VERSION ""

NS_ :

BS_:

BU_: JetXCI1 Bordrechner4 Bordrechner3 Bordrechner2 Bordrechner1 Hydrop_Joystick JetEIM1_JIM1_2 JetEIM1_JIM1_1 JetEIM1_JIM1_0 Getriebe2 Getriebe1 Getriebe0 Retarder_Motor Motor Bordrechner0 Luefter
VAL_TABLE_ FMI 31 "Not available" 19 "Received network data in error" 18 "Below normal (moderatels severe)" 17 "Below normal (least severe)" 16 "Above normal (moderately severe)" 15 "Above normal (least severe)" 14 "Special intstructions" 13 "Out of calibration" 12 "Bad intelligent device" 11 "Root cause not known" 10 "Abnormal rate of change" 9 "Abnormal update rate" 8 "Abnormal frequency" 7 "Mechanical system not responding" 6 "Current above normal" 5 "Current below normal" 4 "Voltage below normal" 3 "Voltage above normal" 2 "Data erratic" 1 "Below normal (most severe)" 0 "Above normal (most severe)" ;
VAL_TABLE_ VehicleSystem_IG1 2 "Trailer" 1 "Tractor" 127 "Not Available" 0 "Non-specific System" ;
VAL_TABLE_ VehicleSystem_IG0 0 "Non-specific System" 127 "Not Available" ;
VAL_TABLE_ VehicleSystem_IG5 127 "Not Available" 0 "Ind. Process Control Stationary" ;
VAL_TABLE_ VehicleSystem_IG4 100 "Deck/Cargo/Fishing equip. sys" 90 "Environmental (HVAC) Systems" 80 "Instrumentation/General Systems" 70 "Communications Systems" 60 "Navigation Systems" 50 "Propulsion Systems" 40 "Steering Systems" 30 "Power Mgmt and lighting systems" 25 "Gateway" 20 "Safety Systems" 10 "System Tools" 127 "Not Available" 0 "Non-specific System" ;
VAL_TABLE_ VehicleSystem_IG3 8 "Grader" 7 "Four Wheel Drive Loader" 6 "Forklift" 5 "Excavator" 4 "Crawler" 3 "Backhoe" 2 "Articulated Dump Truck" 1 "Skid Steer Loader" 127 "Not Available" 0 "Non-specific System" ;
VAL_TABLE_ VehicleSystem_IG2 16 "Skidder" 15 "Earth Work" 14 "Special Crops" 13 "Powered Auxiliary Device" 12 "Farm Yard Operations" 11 "Transport/Trailer" 10 "Irrigation" 9 "Forage" 8 "Root Harvesters" 7 "Harvesters" 6 "Sprayers" 5 "Fertilizers" 4 "Planters/Seeders" 3 "Secondary Tillage" 2 "Tillage" 1 "Tractor" 127 "Not Available" 0 "Non-specific System" ;

BO_ 3221225472 VECTOR__INDEPENDENT_SIG_MSG: 0 Vector__XXX
 SG_ MessageCounter : 0|4@1+ (1,0) [0|0] "" Vector__XXX
 SG_ MessageChecksum : 0|4@1+ (1,0) [0|0] "" Vector__XXX
 SG_ NeuesSignal_536 : 0|8@1- (1,0) [0|0] "" Vector__XXX
 SG_ OverTemperatureWarningFlag : 0|2@1+ (1,0) [0|0] "" Vector__XXX
 SG_ Gear_oil_temperature_limit_L : 0|1@1+ (1,0) [0|0] "" Vector__XXX
 SG_ ExhaustGasMass : 0|16@1+ (2,0) [0|128510] "kg" Vector__XXX
 SG_ AftrTrtmntIntakeDewPointMessage : 0|2@1+ (1,0) [0|3] "" Vector__XXX
 SG_ AftrTrtmntExhustDewPointMessage : 0|2@1+ (1,0) [0|3] "" Vector__XXX
 SG_ EngTurboBoostPress : 0|8@1+ (2,0) [0|500] "kPa" Vector__XXX
 SG_ DTC5 : 0|32@1+ (1,0) [0|4294967295] "" Vector__XXX
 SG_ DTC4 : 0|32@1+ (1,0) [0|4294967295] "" Vector__XXX
 SG_ DTC3 : 0|32@1+ (1,0) [0|4294967295] "" Vector__XXX
 SG_ DTC2 : 0|32@1+ (1,0) [0|4294967295] "" Vector__XXX
 SG_ DTC1 : 0|32@1+ (1,0) [0|4294967295] "" Vector__XXX
 SG_ ExhaustGasMass : 0|16@1+ (2,0) [0|128510] "kg" Vector__XXX
 SG_ AftrTrtmntIntakeDewPointMessage : 0|2@1+ (1,0) [0|3] "" Vector__XXX
 SG_ AftrTrtmntExhustDewPointMessage : 0|2@1+ (1,0) [0|3] "" Vector__XXX
 SG_ EstEngPrsticLossesPercentTorque : 0|8@1+ (1,-125) [-125|125] "%" Vector__XXX
 SG_ EngsDsrdOprtngSpdAsymmtryAdjstmn : 0|8@1+ (1,0) [0|250] "" Vector__XXX
 SG_ EngsDesiredOperatingSpeed : 0|16@1+ (0.125,0) [0|8031.875] "RPM" Vector__XXX
 SG_ NominalFrictionPercentTorque : 0|8@1+ (1,-125) [-125|125] "%" Vector__XXX
 SG_ ExhaustGasMass : 0|16@1+ (2,0) [0|128510] "kg" Vector__XXX
 SG_ AftrTrtmntIntakeDewPointMessage : 0|2@1+ (1,0) [0|3] "" Vector__XXX
 SG_ AftrTrtmntExhustDewPointMessage : 0|2@1+ (1,0) [0|3] "" Vector__XXX
 SG_ EstEngPrsticLossesPercentTorque : 0|8@1+ (1,-125) [-125|125] "%" Vector__XXX
 SG_ EngsDsrdOprtngSpdAsymmtryAdjstmn : 0|8@1+ (1,0) [0|250] "" Vector__XXX
 SG_ EngsDesiredOperatingSpeed : 0|16@1+ (0.125,0) [0|8031.875] "RPM" Vector__XXX
 SG_ NominalFrictionPercentTorque : 0|8@1+ (1,-125) [-125|125] "%" Vector__XXX
 SG_ AddressAcknowledged : 0|8@1+ (1,0) [0|255] "" Vector__XXX
 SG_ OperatorPTOMemorySelectSwitch : 0|2@1+ (1,0) [0|3] "" Vector__XXX
 SG_ EngPTOAccelerateSwitch : 0|2@1+ (1,0) [0|3] "" Vector__XXX
 SG_ EngPTOResumeSwitch : 0|2@1+ (1,0) [0|3] "" Vector__XXX
 SG_ EngPTOCoast_DecelerateSwitch : 0|2@1+ (1,0) [0|3] "" Vector__XXX
 SG_ EngRmtPTOVriableSpeedCtrlSwitch : 0|2@1+ (1,0) [0|3] "" Vector__XXX
 SG_ EngRmtPTOPrprgrmmdSpdCtrlSwitch : 0|2@1+ (1,0) [0|3] "" Vector__XXX
 SG_ PowerTakeoffSetSpeed : 0|16@1+ (0.125,0) [0|8031.875] "RPM" Vector__XXX
 SG_ PowerTakeoffSpeed : 0|16@1+ (0.125,0) [0|8031.875] "RPM" Vector__XXX
 SG_ PowerTakeoffOilTemp : 0|8@1+ (1,-40) [-40|210] "�C" Vector__XXX
 SG_ RmtPTOPrprgrmmdSpeedCtrlSwitch2 : 0|2@1+ (1,0) [0|3] "" Vector__XXX
 SG_ AuxInputIgnoreSwitch : 0|2@1+ (1,0) [0|3] "" Vector__XXX
 SG_ Make : 0|8@1+ (1,0) [0|255] "" Vector__XXX
 SG_ DTC1 : 0|32@1+ (1,0) [0|4294967295] "" Vector__XXX

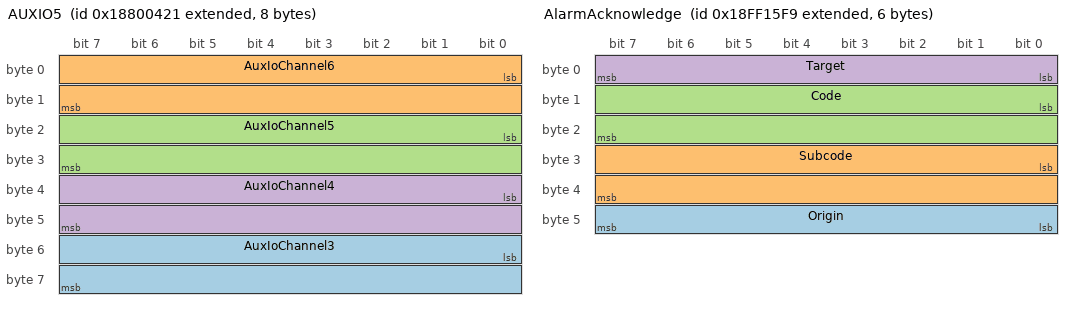
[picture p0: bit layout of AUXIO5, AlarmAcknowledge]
BO_ 2558526497 AUXIO5: 8 Bordrechner0
 SG_ AuxIoChannel3 : 48|16@1+ (1,0) [0|65535] ""  Getriebe1
 SG_ AuxIoChannel6 : 0|16@1+ (1,0) [0|0] ""  Getriebe1
 SG_ AuxIoChannel5 : 16|16@1+ (1,0) [0|65535] ""  Getriebe1
 SG_ AuxIoChannel4 : 32|16@1+ (1,0) [0|65535] ""  Getriebe1

BO_ 2364535040 KWP: 2 Motor
 SG_ Instruction : 8|8@1+ (1,0) [0|0] ""  Motor,Bordrechner4,Bordrechner3,Bordrechner2,Bordrechner1
 SG_ DestinationIdentifier : 0|8@1+ (1,0) [0|0] ""  Motor,Bordrechner4,Bordrechner3,Bordrechner2,Bordrechner1

BO_ 2364538622 ESS: 1 Vector__XXX
 SG_ ShutDownOverride : 8|2@1+ (1,0) [0|3] "" Vector__XXX
 SG_ EngineStart : 2|2@1+ (1,0) [0|0] "" Vector__XXX
 SG_ InhibitFuelInjection : 0|2@1+ (1,0) [0|3] "" Vector__XXX
 SG_ InhibitEngineStart : 4|2@1+ (1,0) [0|0] "" Vector__XXX

BO_ 2564488958 BODAS: 8 Luefter

BO_ 2365534851 JoystickAuxiliaryInput: 1 Hydrop_Joystick
 SG_ Pushbutton2 : 2|2@1+ (1,0) [0|3] ""  JetXCI1
 SG_ Pushbutton1 : 0|2@1+ (1,0) [0|0] ""  JetXCI1

BO_ 2566854398 EnumerateSystem: 8 Bordrechner1

BO_ 2566854137 AlarmAcknowledge: 6 Bordrechner1
 SG_ Origin : 40|8@1+ (1,0) [0|0] ""  JetXCI1,JetEIM1_JIM1_2,JetEIM1_JIM1_1,JetEIM1_JIM1_0
 SG_ Subcode : 24|16@1+ (1,0) [0|65535] ""  JetXCI1,JetEIM1_JIM1_2,JetEIM1_JIM1_1,JetEIM1_JIM1_0
 SG_ Code : 8|16@1+ (1,0) [0|65535] ""  JetXCI1,JetEIM1_JIM1_2,JetEIM1_JIM1_1,JetEIM1_JIM1_0
 SG_ Target : 0|8@1+ (1,0) [0|0] ""  JetXCI1,JetEIM1_JIM1_2,JetEIM1_JIM1_1,JetEIM1_JIM1_0

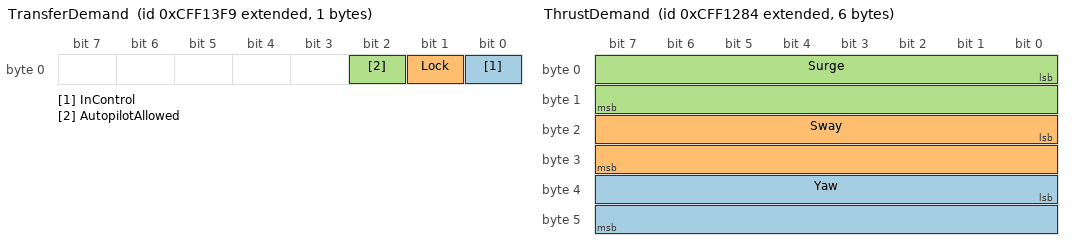
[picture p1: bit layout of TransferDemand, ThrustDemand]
BO_ 2365527033 TransferDemand: 1 Bordrechner1
 SG_ InControl : 0|1@1+ (1,0) [0|1] "" Vector__XXX
 SG_ Lock : 1|1@1+ (1,0) [0|0] "" Vector__XXX
 SG_ AutopilotAllowed : 2|1@1+ (1,0) [0|0] "" Vector__XXX

BO_ 2365527038 TransmissionDemand: 2 Vector__XXX
 SG_ Position : 8|4@1+ (1,0) [0|0] "" Vector__XXX
 SG_ Target : 0|8@1+ (1,0) [0|0] "" Vector__XXX

BO_ 2365526660 ThrustDemand: 6 Hydrop_Joystick
 SG_ Yaw : 32|16@1+ (0.0030517,-100) [0|0] ""  JetXCI1
 SG_ Sway : 16|16@1+ (1,0) [0|0] ""  JetXCI1
 SG_ Surge : 0|16@1+ (0.0030517,-100) [0|0] ""  JetXCI1

BO_ 2365526224 WaterjetReverseDemand: 4 JetXCI1
 SG_ PositionPercent : 8|16@1+ (0.0030517,-100) [-100|100] ""  JetEIM1_JIM1_2,JetEIM1_JIM1_1,JetEIM1_JIM1_0
 SG_ Target : 0|8@1+ (1,0) [0|0] ""  JetEIM1_JIM1_2,JetEIM1_JIM1_1,JetEIM1_JIM1_0

BO_ 2365525968 WaterjetSteeringDemand: 3 JetXCI1
 SG_ PositionPercent : 8|16@1+ (0.0030517,-100) [-100|100] ""  JetEIM1_JIM1_2,JetEIM1_JIM1_1,JetEIM1_JIM1_0
 SG_ Target : 0|8@1+ (1,0) [0|0] ""  JetEIM1_JIM1_2,JetEIM1_JIM1_1,JetEIM1_JIM1_0

BO_ 2365526480 EngineDemand: 4 JetXCI1
 SG_ PositionPercent : 8|16@1+ (0.0030517,-100) [-100|100] ""  JetEIM1_JIM1_2,JetEIM1_JIM1_1,JetEIM1_JIM1_0
 SG_ Target : 0|8@1+ (1,0) [0|0] ""  JetEIM1_JIM1_2,JetEIM1_JIM1_1,JetEIM1_JIM1_0

BO_ 2566852304 AlarmText: 9 JetEIM1_JIM1_0
 SG_ Text : 40|24@1+ (1,0) [0|0] "" Vector__XXX
 SG_ Origin : 32|8@1+ (1,0) [0|0] ""  Bordrechner4,Bordrechner3,Bordrechner2,Bordrechner1,Bordrechner0
 SG_ Subcode : 16|16@1+ (1,0) [0|65535] ""  Bordrechner4,Bordrechner3,Bordrechner2,Bordrechner1,Bordrechner0
 SG_ Code : 0|16@1+ (1,0) [0|65535] ""  Bordrechner4,Bordrechner3,Bordrechner2,Bordrechner1,Bordrechner0

BO_ 2499743184 Alarm: 9 JetEIM1_JIM1_0
 SG_ Severity : 40|4@1+ (1,0) [0|0] ""  Bordrechner4,Bordrechner3,Bordrechner2,Bordrechner1,Bordrechner0
 SG_ Acknowledged : 44|1@1+ (1,0) [0|0] ""  Bordrechner4,Bordrechner3,Bordrechner2,Bordrechner1,Bordrechner0
 SG_ Cleared : 45|1@1+ (1,0) [0|0] ""  Bordrechner4,Bordrechner3,Bordrechner2,Bordrechner1,Bordrechner0
 SG_ Silenced : 46|1@1+ (1,0) [0|0] ""  Bordrechner4,Bordrechner3,Bordrechner2,Bordrechner1,Bordrechner0
 SG_ Retriggered : 47|1@1+ (1,0) [0|0] ""  Bordrechner4,Bordrechner3,Bordrechner2,Bordrechner1,Bordrechner0
 SG_ Origin : 32|8@1+ (1,0) [0|0] ""  Bordrechner4,Bordrechner3,Bordrechner2,Bordrechner1,Bordrechner0
 SG_ Subcode : 16|16@1+ (1,0) [0|65535] ""  Bordrechner4,Bordrechner3,Bordrechner2,Bordrechner1,Bordrechner0
 SG_ Code : 0|16@1+ (1,0) [0|65535] ""  Bordrechner4,Bordrechner3,Bordrechner2,Bordrechner1,Bordrechner0

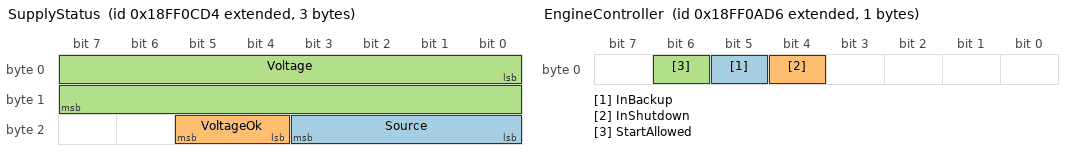
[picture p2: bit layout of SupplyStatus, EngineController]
BO_ 2566851796 SupplyStatus: 3 JetEIM1_JIM1_1
 SG_ Source : 16|4@1+ (1,0) [0|0] "" Vector__XXX
 SG_ VoltageOk : 20|2@1+ (1,0) [0|3] "" Vector__XXX
 SG_ Voltage : 0|16@1+ (0.05,0) [0|0] "V" Vector__XXX

BO_ 2566851286 EngineController: 1 JetEIM1_JIM1_2
 SG_ InBackup : 5|1@1+ (1,0) [0|1] "" Vector__XXX
 SG_ InShutdown : 4|1@1+ (1,0) [0|1] "" Vector__XXX
 SG_ StartAllowed : 6|1@1+ (1,0) [0|1] "" Vector__XXX

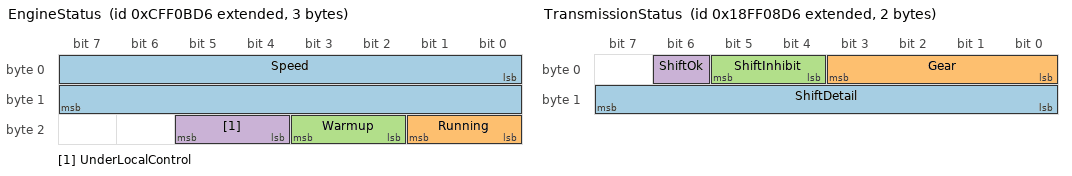
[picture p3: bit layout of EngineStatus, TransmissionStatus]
BO_ 2365524950 EngineStatus: 3 JetEIM1_JIM1_2
 SG_ Speed : 0|16@1+ (0.125,0) [0|0] "RPM" Vector__XXX
 SG_ Running : 16|2@1+ (1,0) [0|3] "" Vector__XXX
 SG_ Warmup : 18|2@1+ (1,0) [0|3] "" Vector__XXX
 SG_ UnderLocalControl : 20|2@1+ (1,0) [0|0] "" Vector__XXX

BO_ 2365524436 ShaftStatus: 3 JetEIM1_JIM1_1
 SG_ Direction : 16|4@1+ (1,0) [0|0] "" Vector__XXX
 SG_ Speed : 0|16@1+ (0.125,0) [0|0] "RPM" Vector__XXX

BO_ 2566850774 TransmissionStatus: 2 JetEIM1_JIM1_2
 SG_ ShiftDetail : 8|8@1+ (1,0) [0|0] "" Vector__XXX
 SG_ Gear : 0|4@1+ (1,0) [0|0] "" Vector__XXX
 SG_ ShiftInhibit : 4|2@1+ (1,0) [0|0] "" Vector__XXX
 SG_ ShiftOk : 6|1@1+ (1,0) [0|1] "" Vector__XXX

BO_ 2566850516 WaterjetController: 1 JetEIM1_JIM1_1
 SG_ InBackup : 0|1@1+ (1,0) [0|1] "" Vector__XXX

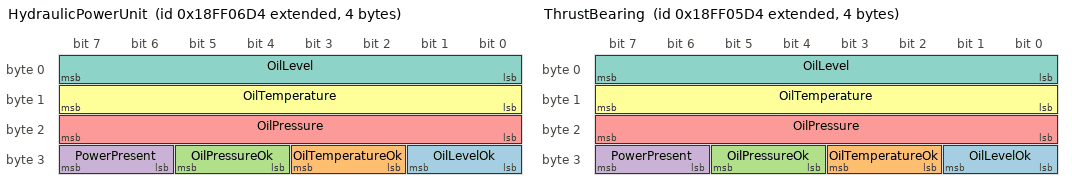
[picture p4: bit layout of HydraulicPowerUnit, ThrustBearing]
BO_ 2566850260 HydraulicPowerUnit: 4 JetEIM1_JIM1_1
 SG_ OilLevelOk : 24|2@1+ (1,0) [0|3] "" Vector__XXX
 SG_ OilTemperatureOk : 26|2@1+ (1,0) [0|3] "" Vector__XXX
 SG_ OilPressureOk : 28|2@1+ (1,0) [0|0] "" Vector__XXX
 SG_ PowerPresent : 30|2@1+ (1,0) [0|3] "" Vector__XXX
 SG_ OilPressure : 16|8@1- (0.1,0) [0|0] "kPa" Vector__XXX
 SG_ OilTemperature : 8|8@1- (1,-40) [0|0] "�C" Vector__XXX
 SG_ OilLevel : 0|8@1+ (1,0) [0|250] "%" Vector__XXX

BO_ 2566850004 ThrustBearing: 4 JetEIM1_JIM1_1
 SG_ OilLevelOk : 24|2@1+ (1,0) [0|3] "" Vector__XXX
 SG_ OilTemperatureOk : 26|2@1+ (1,0) [0|3] "" Vector__XXX
 SG_ OilPressureOk : 28|2@1+ (1,0) [0|0] "" Vector__XXX
 SG_ PowerPresent : 30|2@1+ (1,0) [0|3] "" Vector__XXX
 SG_ OilPressure : 16|8@1- (0.1,0) [0|0] "kPa" Vector__XXX
 SG_ OilTemperature : 8|8@1- (1,-40) [0|0] "�C" Vector__XXX
 SG_ OilLevel : 0|8@1+ (1,0) [0|250] "%" Vector__XXX

BO_ 2365523156 WaterjetReverseStatus: 4 JetEIM1_JIM1_1
 SG_ PositionPercent : 0|16@1+ (0.0030517,-100) [-100|100] "" Vector__XXX
 SG_ LinearPosition : 16|16@1+ (0.0030517,-100) [0|0] "%" Vector__XXX

BO_ 2365522900 WaterjetSteeringStatus: 2 JetEIM1_JIM1_1
 SG_ PositionPercent : 0|16@1+ (0.0030517,-100) [-100|100] "" Vector__XXX

BO_ 2566849232 AutopilotStatus: 4 JetXCI1
 SG_ Engaged : 16|2@1+ (1,0) [0|3] ""  Bordrechner4,Bordrechner3,Bordrechner2,Bordrechner1
 SG_ Order : 0|16@1+ (0.0030517,-100) [-100|99.9931595] "%"  Bordrechner4,Bordrechner3,Bordrechner2,Bordrechner1

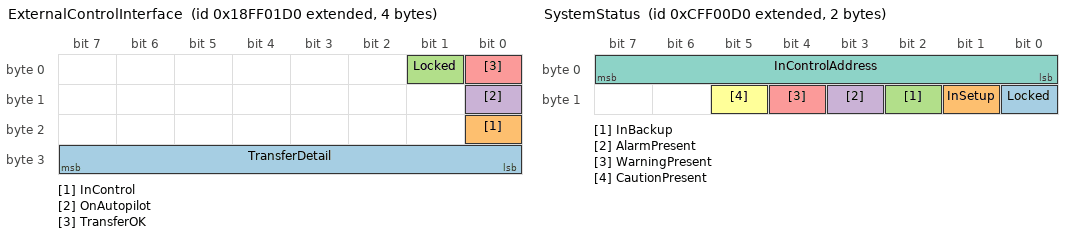
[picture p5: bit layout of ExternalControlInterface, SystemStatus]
BO_ 2566848976 ExternalControlInterface: 4 JetXCI1
 SG_ TransferDetail : 24|8@1+ (1,0) [0|255] ""  Bordrechner4,Bordrechner3,Bordrechner2,Bordrechner1
 SG_ InControl : 16|1@1+ (1,0) [0|1] ""  Bordrechner4,Bordrechner3,Bordrechner2,Bordrechner1
 SG_ Locked : 1|1@1+ (1,0) [0|1] ""  Bordrechner4,Bordrechner3,Bordrechner2,Bordrechner1
 SG_ OnAutopilot : 8|1@1+ (1,0) [0|1] ""  Bordrechner4,Bordrechner3,Bordrechner2,Bordrechner1
 SG_ TransferOK : 0|1@1+ (1,0) [0|1] ""  Bordrechner4,Bordrechner3,Bordrechner2,Bordrechner1

BO_ 2365522128 SystemStatus: 2 JetXCI1
 SG_ Locked : 8|1@1+ (1,0) [0|1] ""  Bordrechner4,Bordrechner3,Bordrechner2,Bordrechner1
 SG_ InSetup : 9|1@1+ (1,0) [0|1] ""  Bordrechner4,Bordrechner3,Bordrechner2,Bordrechner1
 SG_ InBackup : 10|1@1+ (1,0) [0|1] ""  Bordrechner4,Bordrechner3,Bordrechner2,Bordrechner1
 SG_ AlarmPresent : 11|1@1+ (1,0) [0|1] ""  Bordrechner4,Bordrechner3,Bordrechner2,Bordrechner1
 SG_ WarningPresent : 12|1@1+ (1,0) [0|1] ""  Bordrechner4,Bordrechner3,Bordrechner2,Bordrechner1
 SG_ CautionPresent : 13|1@1+ (1,0) [0|0] ""  Bordrechner4,Bordrechner3,Bordrechner2,Bordrechner1
 SG_ InControlAddress : 0|8@1+ (1,0) [0|251] ""  Bordrechner4,Bordrechner3,Bordrechner2,Bordrechner1

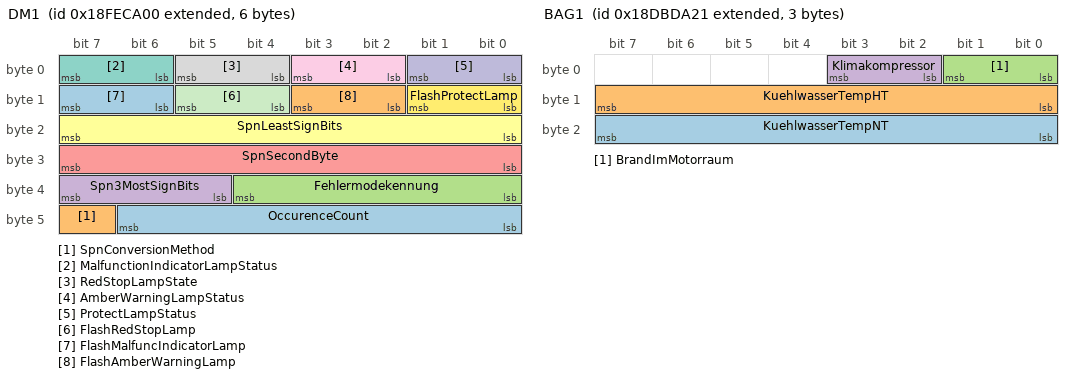
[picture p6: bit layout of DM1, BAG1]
BO_ 2566834688 DM1: 6 Motor
 SG_ OccurenceCount : 40|7@1+ (1,0) [0|0] ""  Bordrechner0
 SG_ SpnConversionMethod : 47|1@1+ (1,0) [0|0] ""  Bordrechner0
 SG_ Fehlermodekennung : 32|5@1+ (1,0) [0|0] ""  Bordrechner0
 SG_ Spn3MostSignBits : 37|3@1+ (1,0) [0|0] ""  Bordrechner0
 SG_ SpnSecondByte : 24|8@1+ (1,0) [0|255] ""  Bordrechner0
 SG_ SpnLeastSignBits : 16|8@1+ (1,0) [0|255] ""  Bordrechner0
 SG_ MalfunctionIndicatorLampStatus : 6|2@1+ (1,0) [0|3] "" Vector__XXX
 SG_ RedStopLampState : 4|2@1+ (1,0) [0|3] ""  Bordrechner0
 SG_ AmberWarningLampStatus : 2|2@1+ (1,0) [0|3] ""  Bordrechner0
 SG_ ProtectLampStatus : 0|2@1+ (1,0) [0|3] "" Vector__XXX
 SG_ FlashRedStopLamp : 12|2@1+ (1,0) [0|3] "" Vector__XXX
 SG_ FlashProtectLamp : 8|2@1+ (1,0) [0|3] "" Vector__XXX
 SG_ FlashMalfuncIndicatorLamp : 14|2@1+ (1,0) [0|3] "" Vector__XXX
 SG_ FlashAmberWarningLamp : 10|2@1+ (1,0) [0|3] "" Vector__XXX

BO_ 2564545057 BAG1: 3 Bordrechner0
 SG_ KuehlwasserTempNT : 16|8@1+ (1,-40) [-40|210] "�C"  Luefter
 SG_ KuehlwasserTempHT : 8|8@1- (1,-40) [-40|210] "�C"  Luefter
 SG_ BrandImMotorraum : 0|2@1+ (1,0) [0|3] ""  Luefter
 SG_ Klimakompressor : 2|2@1+ (1,0) [0|3] ""  Luefter

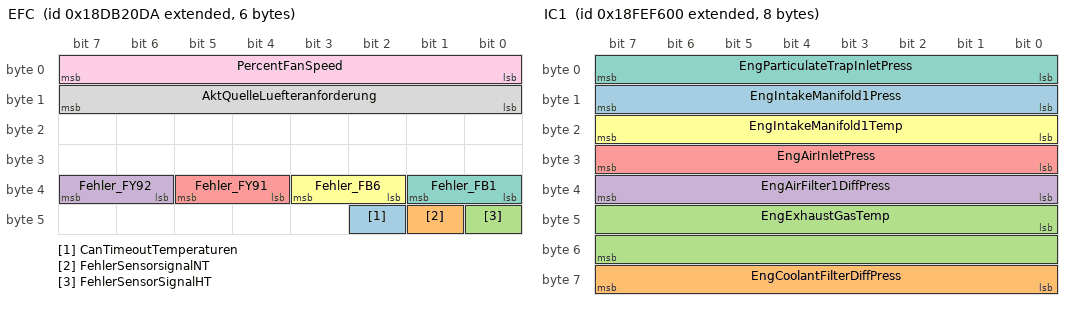
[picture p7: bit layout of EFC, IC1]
BO_ 2564497626 EFC: 6 Luefter
 SG_ CanTimeoutTemperaturen : 42|1@1+ (1,0) [0|1] ""  Bordrechner0
 SG_ FehlerSensorsignalNT : 41|1@1+ (1,0) [0|1] ""  Bordrechner0
 SG_ FehlerSensorSignalHT : 40|1@1+ (1,0) [0|1] ""  Bordrechner0
 SG_ Fehler_FY92 : 38|2@1+ (1,0) [0|3] ""  Bordrechner0
 SG_ Fehler_FY91 : 36|2@1+ (1,0) [0|3] ""  Bordrechner0
 SG_ Fehler_FB6 : 34|2@1+ (1,0) [0|3] ""  Bordrechner0
 SG_ Fehler_FB1 : 32|2@1+ (1,0) [0|3] ""  Bordrechner0
 SG_ AktQuelleLuefteranforderung : 8|8@1+ (1,0) [0|255] ""  Bordrechner0
 SG_ PercentFanSpeed : 0|8@1+ (0.4,0) [0|100] "%"  Bordrechner0

BO_ 2566845952 IC1: 8 Motor
 SG_ EngIntakeManifold1Press : 8|8@1- (2,0) [0|0] "kPa" Vector__XXX
 SG_ EngCoolantFilterDiffPress : 56|8@1+ (0.5,0) [0|125] "kPa" Vector__XXX
 SG_ EngExhaustGasTemp : 40|16@1+ (0.03125,-273) [-273|1735] "�C" Vector__XXX
 SG_ EngAirFilter1DiffPress : 32|8@1+ (0.05,0) [0|12.5] "kPa" Vector__XXX
 SG_ EngAirInletPress : 24|8@1+ (2,0) [0|500] "kPa" Vector__XXX
 SG_ EngIntakeManifold1Temp : 16|8@1+ (1,-40) [-40|210] "�C"  Luefter
 SG_ EngParticulateTrapInletPress : 0|8@1+ (0.5,0) [0|125] "kPa" Vector__XXX

BO_ 2566841854 HOURS: 8 Motor
 SG_ EngTotalRevolutions : 32|32@1+ (1000,0) [0|4211081215000] "rev" Vector__XXX
 SG_ EngTotalHoursOfOperation : 0|32@1+ (0.05,0) [0|210554060.75] "hr" Vector__XXX

BO_ 2566832638 VDHR: 8 Vector__XXX
 SG_ HighResolutionTripDistance : 32|32@1+ (0.005,0) [0|21055406] "km" Vector__XXX
 SG_ HghRslutionTotalVehicleDistance : 0|32@1+ (0.005,0) [0|21055406] "km" Vector__XXX

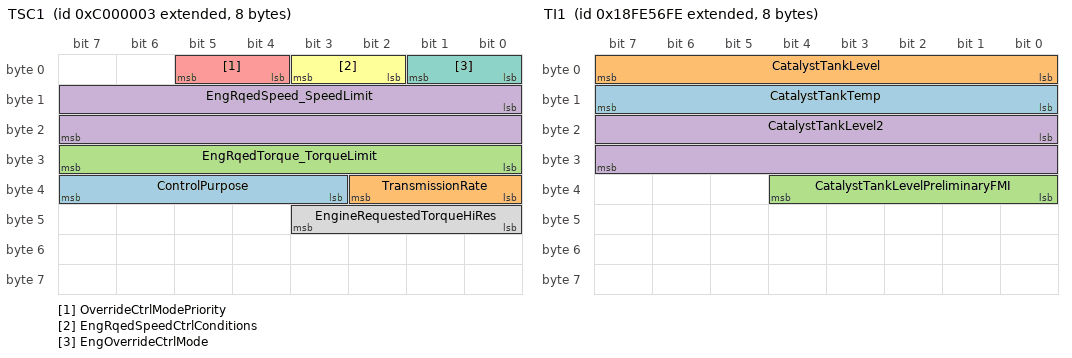
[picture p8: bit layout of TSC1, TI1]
BO_ 2348810243 TSC1: 8 Getriebe0
 SG_ ControlPurpose : 35|5@1+ (1,0) [0|31] ""  Getriebe0,Retarder_Motor,Motor
 SG_ TransmissionRate : 32|3@1+ (1,0) [0|7] ""  Getriebe0,Retarder_Motor,Motor
 SG_ EngRqedTorque_TorqueLimit : 24|8@1+ (1,-125) [-125|125] "%"  Getriebe0,Retarder_Motor,Motor
 SG_ EngRqedSpeed_SpeedLimit : 8|16@1+ (0.125,0) [0|8031.875] "RPM"  Getriebe0,Retarder_Motor,Motor
 SG_ OverrideCtrlModePriority : 4|2@1+ (1,0) [0|3] ""  Getriebe0,Retarder_Motor,Motor
 SG_ EngRqedSpeedCtrlConditions : 2|2@1+ (1,0) [0|3] ""  Getriebe0,Retarder_Motor,Motor
 SG_ EngOverrideCtrlMode : 0|2@1+ (1,0) [0|3] ""  Getriebe0,Retarder_Motor,Motor
 SG_ EngineRequestedTorqueHiRes : 40|4@1+ (0.125,0) [0|0.875] "%"  Getriebe0,Retarder_Motor,Motor

BO_ 2566805246 TI1: 8 Motor
 SG_ CatalystTankTemp : 8|8@1+ (1,-40) [-40|210] "�C" Vector__XXX
 SG_ CatalystTankLevel : 0|8@1+ (0.4,0) [0|100] "%" Vector__XXX
 SG_ CatalystTankLevelPreliminaryFMI : 32|5@1+ (1,0) [0|31] "" Vector__XXX
 SG_ CatalystTankLevel2 : 16|16@1+ (0.1,0) [0|6425.5] "mm" Vector__XXX

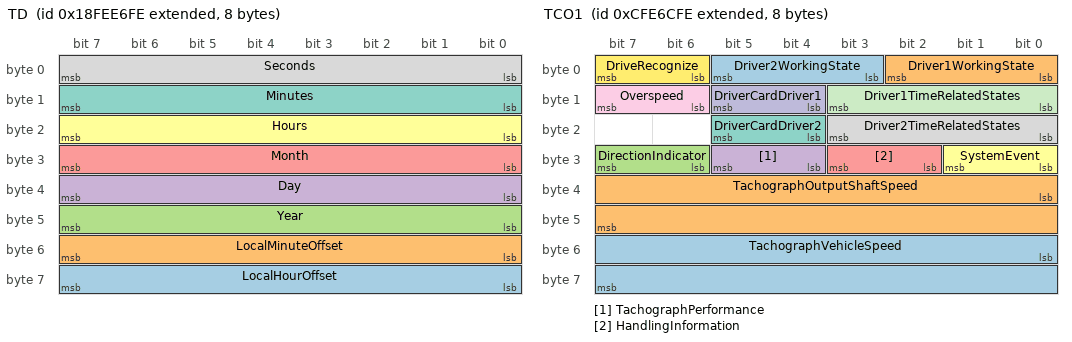
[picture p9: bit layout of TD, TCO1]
BO_ 2566842110 TD: 8 Bordrechner0
 SG_ LocalHourOffset : 56|8@1+ (1,-125) [-125|125] "hr" Vector__XXX
 SG_ LocalMinuteOffset : 48|8@1+ (1,-125) [-125|125] "mins" Vector__XXX
 SG_ Year : 40|8@1+ (1,1985) [1985|2235] "years"  Getriebe0
 SG_ Day : 32|8@1+ (0.25,0) [0|62.5] "days"  Getriebe0
 SG_ Month : 24|8@1+ (1,0) [0|250] "months"  Getriebe0
 SG_ Hours : 16|8@1+ (1,0) [0|250] "hr"  Getriebe0
 SG_ Minutes : 8|8@1+ (1,0) [0|250] "mins"  Getriebe0
 SG_ Seconds : 0|8@1+ (0.25,0) [0|62.5] "sec"  Getriebe0

BO_ 2365484286 TCO1: 8 Vector__XXX
 SG_ TachographVehicleSpeed : 48|16@1+ (0.00390625,0) [0|250.996] "km/hr" Vector__XXX
 SG_ TachographOutputShaftSpeed : 32|16@1+ (0.125,0) [0|8031.875] "RPM" Vector__XXX
 SG_ DirectionIndicator : 30|2@1+ (1,0) [0|3] "" Vector__XXX
 SG_ TachographPerformance : 28|2@1+ (1,0) [0|3] "" Vector__XXX
 SG_ HandlingInformation : 26|2@1+ (1,0) [0|3] "" Vector__XXX
 SG_ SystemEvent : 24|2@1+ (1,0) [0|3] "" Vector__XXX
 SG_ DriverCardDriver2 : 20|2@1+ (1,0) [0|3] "" Vector__XXX
 SG_ Driver2TimeRelatedStates : 16|4@1+ (1,0) [0|15] "" Vector__XXX
 SG_ Overspeed : 14|2@1+ (1,0) [0|3] "" Vector__XXX
 SG_ DriverCardDriver1 : 12|2@1+ (1,0) [0|3] "" Vector__XXX
 SG_ Driver1TimeRelatedStates : 8|4@1+ (1,0) [0|15] "" Vector__XXX
 SG_ DriveRecognize : 6|2@1+ (1,0) [0|3] "" Vector__XXX
 SG_ Driver2WorkingState : 3|3@1+ (1,0) [0|7] "" Vector__XXX
 SG_ Driver1WorkingState : 0|3@1+ (1,0) [0|7] "" Vector__XXX

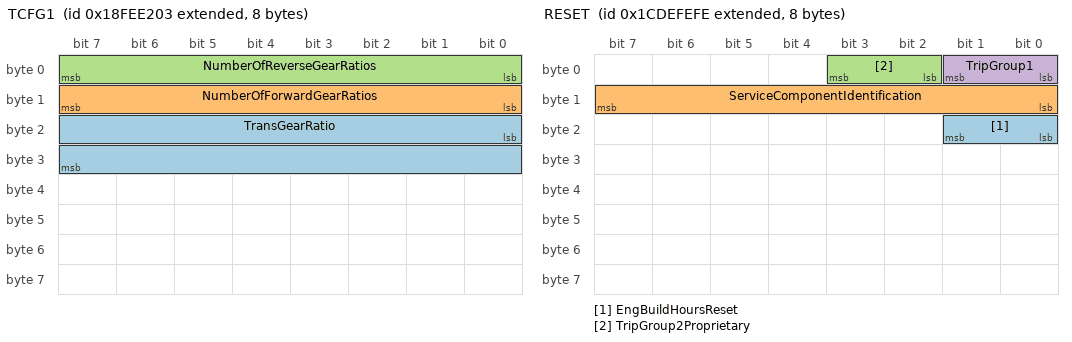
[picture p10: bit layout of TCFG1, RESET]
BO_ 2566840835 TCFG1: 8 Getriebe0
 SG_ TransGearRatio : 16|16@1+ (0.001,0) [0|64.255] "" Vector__XXX
 SG_ NumberOfForwardGearRatios : 8|8@1+ (1,0) [0|250] "" Vector__XXX
 SG_ NumberOfReverseGearRatios : 0|8@1+ (1,0) [0|250] "" Vector__XXX

BO_ 2348876577 TC1: 8 Bordrechner0
 SG_ TransMode8 : 62|2@1+ (1,0) [0|3] "" Vector__XXX
 SG_ TransMode7 : 60|2@1+ (1,0) [0|3] "" Vector__XXX
 SG_ TransMode6 : 58|2@1+ (1,0) [0|3] "" Vector__XXX
 SG_ TransMode5 : 56|2@1+ (1,0) [0|3] "" Vector__XXX
 SG_ TransReqLaunchGear : 52|2@1+ (1,0) [0|0] "" Vector__XXX
 SG_ TransRevGearShfitInhibitRq : 6|2@1+ (1,0) [0|3] "" Vector__XXX
 SG_ TrnsShftSlctorDisplayModeSwitch : 54|2@1+ (1,0) [0|3] ""  Getriebe0
 SG_ TransMode4 : 46|2@1+ (1,0) [0|3] ""  Getriebe0
 SG_ TransMode3 : 44|2@1+ (1,0) [0|3] ""  Getriebe0
 SG_ TransMode2 : 42|2@1+ (1,0) [0|3] ""  Getriebe0
 SG_ TransMode1 : 40|2@1+ (1,0) [0|3] ""  Getriebe0
 SG_ DisengageDiffLockRqCentralRear : 36|2@1+ (1,0) [0|3] ""  Getriebe0
 SG_ DisengageDiffLockRqCentralFront : 34|2@1+ (1,0) [0|3] ""  Getriebe0
 SG_ DisengageDiffLockRqCentral : 32|2@1+ (1,0) [0|3] ""  Getriebe0
 SG_ DisengageDiffLockRqRearAxle2 : 30|2@1+ (1,0) [0|3] ""  Getriebe0
 SG_ DisengageDiffLockRqRearAxle1 : 28|2@1+ (1,0) [0|3] ""  Getriebe0
 SG_ DisengageDiffLockRqFrontAxle2 : 26|2@1+ (1,0) [0|3] ""  Getriebe0
 SG_ DisengageDiffLockRqFrontAxle1 : 24|2@1+ (1,0) [0|3] ""  Getriebe0
 SG_ TransRqedGear : 16|8@1+ (1,-125) [-125|125] ""  Getriebe0
 SG_ RqedPercentClutchSlip : 8|8@1+ (0.4,0) [0|100] "%"  Getriebe0
 SG_ DisengageDrivelineRq : 4|2@1+ (1,0) [0|3] ""  Getriebe0
 SG_ TorqueConverterLockupDisableRq : 2|2@1+ (1,0) [0|3] ""  Getriebe0
 SG_ TransGearShiftInhibitRq : 0|2@1+ (1,0) [0|3] ""  Getriebe0

BO_ 2566838784 SOFT: 7 Motor
 SG_ Delimiter0 : 56|8@1+ (1,0) [0|0] "" Vector__XXX
 SG_ Sub2Version : 48|8@1+ (1,0) [0|0] "" Vector__XXX
 SG_ Sub1Version : 40|8@1+ (1,0) [0|255] "" Vector__XXX
 SG_ SpecialSoftwareVersion : 24|16@1+ (1,0) [0|65535] "" Vector__XXX
 SG_ SoftwareVersion : 8|16@1+ (1,0) [0|65535] "" Vector__XXX
 SG_ NmbrOfSftwrIdentificationFields : 0|8@1+ (1,0) [0|250] "steps" Vector__XXX

BO_ 2566847235 RF: 8 Getriebe0
 SG_ HydRetarderOilTemp : 8|8@1+ (1,-40) [-40|210] "�C"  Bordrechner0
 SG_ HydRetarderPress : 0|8@1+ (16,0) [0|4000] "kPa" Vector__XXX

BO_ 2631859966 RESET: 8 Vector__XXX
 SG_ EngBuildHoursReset : 16|2@1+ (1,0) [0|3] "" Vector__XXX
 SG_ ServiceComponentIdentification : 8|8@1+ (1,0) [0|250] "ID" Vector__XXX
 SG_ TripGroup2Proprietary : 2|2@1+ (1,0) [0|3] "" Vector__XXX
 SG_ TripGroup1 : 0|2@1+ (1,0) [0|3] "" Vector__XXX

BO_ 2566840830 RC: 19 Retarder_Motor
 SG_ PercentTorqueAtPeakTorquePoint5 : 144|8@1+ (1,-125) [-125|125] "%" Vector__XXX
 SG_ ReferenceRetarderTorque : 128|16@1+ (1,0) [0|64255] "Nm" Vector__XXX
 SG_ RetarderSpeedAtPeakTorquePoint5 : 112|16@1+ (0.125,0) [0|8031.875] "RPM" Vector__XXX
 SG_ PercentTorqueAtPoint4 : 104|8@1+ (1,-125) [-125|125] "%" Vector__XXX
 SG_ RetarderSpeedAtPoint4 : 88|16@1+ (0.125,0) [0|8031.875] "RPM" Vector__XXX
 SG_ PercentTorqueAtPoint3 : 80|8@1+ (1,-125) [-125|125] "%" Vector__XXX
 SG_ RetarderSpeedAtPoint3 : 64|16@1+ (0.125,0) [0|8031.875] "RPM" Vector__XXX
 SG_ PercentTorqueAtMaxSpeedPoint2 : 56|8@1+ (1,-125) [-125|125] "%" Vector__XXX
 SG_ MaxRetarderSpeedPoint2 : 40|16@1+ (0.125,0) [0|8031.875] "RPM" Vector__XXX
 SG_ PercentTorqueAtIdlePoint1 : 32|8@1+ (1,-125) [-125|125] "%" Vector__XXX
 SG_ RetarderSpeedAtIdlePoint1 : 16|16@1+ (0.125,0) [0|8031.875] "RPM" Vector__XXX
 SG_ RetarderCtrlMethod : 8|8@1+ (1,0) [0|250] "steps" Vector__XXX
 SG_ RetarderLocation : 4|4@1+ (1,0) [0|15] "" Vector__XXX
 SG_ RetarderType : 0|4@1+ (1,0) [0|15] "" Vector__XXX

BO_ 2566844670 PTO: 7 Motor
 SG_ EngPTOSetSwitch : 48|2@1+ (1,0) [0|3] "" Vector__XXX
 SG_ EngPTOEnableSwitch : 40|2@1+ (1,0) [0|3] "" Vector__XXX

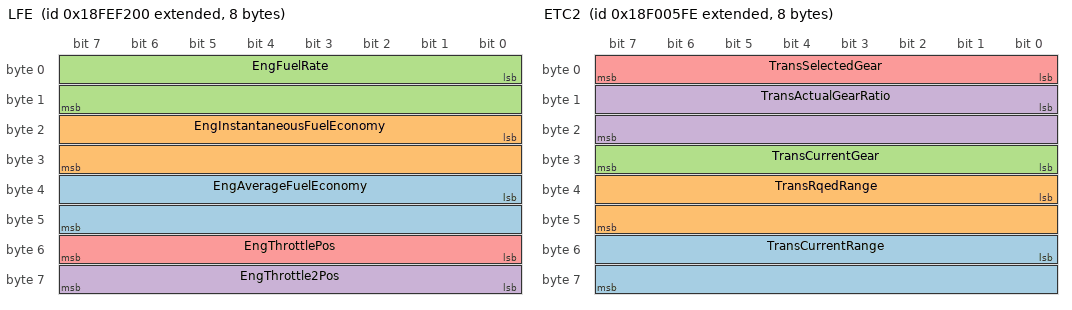
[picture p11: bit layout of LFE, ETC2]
BO_ 2566844928 LFE: 8 Motor
 SG_ EngAverageFuelEconomy : 32|16@1+ (0.001953125,0) [0|125.5] "km/L" Vector__XXX
 SG_ EngInstantaneousFuelEconomy : 16|16@1+ (0.001953125,0) [0|125.5] "km/L" Vector__XXX
 SG_ EngFuelRate : 0|16@1+ (0.05,0) [0|3212.75] "L/hr" Vector__XXX
 SG_ EngThrottle2Pos : 56|8@1+ (0.4,0) [0|100] "%" Vector__XXX
 SG_ EngThrottlePos : 48|8@1+ (0.4,0) [0|100] "%" Vector__XXX

BO_ 2566842624 LFC: 8 Motor
 SG_ EngTotalFuelUsed : 32|32@1+ (0.5,0) [0|2105540607.5] "L" Vector__XXX
 SG_ EngTripFuel : 0|32@1+ (0.5,0) [0|2105540607.5] "L" Vector__XXX

BO_ 2364542206 ETC8: 8 Vector__XXX
 SG_ TransTorqueConverterRatio : 0|16@1+ (0.001,0) [0|64.255] "" Vector__XXX

BO_ 2566801924 ETC7: 6 Vector__XXX
 SG_ TransRevGearShiftInhibitStat : 40|2@1+ (1,0) [0|3] "" Vector__XXX
 SG_ TransMode5Indicator : 32|2@1+ (1,0) [0|3] "" Vector__XXX
 SG_ TransMode6Indicator : 34|2@1+ (1,0) [0|3] "" Vector__XXX
 SG_ TransMode7Indicator : 36|2@1+ (1,0) [0|3] "" Vector__XXX
 SG_ TransMode8Indicator : 38|2@1+ (1,0) [0|3] "" Vector__XXX
 SG_ TransRqedGearFeedback : 24|8@1+ (1,-125) [-125|125] "" Vector__XXX
 SG_ TransMode1Indicator : 22|2@1+ (1,0) [0|3] "" Vector__XXX
 SG_ TransMode2Indicator : 20|2@1+ (1,0) [0|3] "" Vector__XXX
 SG_ TransMode3Indicator : 18|2@1+ (1,0) [0|3] "" Vector__XXX
 SG_ TransMode4Indicator : 16|2@1+ (1,0) [0|3] "" Vector__XXX
 SG_ TransShiftInhibitIndicator : 14|2@1+ (1,0) [0|3] "" Vector__XXX
 SG_ TransEngCrankEnable : 12|2@1+ (1,0) [0|3] "" Vector__XXX
 SG_ ActiveShiftConsoleIndicator : 10|2@1+ (1,0) [0|3] "" Vector__XXX
 SG_ TransReadyForBrakeRelease : 8|2@1+ (1,0) [0|3] "" Vector__XXX
 SG_ TransRqedRangeDisplayFlashState : 6|2@1+ (1,0) [0|3] "" Vector__XXX
 SG_ TransRqedRangeDisplayBlankState : 4|2@1+ (1,0) [0|3] "" Vector__XXX
 SG_ TransServiceIndicator : 2|2@1+ (1,0) [0|3] "" Vector__XXX
 SG_ TransCurrRangeDisplayBlankState : 0|2@1+ (1,0) [0|3] "" Vector__XXX

BO_ 2565867006 ETC2: 8 Getriebe0
 SG_ TransCurrentRange : 48|16@1+ (1,0) [0|255] "" Vector__XXX
 SG_ TransRqedRange : 32|16@1+ (1,0) [0|255] ""  Bordrechner0
 SG_ TransCurrentGear : 24|8@1+ (1,-125) [-125|125] ""  Bordrechner0,Motor
 SG_ TransActualGearRatio : 8|16@1+ (0.001,0) [0|64.255] "" Vector__XXX
 SG_ TransSelectedGear : 0|8@1+ (1,-125) [-125|125] ""  Motor

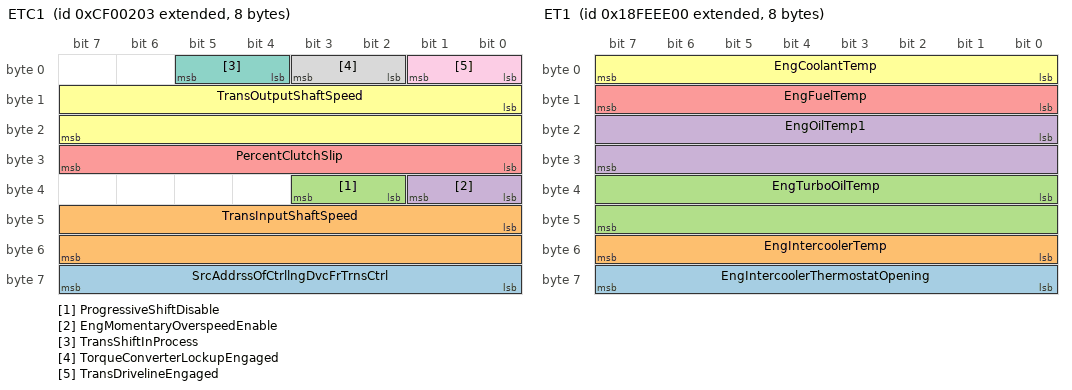
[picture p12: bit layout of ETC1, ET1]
BO_ 2364539395 ETC1: 8 Getriebe0
 SG_ SrcAddrssOfCtrllngDvcFrTrnsCtrl : 56|8@1+ (1,0) [0|255] ""  Motor
 SG_ TransInputShaftSpeed : 40|16@1+ (0.125,0) [0|8031.875] "RPM"  Motor
 SG_ ProgressiveShiftDisable : 34|2@1+ (1,0) [0|3] ""  Motor
 SG_ EngMomentaryOverspeedEnable : 32|2@1+ (1,0) [0|3] ""  Motor
 SG_ PercentClutchSlip : 24|8@1+ (0.4,0) [0|100] "%"  Motor
 SG_ TransOutputShaftSpeed : 8|16@1+ (0.125,0) [0|8031.875] "RPM"  Motor
 SG_ TransShiftInProcess : 4|2@1+ (1,0) [0|3] ""  Motor
 SG_ TorqueConverterLockupEngaged : 2|2@1+ (1,0) [0|3] ""  Motor
 SG_ TransDrivelineEngaged : 0|2@1+ (1,0) [0|3] ""  Motor

BO_ 2566843904 ET1: 8 Motor
 SG_ EngIntercoolerThermostatOpening : 56|8@1+ (0.4,0) [0|100] "%" Vector__XXX
 SG_ EngIntercoolerTemp : 48|8@1+ (1,-40) [-40|210] "�C" Vector__XXX
 SG_ EngTurboOilTemp : 32|16@1+ (0.03125,-273) [-273|1735] "�C" Vector__XXX
 SG_ EngOilTemp1 : 16|16@1+ (0.03125,-273) [-273|1735] "�C"  Bordrechner0
 SG_ EngFuelTemp : 8|8@1+ (1,-40) [-40|210] "�C" Vector__XXX
 SG_ EngCoolantTemp : 0|8@1+ (1,-40) [-40|210] "�C"  Bordrechner0,Luefter,Getriebe0

BO_ 2565865475 ERC1: 9 Getriebe0
 SG_ RetarderRoadSpeedLimitSwitch : 28|2@1+ (1,0) [0|3] "" Vector__XXX
 SG_ RetarderRoadSpeedExceedStatus : 30|2@1+ (1,0) [0|3] "" Vector__XXX
 SG_ RetarderSelectionNonEng : 48|8@1+ (0.4,0) [0|100] "%"  Motor
 SG_ ActlMxAvlblRtarderPercentTorque : 56|8@1+ (1,-125) [-125|125] "%" Vector__XXX
 SG_ DrvrsDmandRetarderPercentTorque : 40|8@1+ (1,-125) [-125|125] "%" Vector__XXX
 SG_ SrcAddrssOfCtrllngDvcFrRtrdrCtrl : 32|8@1+ (1,0) [0|255] "" Vector__XXX
 SG_ RetarderRqingBrakeLight : 26|2@1+ (1,0) [0|3] "" Vector__XXX
 SG_ EngCoolantLoadIncrease : 24|2@1+ (1,0) [0|3] "" Vector__XXX
 SG_ IntendedRetarderPercentTorque : 16|8@1+ (1,-125) [-125|125] "%" Vector__XXX
 SG_ ActualRetarderPercentTorque : 8|8@1+ (1,-125) [-125|125] "%" Vector__XXX
 SG_ RetarderEnableShiftAssistSwitch : 6|2@1+ (1,0) [0|3] "" Vector__XXX
 SG_ RetarderEnableBrakeAssistSwitch : 4|2@1+ (1,0) [0|3] "" Vector__XXX
 SG_ RetarderTorqueMode : 0|4@1+ (1,0) [0|15] "" Vector__XXX

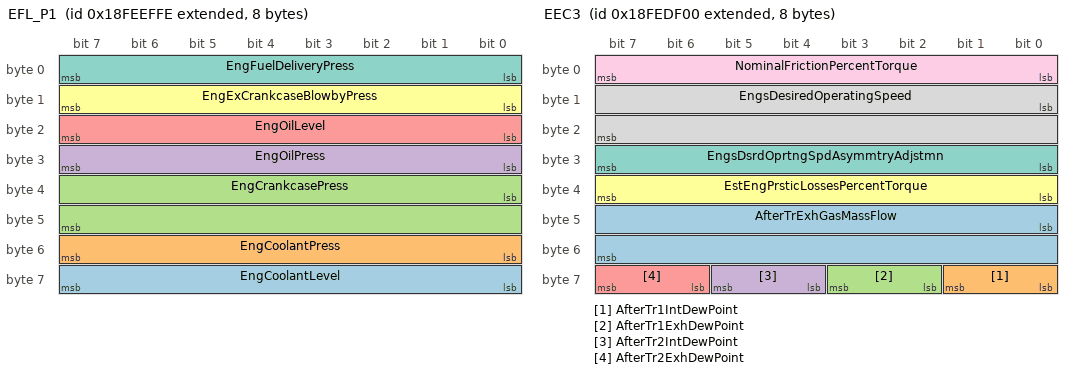
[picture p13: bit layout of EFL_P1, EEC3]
BO_ 2566844414 EFL_P1: 8 Motor
 SG_ EngCoolantLevel : 56|8@1+ (0.4,0) [0|100] "%" Vector__XXX
 SG_ EngCoolantPress : 48|8@1+ (2,0) [0|500] "kPa" Vector__XXX
 SG_ EngCrankcasePress : 32|16@1+ (0.0078125,-250) [-250|251.99] "kPa" Vector__XXX
 SG_ EngOilPress : 24|8@1+ (4,0) [0|1000] "kPa" Vector__XXX
 SG_ EngOilLevel : 16|8@1+ (0.4,0) [0|100] "%" Vector__XXX
 SG_ EngExCrankcaseBlowbyPress : 8|8@1+ (0.05,0) [0|12.5] "kPa" Vector__XXX
 SG_ EngFuelDeliveryPress : 0|8@1+ (4,0) [0|1000] "kPa" Vector__XXX

BO_ 2566840064 EEC3: 8 Motor
 SG_ AfterTrExhGasMassFlow : 40|16@1+ (0.2,0) [0|13107] "kg/h" Vector__XXX
 SG_ AfterTr1IntDewPoint : 56|2@1+ (1,0) [0|3] "" Vector__XXX
 SG_ AfterTr1ExhDewPoint : 58|2@1+ (1,0) [0|3] "" Vector__XXX
 SG_ AfterTr2IntDewPoint : 60|2@1+ (1,0) [0|3] "" Vector__XXX
 SG_ AfterTr2ExhDewPoint : 62|2@1+ (1,0) [0|3] "" Vector__XXX
 SG_ EstEngPrsticLossesPercentTorque : 32|8@1+ (1,-125) [-125|125] "%"  Getriebe0
 SG_ EngsDsrdOprtngSpdAsymmtryAdjstmn : 24|8@1+ (1,0) [0|250] "" Vector__XXX
 SG_ EngsDesiredOperatingSpeed : 8|16@1+ (0.125,0) [0|8031.875] "RPM" Vector__XXX
 SG_ NominalFrictionPercentTorque : 0|8@1+ (1,-125) [-125|125] "%"  Bordrechner1,Getriebe0,Bordrechner0

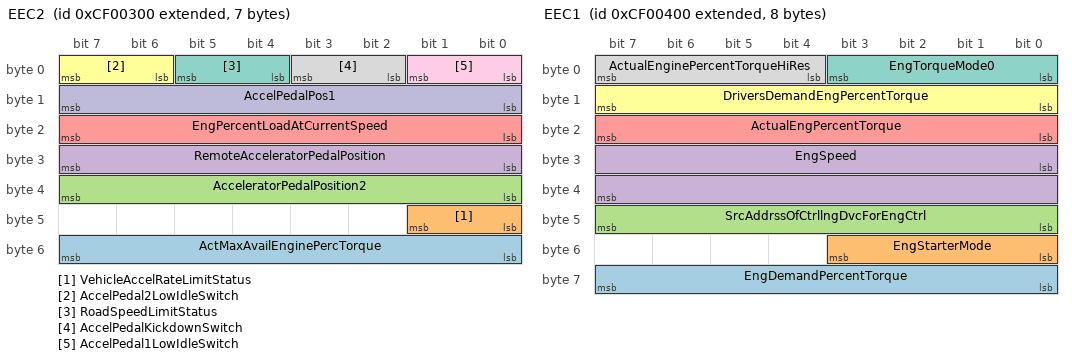
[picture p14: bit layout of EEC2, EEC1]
BO_ 2364539648 EEC2: 7 Motor
 SG_ ActMaxAvailEnginePercTorque : 48|8@1+ (0.4,0) [0|100] "%" Vector__XXX
 SG_ VehicleAccelRateLimitStatus : 40|2@1+ (1,0) [0|3] ""  Getriebe0
 SG_ AcceleratorPedalPosition2 : 32|8@1+ (0.0039,0) [0|1] "mm�" Vector__XXX
 SG_ RemoteAcceleratorPedalPosition : 24|8@1+ (0.0039,0) [0|1] "mm�" Vector__XXX
 SG_ EngPercentLoadAtCurrentSpeed : 16|8@1+ (1,0) [0|250] "%"  Getriebe0
 SG_ AccelPedal2LowIdleSwitch : 6|2@1+ (1,0) [0|3] "" Vector__XXX
 SG_ RoadSpeedLimitStatus : 4|2@1+ (1,0) [0|3] "" Vector__XXX
 SG_ AccelPedalKickdownSwitch : 2|2@1+ (1,0) [0|3] ""  Bordrechner0,Luefter,Getriebe0
 SG_ AccelPedal1LowIdleSwitch : 0|2@1+ (1,0) [0|3] ""  Bordrechner0
 SG_ AccelPedalPos1 : 8|8@1+ (0.4,0) [0|100] "%"  Getriebe0

BO_ 2364539904 EEC1: 8 Motor
 SG_ EngDemandPercentTorque : 56|8@1+ (1,-125) [-125|125] "%"  Luefter,Getriebe0,Getriebe2,Getriebe1,Bordrechner0
 SG_ EngStarterMode : 48|4@1+ (1,0) [0|15] ""  Luefter,Getriebe0,Getriebe2,Getriebe1,Bordrechner0
 SG_ SrcAddrssOfCtrllngDvcForEngCtrl : 40|8@1+ (1,0) [0|255] ""  Luefter,Getriebe0,Getriebe2,Getriebe1,Bordrechner0
 SG_ EngSpeed : 24|16@1+ (0.125,0) [0|8031.875] "RPM"  Luefter,Getriebe0,Getriebe2,Getriebe1,Bordrechner0
 SG_ ActualEngPercentTorque : 16|8@1+ (1,-125) [-125|125] "%"  Luefter,Getriebe0,Getriebe2,Getriebe1,Bordrechner0
 SG_ DriversDemandEngPercentTorque : 8|8@1+ (1,-125) [-125|125] "%"  Luefter,Getriebe0,Getriebe2,Getriebe1,Bordrechner0
 SG_ EngTorqueMode0 : 0|4@1+ (1,0) [0|15] ""  Luefter,Getriebe0,Getriebe2,Getriebe1,Bordrechner0
 SG_ ActualEnginePercentTorqueHiRes : 4|4@1+ (0.125,0) [0|0.875] "%"  Luefter,Getriebe0,Getriebe2,Getriebe1,Bordrechner0

BO_ 2566841342 EC1: 39 Motor
 SG_ SupportTSC1CtrlPurposeGroup4Of4 : 304|8@1+ (1,0) [0|255] "" Vector__XXX
 SG_ SupportVariableRateTSC1Message : 272|8@1+ (1,0) [0|255] "" Vector__XXX
 SG_ SupportTSC1CtrlPurposeGroup3Of4 : 296|8@1+ (1,0) [0|255] "" Vector__XXX
 SG_ SupportTSC1CtrlPurposeGroup2Of4 : 288|8@1+ (1,0) [0|255] "" Vector__XXX
 SG_ SupportTSC1CtrlPurposeGroup1Of4 : 280|8@1+ (1,0) [0|255] "" Vector__XXX
 SG_ EngDefaultTorqueLimit : 256|16@1+ (1,0) [0|64255] "Nm" Vector__XXX
 SG_ EngMomentOfInertia : 240|16@1+ (0.004,0) [0|257.02] "kg-m�" Vector__XXX
 SG_ EngExRngRqdSpdCtrlRngUpperLimit : 224|16@1+ (0.125,0) [0|8031.875] "RPM" Vector__XXX
 SG_ EngRqdTorqueCtrlRangeUpperLimit : 216|8@1+ (1,-125) [-125|125] "%" Vector__XXX
 SG_ EngRqdTorqueCtrlRangeLowerLimit : 208|8@1+ (1,-125) [-125|125] "%" Vector__XXX
 SG_ EngRqedSpeedCtrlRangeUpperLimit : 200|8@1+ (10,0) [0|2500] "RPM" Vector__XXX
 SG_ EngRqedSpeedCtrlRangeLowerLimit : 192|8@1+ (10,0) [0|2500] "RPM" Vector__XXX
 SG_ EngMxMomentaryOverrideTimeLimit : 184|8@1+ (0.1,0) [0|25] "sec" Vector__XXX
 SG_ EngMxMmntaryOverrideSpeedPoint7 : 168|16@1+ (0.125,0) [0|8031.875] "RPM" Vector__XXX
 SG_ EngReferenceTorque : 152|16@1+ (1,0) [0|64255] "Nm"  Getriebe2,Getriebe1,Getriebe0
 SG_ EngSpeedAtHighIdlePoint6 : 120|16@1+ (0.125,0) [0|8031.875] "RPM" Vector__XXX
 SG_ EngGainOfEndspeedGovernor : 136|16@1+ (0.00078125,0) [0|50.2] "%/rpm"  Bordrechner0,Luefter
 SG_ EngPercentTorqueAtPoint5 : 112|8@1+ (1,-125) [-125|125] "%" Vector__XXX
 SG_ EngSpeedAtPoint5 : 96|16@1+ (0.125,0) [0|8031.875] "RPM" Vector__XXX
 SG_ EngPercentTorqueAtPoint4 : 88|8@1+ (1,-125) [-125|125] "%" Vector__XXX
 SG_ EngSpeedAtPoint4 : 72|16@1+ (0.125,0) [0|8031.875] "RPM" Vector__XXX
 SG_ EngPercentTorqueAtPoint3 : 64|8@1+ (1,-125) [-125|125] "%" Vector__XXX
 SG_ EngSpeedAtPoint3 : 48|16@1+ (0.125,0) [0|8031.875] "RPM" Vector__XXX
 SG_ EngPercentTorqueAtPoint2 : 40|8@1+ (1,-125) [-125|125] "%" Vector__XXX
 SG_ EngSpeedAtPoint2 : 24|16@1+ (0.125,0) [0|8031.875] "RPM" Vector__XXX
 SG_ EngPercentTorqueAtIdlePoint1 : 16|8@1+ (1,-125) [-125|125] "%" Vector__XXX
 SG_ EngSpeedAtIdlePoint1 : 0|16@1+ (0.125,0) [0|8031.875] "RPM" Vector__XXX

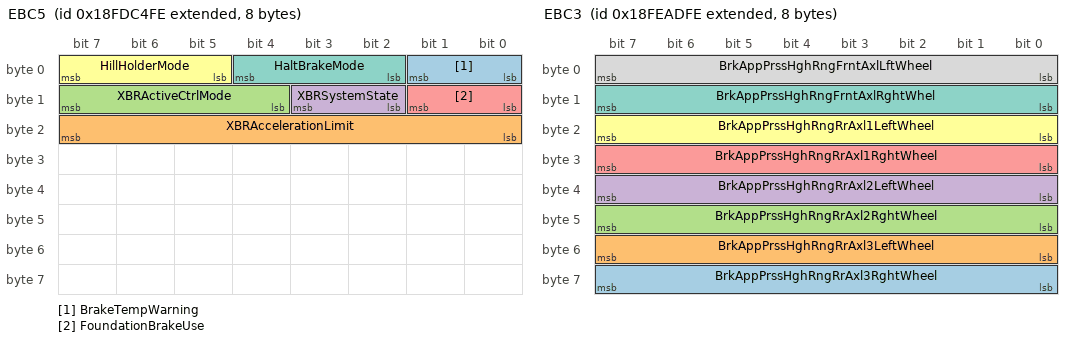
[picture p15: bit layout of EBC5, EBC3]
BO_ 2566767870 EBC5: 8 Vector__XXX
 SG_ BrakeTempWarning : 0|2@1+ (1,0) [0|3] "" Vector__XXX
 SG_ XBRAccelerationLimit : 16|8@1+ (0.1,-12.5) [-12.5|12.5] "m/s�" Vector__XXX
 SG_ XBRActiveCtrlMode : 12|4@1+ (1,0) [0|15] "" Vector__XXX
 SG_ XBRSystemState : 10|2@1+ (1,0) [0|3] "" Vector__XXX
 SG_ FoundationBrakeUse : 8|2@1+ (1,0) [0|3] "" Vector__XXX
 SG_ HillHolderMode : 5|3@1+ (1,0) [0|7] "" Vector__XXX
 SG_ HaltBrakeMode : 2|3@1+ (1,0) [0|7] "" Vector__XXX

BO_ 2566827518 EBC3: 8 Vector__XXX
 SG_ BrkAppPrssHghRngRrAxl3RghtWheel : 56|8@1+ (5,0) [0|1250] "kPa" Vector__XXX
 SG_ BrkAppPrssHghRngRrAxl3LeftWheel : 48|8@1+ (5,0) [0|1250] "kPa" Vector__XXX
 SG_ BrkAppPrssHghRngRrAxl2RghtWheel : 40|8@1+ (5,0) [0|1250] "kPa" Vector__XXX
 SG_ BrkAppPrssHghRngRrAxl2LeftWheel : 32|8@1+ (5,0) [0|1250] "kPa" Vector__XXX
 SG_ BrkAppPrssHghRngRrAxl1RghtWheel : 24|8@1+ (5,0) [0|1250] "kPa" Vector__XXX
 SG_ BrkAppPrssHghRngRrAxl1LeftWheel : 16|8@1+ (5,0) [0|1250] "kPa" Vector__XXX
 SG_ BrkAppPrssHghRngFrntAxlRghtWhel : 8|8@1+ (5,0) [0|1250] "kPa" Vector__XXX
 SG_ BrkAppPrssHghRngFrntAxlLftWheel : 0|8@1+ (5,0) [0|1250] "kPa" Vector__XXX

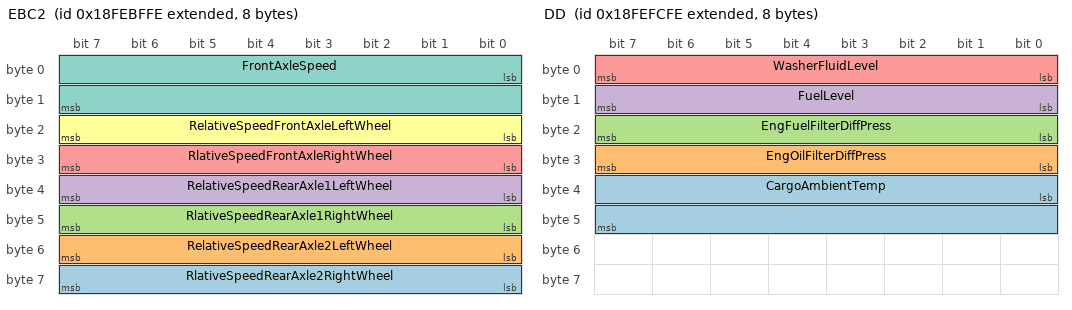
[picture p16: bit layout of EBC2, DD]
BO_ 2566832126 EBC2: 8 Vector__XXX
 SG_ RlativeSpeedRearAxle2RightWheel : 56|8@1+ (0.0625,-7.8125) [-7.8125|7.8125] "km/hr" Vector__XXX
 SG_ RelativeSpeedRearAxle2LeftWheel : 48|8@1+ (0.0625,-7.8125) [-7.8125|7.8125] "km/hr" Vector__XXX
 SG_ RlativeSpeedRearAxle1RightWheel : 40|8@1+ (0.0625,-7.8125) [-7.8125|7.8125] "km/hr" Vector__XXX
 SG_ RelativeSpeedRearAxle1LeftWheel : 32|8@1+ (0.0625,-7.8125) [-7.8125|7.8125] "km/hr" Vector__XXX
 SG_ RlativeSpeedFrontAxleRightWheel : 24|8@1+ (0.0625,-7.8125) [-7.8125|7.8125] "km/hr" Vector__XXX
 SG_ RelativeSpeedFrontAxleLeftWheel : 16|8@1+ (0.0625,-7.8125) [-7.8125|7.8125] "km/hr" Vector__XXX
 SG_ FrontAxleSpeed : 0|16@1+ (0.00390625,0) [0|250.996] "km/hr" Vector__XXX

BO_ 2565865982 EBC1: 8 Bordrechner0
 SG_ SrcAddrssOfCtrllngDvcFrBrkCntrl : 48|8@1+ (1,0) [0|255] "" Vector__XXX
 SG_ BrakePedalPos : 8|8@1+ (0.4,0) [0|100] "%" Vector__XXX
 SG_ TrctrMntdTrilerABSWarningSignal : 62|2@1+ (1,0) [0|3] "" Vector__XXX
 SG_ TrailerABSStatus : 60|2@1+ (1,0) [0|3] "" Vector__XXX
 SG_ HaltBrakeSwitch : 58|2@1+ (1,0) [0|3] "" Vector__XXX
 SG_ ATC_ASRInformationSignal : 46|2@1+ (1,0) [0|3] "" Vector__XXX
 SG_ ABS_EBSAmberWarningSignal : 44|2@1+ (1,0) [0|3] "" Vector__XXX
 SG_ EBSRedWarningSignal : 42|2@1+ (1,0) [0|3] "" Vector__XXX
 SG_ ABSFullyOperational : 40|2@1+ (1,0) [0|3] "" Vector__XXX
 SG_ EngRetarderSelection : 32|8@1+ (0.4,0) [0|100] "%"  Hydrop_Joystick,Getriebe1,Getriebe0,Motor
 SG_ RemoteAccelEnableSwitch : 30|2@1+ (1,0) [0|3] "" Vector__XXX
 SG_ EngAuxEngShutdownSwitch : 28|2@1+ (1,0) [0|3] "" Vector__XXX
 SG_ EngDerateSwitch : 26|2@1+ (1,0) [0|3] "" Vector__XXX
 SG_ AccelInterlockSwitch : 24|2@1+ (1,0) [0|3] "" Vector__XXX
 SG_ TractionCtrlOverrideSwitch : 22|2@1+ (1,0) [0|3] "" Vector__XXX
 SG_ ASRHillHolderSwitch : 20|2@1+ (1,0) [0|3] "" Vector__XXX
 SG_ ASROffroadSwitch : 18|2@1+ (1,0) [0|3] "" Vector__XXX
 SG_ ABSOffroadSwitch : 16|2@1+ (1,0) [0|3] "" Vector__XXX
 SG_ EBSBrakeSwitch : 6|2@1+ (1,0) [0|3] "" Vector__XXX
 SG_ AntiLockBrakingActive : 4|2@1+ (1,0) [0|3] "" Vector__XXX
 SG_ ASRBrakeCtrlActive : 2|2@1+ (1,0) [0|3] "" Vector__XXX
 SG_ ASREngCtrlActive : 0|2@1+ (1,0) [0|3] "" Vector__XXX

BO_ 2566847742 DD: 8 Vector__XXX
 SG_ CargoAmbientTemp : 32|16@1+ (0.03125,-273) [-273|1735] "�C" Vector__XXX
 SG_ EngOilFilterDiffPress : 24|8@1+ (0.5,0) [0|125] "kPa" Vector__XXX
 SG_ EngFuelFilterDiffPress : 16|8@1+ (2,0) [0|500] "kPa" Vector__XXX
 SG_ FuelLevel : 8|8@1+ (0.4,0) [0|100] "%" Vector__XXX
 SG_ WasherFluidLevel : 0|8@1+ (0.4,0) [0|100] "%" Vector__XXX

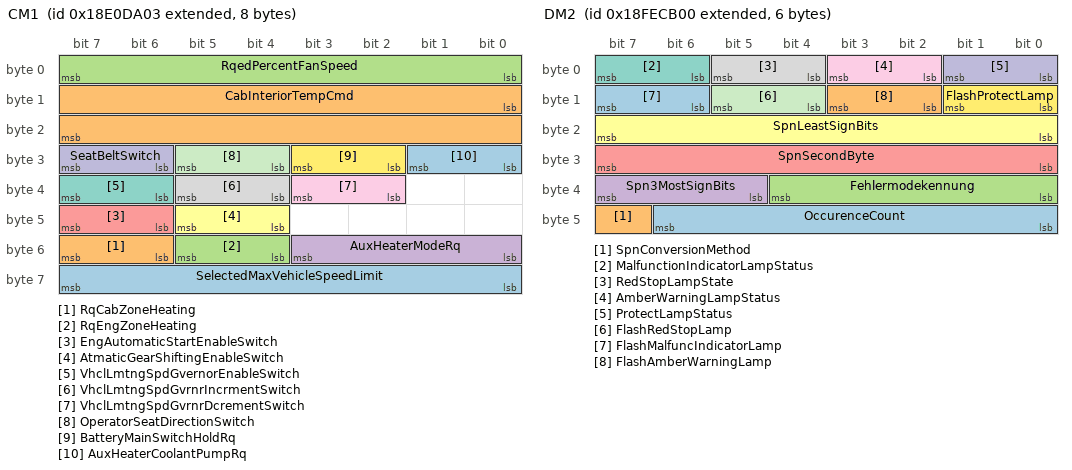
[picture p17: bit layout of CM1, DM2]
BO_ 2564872707 CM1: 8 Getriebe0
 SG_ SelectedMaxVehicleSpeedLimit : 56|8@1+ (1,0) [0|250] "" Vector__XXX
 SG_ RqCabZoneHeating : 54|2@1+ (1,0) [0|3] "" Vector__XXX
 SG_ RqEngZoneHeating : 52|2@1+ (1,0) [0|3] "" Vector__XXX
 SG_ AuxHeaterModeRq : 48|4@1+ (1,0) [0|15] "" Vector__XXX
 SG_ EngAutomaticStartEnableSwitch : 46|2@1+ (1,0) [0|3] "" Vector__XXX
 SG_ AtmaticGearShiftingEnableSwitch : 44|2@1+ (1,0) [0|3] "" Vector__XXX
 SG_ VhclLmtngSpdGvernorEnableSwitch : 38|2@1+ (1,0) [0|3] "" Vector__XXX
 SG_ VhclLmtngSpdGvrnrIncrmentSwitch : 36|2@1+ (1,0) [0|3] "" Vector__XXX
 SG_ VhclLmtngSpdGvrnrDcrementSwitch : 34|2@1+ (1,0) [0|3] "" Vector__XXX
 SG_ SeatBeltSwitch : 30|2@1+ (1,0) [0|3] "" Vector__XXX
 SG_ OperatorSeatDirectionSwitch : 28|2@1+ (1,0) [0|3] "" Vector__XXX
 SG_ BatteryMainSwitchHoldRq : 26|2@1+ (1,0) [0|3] "" Vector__XXX
 SG_ AuxHeaterCoolantPumpRq : 24|2@1+ (1,0) [0|3] "" Vector__XXX
 SG_ CabInteriorTempCmd : 8|16@1+ (0.03125,-273) [-273|1735] "�C" Vector__XXX
 SG_ RqedPercentFanSpeed : 0|8@1+ (0.4,0) [0|100] "%"  Luefter

BO_ 2566843136 CI: 20 Motor
 SG_ Delimiter3 : 152|8@1+ (1,0) [0|0] "" Vector__XXX
 SG_ Delimiter2 : 144|8@1+ (1,0) [0|0] "" Vector__XXX
 SG_ Delimiter1 : 80|8@1+ (1,0) [0|0] "" Vector__XXX
 SG_ Delimiter0 : 48|8@1+ (1,0) [0|0] "" Vector__XXX
 SG_ UnitNumber : 88|56@1+ (1,0) [0|7.20575940379279E+016] "" Vector__XXX
 SG_ SerialNumber : 56|24@1+ (1,0) [0|16777215] "" Vector__XXX
 SG_ Model : 0|48@1+ (1,0) [0|281474976710655] "" Vector__XXX

BO_ 2566844926 CCVS_VSC1: 8 Motor
 SG_ ParkBrakeReleaseInhibitRq : 6|2@1+ (1,0) [0|3] ""  Motor,Bordrechner0
 SG_ EngShutdownOverrideSwitch : 62|2@1+ (1,0) [0|3] ""  Motor,Bordrechner0
 SG_ EngTestModeSwitch : 60|2@1+ (1,0) [0|3] ""  Motor,Bordrechner0
 SG_ EngIdleDecrementSwitch : 58|2@1+ (1,0) [0|3] ""  Motor,Bordrechner0
 SG_ EngIdleIncrementSwitch : 56|2@1+ (1,0) [0|3] ""  Motor,Bordrechner0
 SG_ CruiseCtrlStates : 53|3@1+ (1,0) [0|7] ""  Motor,Bordrechner0
 SG_ PtoGovernorState : 48|5@1+ (1,0) [0|31] ""  Motor,Bordrechner0
 SG_ CruiseCtrlSetSpeed : 40|8@1+ (1,0) [0|250] "km/hr"  Motor,Bordrechner0
 SG_ CruiseCtrlAccelerateSwitch : 38|2@1+ (1,0) [0|3] ""  Motor,Bordrechner0
 SG_ CruiseCtrlResumeSwitch : 36|2@1+ (1,0) [0|3] ""  Motor,Bordrechner0
 SG_ CruiseCtrlCoastSwitch : 34|2@1+ (1,0) [0|3] ""  Motor,Bordrechner0
 SG_ CruiseCtrlSetSwitch : 32|2@1+ (1,0) [0|3] ""  Motor,Bordrechner0
 SG_ ClutchSwitch : 30|2@1+ (1,0) [0|3] ""  Motor,Bordrechner0
 SG_ BrakeSwitch : 28|2@1+ (1,0) [0|3] ""  Motor,Bordrechner0
 SG_ CruiseCtrlEnableSwitch : 26|2@1+ (1,0) [0|3] ""  Motor,Bordrechner0
 SG_ CruiseCtrlActive : 24|2@1+ (1,0) [0|3] ""  Motor,Bordrechner0
 SG_ WheelBasedVehicleSpeed : 8|16@1+ (0.00390625,0) [0|250.996] "km/hr"  Motor,Bordrechner0
 SG_ CruiseCtrlPauseSwitch : 4|2@1+ (1,0) [0|3] ""  Motor,Bordrechner0
 SG_ ParkingBrakeSwitch : 2|2@1+ (1,0) [0|3] ""  Motor,Bordrechner0
 SG_ TwoSpeedAxleSwitch : 0|2@1+ (1,0) [0|3] ""  Motor,Bordrechner0

BO_ 2566835710 DM4: 13 Motor
 SG_ OccurenceCount : 32|7@1+ (1,0) [0|0] "" Vector__XXX
 SG_ SpnConversionMethod : 39|1@1+ (1,0) [0|0] "" Vector__XXX
 SG_ FMI : 24|5@1+ (1,0) [0|0] "" Vector__XXX
 SG_ Spn3MostSignBits : 29|3@1+ (1,0) [0|0] "" Vector__XXX
 SG_ SpnSecondByte : 16|8@1+ (1,0) [0|255] "" Vector__XXX
 SG_ SpnLeastSignBits : 8|8@1+ (1,0) [0|255] "" Vector__XXX
 SG_ FreezeFrameLength : 0|8@1+ (1,0) [0|255] "Byte" Vector__XXX
 SG_ EngSpeed : 56|16@1+ (0.125,0) [0|8031.875] "RPM" Vector__XXX
 SG_ EngTorqueMode1 : 40|8@1+ (1,0) [0|255] "" Vector__XXX
 SG_ EngTurboBoostPress : 48|8@1+ (2,0) [0|500] "kPa" Vector__XXX
 SG_ WheelBasedVehicleSpeed : 88|16@1+ (0.00390625,0) [0|250.996] "km/hr" Vector__XXX
 SG_ EngPercentLoadAtCurrentSpeed : 72|8@1+ (1,0) [0|250] "%" Vector__XXX
 SG_ EngineCoolantTemperature : 80|8@1+ (1,-40) [-40|210] "�C" Vector__XXX

BO_ 2566835454 DM3: 0 Motor

BO_ 2566834944 DM2: 6 Motor
 SG_ OccurenceCount : 40|7@1+ (1,0) [0|0] "" Vector__XXX
 SG_ SpnConversionMethod : 47|1@1+ (1,0) [0|0] "" Vector__XXX
 SG_ Fehlermodekennung : 32|5@1+ (1,0) [0|0] "" Vector__XXX
 SG_ Spn3MostSignBits : 37|3@1+ (1,0) [0|0] "" Vector__XXX
 SG_ SpnSecondByte : 24|8@1+ (1,0) [0|255] "" Vector__XXX
 SG_ SpnLeastSignBits : 16|8@1+ (1,0) [0|255] "" Vector__XXX
 SG_ MalfunctionIndicatorLampStatus : 6|2@1+ (1,0) [0|3] "" Vector__XXX
 SG_ RedStopLampState : 4|2@1+ (1,0) [0|3] "" Vector__XXX
 SG_ AmberWarningLampStatus : 2|2@1+ (1,0) [0|3] "" Vector__XXX
 SG_ ProtectLampStatus : 0|2@1+ (1,0) [0|3] "" Vector__XXX
 SG_ FlashRedStopLamp : 12|2@1+ (1,0) [0|3] "" Vector__XXX
 SG_ FlashProtectLamp : 8|2@1+ (1,0) [0|3] "" Vector__XXX
 SG_ FlashMalfuncIndicatorLamp : 14|2@1+ (1,0) [0|3] "" Vector__XXX
 SG_ FlashAmberWarningLamp : 10|2@1+ (1,0) [0|3] "" Vector__XXX

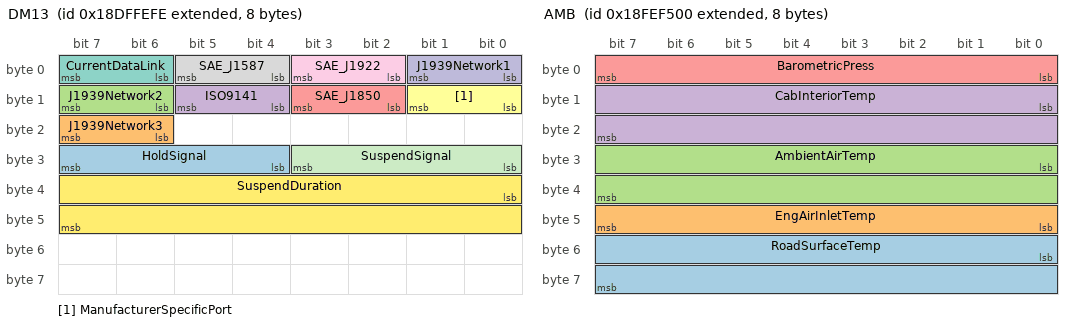
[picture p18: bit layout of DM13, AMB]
BO_ 2564816638 DM13: 8 Vector__XXX
 SG_ HoldSignal : 28|4@1+ (1,0) [0|15] "" Vector__XXX
 SG_ J1939Network3 : 22|2@1+ (1,0) [0|3] "" Vector__XXX
 SG_ J1939Network2 : 14|2@1+ (1,0) [0|3] "" Vector__XXX
 SG_ ISO9141 : 12|2@1+ (1,0) [0|3] "" Vector__XXX
 SG_ SAE_J1850 : 10|2@1+ (1,0) [0|3] "" Vector__XXX
 SG_ ManufacturerSpecificPort : 8|2@1+ (1,0) [0|3] "" Vector__XXX
 SG_ CurrentDataLink : 6|2@1+ (1,0) [0|3] "" Vector__XXX
 SG_ SAE_J1587 : 4|2@1+ (1,0) [0|3] "" Vector__XXX
 SG_ SAE_J1922 : 2|2@1+ (1,0) [0|3] "" Vector__XXX
 SG_ J1939Network1 : 0|2@1+ (1,0) [0|3] "" Vector__XXX
 SG_ SuspendSignal : 24|4@1+ (1,0) [0|15] "" Vector__XXX
 SG_ SuspendDuration : 32|16@1+ (1,0) [0|64255] "sec" Vector__XXX

BO_ 2566836992 DM11: 0 Motor

BO_ 2565799678 ACL: 8 JetEIM1_JIM1_1
 SG_ ManufacturerCode : 16|16@1+ (1,0) [0|65535] ""  Retarder_Motor,Motor
 SG_ ArbitraryAddressCapable : 63|1@1+ (1,0) [0|1] ""  Retarder_Motor,Motor
 SG_ IndustryGroup M : 60|3@1+ (1,0) [0|7] ""  Retarder_Motor,Motor
 SG_ VehicleSystemInstance : 56|4@1+ (1,0) [0|15] ""  Retarder_Motor,Motor
 SG_ Function : 40|8@1+ (1,0) [0|255] ""  Retarder_Motor,Motor
 SG_ FunctionInstance : 35|5@1+ (1,0) [0|31] ""  Retarder_Motor,Motor
 SG_ ECUInstance : 32|3@1+ (1,0) [0|7] ""  Retarder_Motor,Motor
 SG_ IdentityNumber : 0|16@1+ (1,0) [0|65535] ""  Retarder_Motor,Motor
 SG_ VehicleSystem m0 : 49|7@1+ (1,0) [0|127] ""  Retarder_Motor,Motor
 SG_ VehicleSystem5 m5 : 49|7@1+ (1,0) [0|127] ""  Retarder_Motor,Motor
 SG_ VehicleSystem4 m4 : 49|7@1+ (1,0) [0|127] ""  Retarder_Motor,Motor
 SG_ VehicleSystem3 m3 : 49|7@1+ (1,0) [0|127] ""  Retarder_Motor,Motor
 SG_ VehicleSystem2 m2 : 49|7@1+ (1,0) [0|127] ""  Retarder_Motor,Motor
 SG_ VehicleSystem1 m1 : 49|7@1+ (1,0) [0|127] ""  Retarder_Motor,Motor

BO_ 2565603070 TPDT: 8 Motor
 SG_ SequenceNumber : 0|8@1+ (1,0) [0|252] "" Vector__XXX

BO_ 2565668606 TPCM: 8 Motor
 SG_ TotalNumberOfPacketsEoMA m19 : 24|8@1+ (1,0) [0|255] "" Vector__XXX
 SG_ TotalMessageSizeEoMA m19 : 8|16@1+ (1,0) [0|64255] "counts" Vector__XXX
 SG_ TotalMessageSizeBAM m32 : 8|16@1+ (1,0) [0|64255] "counts" Vector__XXX
 SG_ TotalNumberOfPacketsBAM m32 : 24|8@1+ (1,0) [0|255] "" Vector__XXX
 SG_ ConnectionAbortReason m255 : 8|8@1+ (1,0) [0|255] "" Vector__XXX
 SG_ NextPacketNumberToBeSent m17 : 16|8@1+ (1,0) [0|255] "" Vector__XXX
 SG_ NumberOfPacketsThatCanBeSent m17 : 8|8@1+ (1,0) [0|255] "" Vector__XXX
 SG_ PGNumber : 40|24@1+ (1,0) [0|16777200] "" Vector__XXX
 SG_ MaximumNumberOfPackets m16 : 32|8@1+ (1,0) [0|255] "" Vector__XXX
 SG_ TotalNumberOfPackets m16 : 24|8@1+ (1,0) [0|255] "" Vector__XXX
 SG_ TotalMessageSize m16 : 8|16@1+ (1,0) [0|64255] "counts" Vector__XXX
 SG_ ControlByte M : 0|8@1+ (1,0) [0|255] "" Vector__XXX

BO_ 2565472505 RQST: 3 Bordrechner3
 SG_ ParameterGroupNumber : 0|24@1+ (1,0) [0|16777215] ""  JetEIM1_JIM1_2,JetEIM1_JIM1_1,JetEIM1_JIM1_0,JetXCI1,Motor

BO_ 2566838561 AUXIO1: 8 Bordrechner0
 SG_ AuxIoChannel2 : 48|16@1+ (1,0) [0|65535] "counts"  Getriebe1
 SG_ AuxIoChannel1 : 32|16@1+ (1,0) [0|65535] "counts"  Getriebe1
 SG_ AuxIo16_ED55 : 24|2@1+ (1,0) [0|3] ""  Getriebe1
 SG_ AuxIo15_ED54 : 26|2@1+ (1,0) [0|3] ""  Getriebe1
 SG_ AuxIo14_ED53 : 28|2@1+ (1,0) [0|3] ""  Getriebe1
 SG_ AuxIo13_ED52 : 30|2@1+ (1,0) [0|3] ""  Getriebe1
 SG_ AuxIo11_ED50 : 18|2@1+ (1,0) [0|3] ""  Getriebe1
 SG_ AuxIo10_ED49 : 20|2@1+ (1,0) [0|3] ""  Getriebe1
 SG_ AuxIo09_ED48 : 22|2@1+ (1,0) [0|3] ""  Getriebe1
 SG_ AuxIo08_ED47 : 8|2@1+ (1,0) [0|3] ""  Getriebe1
 SG_ AuxIo07_ED46 : 10|2@1+ (1,0) [0|3] ""  Getriebe1
 SG_ AuxIo06_KampschalterEin : 12|2@1+ (1,0) [0|3] ""  Bordrechner0,Getriebe1
 SG_ AuxIo12_ED51 : 16|2@1+ (1,0) [0|3] ""  Getriebe1
 SG_ AuxIo05_AVGInLow : 14|2@1+ (1,0) [0|3] ""  Bordrechner0,Getriebe1
 SG_ AuxIo04_FahrprogUmsch2 : 0|2@1+ (1,0) [0|3] ""  Getriebe1
 SG_ AuxIo03_FahrprogUmsch1 : 2|2@1+ (1,0) [0|3] ""  Getriebe1
 SG_ AuxIo02_JetKupplungSchliessen : 4|2@1+ (1,0) [0|3] ""  Bordrechner0,Getriebe1
 SG_ AuxIo01_HydroFahren : 6|2@1+ (1,0) [0|3] ""  Bordrechner0,Getriebe1

BO_ 2566845696 AMB: 8 Motor
 SG_ RoadSurfaceTemp : 48|16@1+ (0.03125,-273) [-273|1735] "�C" Vector__XXX
 SG_ EngAirInletTemp : 40|8@1+ (1,-40) [-40|210] "�C" Vector__XXX
 SG_ AmbientAirTemp : 24|16@1+ (0.03125,-273) [-273|1735] "�C"  Bordrechner0,Getriebe0
 SG_ CabInteriorTemp : 8|16@1+ (0.03125,-273) [-273|1735] "�C" Vector__XXX
 SG_ BarometricPress : 0|8@1+ (0.5,0) [0|125] "kPa" Vector__XXX

BO_ 2432593918 ACC1: 8 Vector__XXX
 SG_ ACCDistanceAlertSignal : 52|2@1+ (1,0) [0|3] "" Vector__XXX
 SG_ ACCSystemShutoffWarning : 50|2@1+ (1,0) [0|3] "" Vector__XXX
 SG_ ACCTargetDetected : 48|2@1+ (1,0) [0|3] "" Vector__XXX
 SG_ RoadCurvature : 32|16@1+ (0.0078125,-250) [-250|251.992] "1/km" Vector__XXX
 SG_ AdptveCruiseCtrlSetDistanceMode : 27|3@1+ (1,0) [0|7] "" Vector__XXX
 SG_ AdaptiveCruiseCtrlMode : 24|3@1+ (1,0) [0|7] "" Vector__XXX
 SG_ AdaptiveCruiseCtrlSetSpeed : 16|8@1+ (1,0) [0|250] "km/hr" Vector__XXX
 SG_ DistanceToForwardVehicle : 8|8@1+ (1,0) [0|250] "m" Vector__XXX
 SG_ SpeedOfForwardVehicle : 0|8@1+ (1,0) [0|250] "km/hr" Vector__XXX

BO_ 2565406462 ACKM: 8 JetEIM1_JIM1_0
 SG_ AddressBusy m3 : 32|8@1+ (1,0) [0|255] "" Vector__XXX
 SG_ AckNack M : 0|8@1+ (1,0) [0|255] "" Vector__XXX
 SG_ ParameterGroupNumber : 40|24@1+ (1,0) [0|16777215] "" Vector__XXX
 SG_ GroupFunctionValue : 8|8@1+ (1,0) [0|255] "" Vector__XXX
 SG_ AddressAccessDenied m2 : 32|8@1+ (1,0) [0|255] "" Vector__XXX
 SG_ AddressNegativeAcknowledgement m1 : 32|8@1+ (1,0) [0|255] "" Vector__XXX

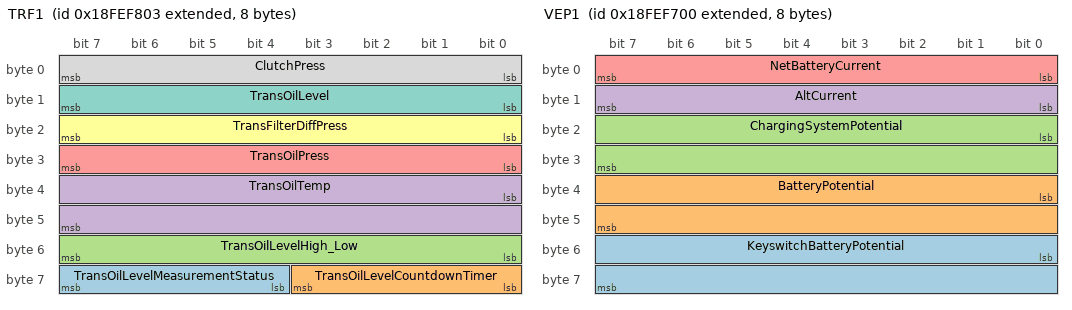
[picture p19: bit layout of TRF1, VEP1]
BO_ 2566846467 TRF1: 8 Getriebe0
 SG_ TransOilLevelMeasurementStatus : 60|4@1+ (1,0) [0|15] "" Vector__XXX
 SG_ TransOilLevelCountdownTimer : 56|4@1+ (1,0) [0|15] "" Vector__XXX
 SG_ TransOilLevelHigh_Low : 48|8@1+ (0.5,-62.5) [-62.5|62.5] "L" Vector__XXX
 SG_ TransOilTemp : 32|16@1+ (0.03125,-273) [-273|1735] "�C"  Bordrechner0
 SG_ TransOilPress : 24|8@1+ (16,0) [0|4000] "kPa" Vector__XXX
 SG_ TransFilterDiffPress : 16|8@1+ (2,0) [0|500] "kPa" Vector__XXX
 SG_ TransOilLevel : 8|8@1+ (0.4,0) [0|100] "%" Vector__XXX
 SG_ ClutchPress : 0|8@1+ (16,0) [0|4000] "kPa" Vector__XXX

BO_ 2566846208 VEP1: 8 Motor
 SG_ KeyswitchBatteryPotential : 48|16@1+ (0.05,0) [0|3212.75] "V" Vector__XXX
 SG_ BatteryPotential : 32|16@1+ (0.05,0) [0|3212.75] "V" Vector__XXX
 SG_ ChargingSystemPotential : 16|16@1+ (0.05,0) [0|3212.75] "V" Vector__XXX
 SG_ AltCurrent : 8|8@1+ (1,0) [0|250] "A" Vector__XXX
 SG_ NetBatteryCurrent : 0|8@1+ (1,-125) [-125|125] "A" Vector__XXX

BO_TX_BU_ 2364535040 : Bordrechner4,Bordrechner3,Bordrechner2,Bordrechner1,Motor;
BO_TX_BU_ 2566854398 : Bordrechner4,Bordrechner3,Bordrechner2,Bordrechner1;
BO_TX_BU_ 2566854137 : Bordrechner4,Bordrechner3,Bordrechner2,Bordrechner1;
BO_TX_BU_ 2365527033 : Bordrechner4,Bordrechner3,Bordrechner2,Bordrechner1;
BO_TX_BU_ 2566852304 : JetXCI1,JetEIM1_JIM1_2,JetEIM1_JIM1_1,JetEIM1_JIM1_0;
BO_TX_BU_ 2499743184 : JetEIM1_JIM1_1,JetXCI1,JetEIM1_JIM1_2,JetEIM1_JIM1_0;
BO_TX_BU_ 2566834688 : Getriebe2,Getriebe1,Getriebe0,Motor;
BO_TX_BU_ 2348810243 : Bordrechner0,Getriebe0;
BO_TX_BU_ 2566840835 : Getriebe2,Getriebe1,Getriebe0;
BO_TX_BU_ 2566838784 : JetXCI1,JetEIM1_JIM1_2,JetEIM1_JIM1_1,JetEIM1_JIM1_0,Motor;
BO_TX_BU_ 2566840830 : Getriebe2,Getriebe1,Getriebe0,Retarder_Motor;
BO_TX_BU_ 2565865475 : Retarder_Motor,Getriebe0;
BO_TX_BU_ 2566840064 : Luefter,Bordrechner0,Motor;
BO_TX_BU_ 2565865982 : Retarder_Motor,Bordrechner0;
BO_TX_BU_ 2566843136 : JetEIM1_JIM1_2,JetEIM1_JIM1_1,JetEIM1_JIM1_0,JetXCI1,Motor;
BO_TX_BU_ 2566844926 : Bordrechner0,Motor;
BO_TX_BU_ 2566835454 : Retarder_Motor,Motor;
BO_TX_BU_ 2565799678 : Motor,JetEIM1_JIM1_0,JetXCI1,JetEIM1_JIM1_2,JetEIM1_JIM1_1;
BO_TX_BU_ 2565603070 : JetEIM1_JIM1_0,JetEIM1_JIM1_1,JetEIM1_JIM1_2,JetXCI1,Retarder_Motor,Motor;
BO_TX_BU_ 2565668606 : JetXCI1,JetEIM1_JIM1_2,JetEIM1_JIM1_1,JetEIM1_JIM1_0,Retarder_Motor,Motor;
BO_TX_BU_ 2566838561 : Getriebe1,Bordrechner0;
BO_TX_BU_ 2565406462 : Retarder_Motor,Motor,JetXCI1,JetEIM1_JIM1_2,JetEIM1_JIM1_1,JetEIM1_JIM1_0;

CM_ BO_ 3221225472 "This is a message for not used signals, created by Vector CANdb++ DBC OLE DB Provider.";
CM_ SG_ 3221225472 OverTemperatureWarningFlag "Propriet�r AMPV ZF Getriebe";
CM_ SG_ 3221225472 ExhaustGasMass "Measured/calculated exhaust gas mass upstream of the after-treatment system.Measured/calculated exhaust gas mass upstream of the after-treatment system.Measured/calculated exhaust gas mass upstream of the after-treatment system.";
CM_ SG_ 3221225472 EngTurboBoostPress "Gage pressure of air measured downstream on the compressor discharge side of the turbocharger.";
CM_ SG_ 3221225472 DTC5 "Diagnostic Trouble Code";
CM_ SG_ 3221225472 DTC4 "Diagnostic Trouble Code";
CM_ SG_ 3221225472 DTC3 "Diagnostic Trouble Code";
CM_ SG_ 3221225472 DTC2 "Diagnostic Trouble Code";
CM_ SG_ 3221225472 DTC1 "Diagnostic Trouble Code";
CM_ SG_ 3221225472 EngsDesiredOperatingSpeed "An indication by the engine of the optimal operating speed of the engine for the current existing conditions.An indication by the engine of the optimal operating speed of the engine for the current existing conditions.";
CM_ SG_ 3221225472 OperatorPTOMemorySelectSwitch "Measured state of the operator PTO memory select switch.";
CM_ SG_ 3221225472 EngPTOAccelerateSwitch "Switch signal of the PTO control activator which indicates that the activator is in the position accelerate.";
CM_ SG_ 3221225472 EngPTOResumeSwitch "Switch signal of the PTO control activator which indicates that the activator is in the position \"resume\".";
CM_ SG_ 3221225472 EngPTOCoast_DecelerateSwitch "Switch signal of the PTO control activator which indicates that the activator is in the position coast/decelerate.";
CM_ SG_ 3221225472 EngRmtPTOVriableSpeedCtrlSwitch "Switch signal which indicates that the remote PTO toggle switch is in the enabled (ON) position.";
CM_ SG_ 3221225472 EngRmtPTOPrprgrmmdSpdCtrlSwitch "Switch signal which indicates that the remote PTO toggle switch is in the enabled (ON) position.";
CM_ SG_ 3221225472 PowerTakeoffSetSpeed "Rotational velocity selected by operator for device used to transmit engine power to auxiliary equipment.";
CM_ SG_ 3221225472 PowerTakeoffSpeed "Rotational velocity of device used to transmit engine power to auxiliary equipment.";
CM_ SG_ 3221225472 PowerTakeoffOilTemp "Temperature of lubricant in device used to transmit engine power to auxiliary equipment.";
CM_ SG_ 3221225472 RmtPTOPrprgrmmdSpeedCtrlSwitch2 "Switch signal which indicates that the remote PTO toggle switch #2 is in the enabled (ON) position.";
CM_ SG_ 3221225472 AuxInputIgnoreSwitch "Switch signal which overrides other switch input's ability to kick out of an engine's operating condition.";
CM_ SG_ 3221225472 DTC1 "Diagnostic Trouble Code";
CM_ BO_ 2566834688 "Previously active diagnostic trouble codes";
CM_ SG_ 2566834688 MalfunctionIndicatorLampStatus "A lamp used to relay only emissions-related trouble code information.";
CM_ SG_ 2566834688 RedStopLampState "This lamp is uesed to relay trouble code information that is of a severe enought condition that it warrants stopping the vehicle.";
CM_ SG_ 2566834688 AmberWarningLampStatus "This lamp is used to relay trouble code information that is reporting a problem with the vehicle system but the vehicle need
not be immediately stopped.";
CM_ SG_ 2566834688 ProtectLampStatus "This lamp is used to relay trouble code informatio that is reporting a problem with a vehicle system that is most
probably not electronic subsystem related.";
CM_ SG_ 2566834688 FlashRedStopLamp "This parameter provides the capability to flash the RSL (SPN 3039).";
CM_ SG_ 2566834688 FlashProtectLamp "This parameter provides the capability to flash the engine protect lamp (SPN 3041).";
CM_ SG_ 2566834688 FlashMalfuncIndicatorLamp "This parameter provides the capability to flash the MIL (SPN 3038).";
CM_ SG_ 2566834688 FlashAmberWarningLamp "This parameter provides the capability to flash the AWL (SPN 3040). ";
CM_ BO_ 2566845952 "Inlet/Exhaust Conditions 1";
CM_ SG_ 2566845952 EngExhaustGasTemp "Temperature of combustion byproducts leaving the engine.";
CM_ SG_ 2566845952 EngAirInletPress "Absolute air pressure at inlet to intake manifold or air box.";
CM_ SG_ 2566845952 EngIntakeManifold1Temp "Temperature of pre-combustion air found in intake manifold of engine air supply system.";
CM_ SG_ 2566845952 EngParticulateTrapInletPress "Exhaust back pressure as a result of particle accumulation on filter media placed in the exhaust stream.";
CM_ BO_ 2566841854 "Engine Hours, Revolutions";
CM_ SG_ 2566841854 EngTotalRevolutions "Accumulated number of revolutions of engine crankshaft during its operation.";
CM_ SG_ 2566841854 EngTotalHoursOfOperation "Accumulated time of operation of engine.";
CM_ BO_ 2566832638 "High Resolution Vehicle Distance";
CM_ SG_ 2566832638 HighResolutionTripDistance "Distance traveled during all or part of a journey.";
CM_ SG_ 2566832638 HghRslutionTotalVehicleDistance "Accumulated distance traveled by the vehicle during its operation.";
CM_ BO_ 2348810243 "Torque/Speed Control 1";
CM_ SG_ 2348810243 ControlPurpose "State signal which indicates which control mode the sending device is using to generate the TSC1 command.";
CM_ SG_ 2348810243 TransmissionRate "This parameter indicates the transmission rate at which the sending device will transmit the TSC1 message.";
CM_ SG_ 2348810243 EngRqedTorque_TorqueLimit "Parameter provided to the engine or retarder in the torque/speed control message for controlling or limiting the output torque.";
CM_ SG_ 2348810243 EngRqedSpeed_SpeedLimit "Parameter provided to the engine from external sources in the torque/speed control message.";
CM_ SG_ 2348810243 EngRqedSpeedCtrlConditions "This mode tells the engine control system the governor characteristics that are desired during speed control.";
CM_ SG_ 2348810243 EngineRequestedTorqueHiRes "This parameter displays an additional torque in percent of the reference engine torque.";
CM_ BO_ 2566805246 "Tank Information 1";
CM_ SG_ 2566805246 CatalystTankTemp "Temperature of the reagent in the storage tank.";
CM_ SG_ 2566805246 CatalystTankLevel "A special catalyst uses chemical substance to reach legal requirement for NOX emissions.";
CM_ SG_ 2566805246 CatalystTankLevelPreliminaryFMI "Used to identify the applicable J1939-73 FMI that applies to the most significant failure of the catalyst tank level sensor.";
CM_ SG_ 2566805246 CatalystTankLevel2 "The measure of the reagent level in the catalyst tank.";
CM_ BO_ 2566842110 "Time/Date";
CM_ SG_ 2566842110 LocalMinuteOffset "Local offset in minutes from a reference time.";
CM_ SG_ 2566842110 Year "Part of a parameter used to represent a calendar date.";
CM_ SG_ 2566842110 Day "Part of a parameter used to represent a calendar date.";
CM_ SG_ 2566842110 Month "Part of a parameter used to represent a calendar date.";
CM_ SG_ 2566842110 Hours "Part of a parameter used to represent time.";
CM_ SG_ 2566842110 Minutes "Part of a parameter used to represent time.";
CM_ SG_ 2566842110 Seconds "Part of a parameter used to represent time.";
CM_ BO_ 2365484286 "Tachograph";
CM_ SG_ 2365484286 TachographVehicleSpeed "Speed of the vehicle registered by the tachograph.";
CM_ SG_ 2365484286 TachographOutputShaftSpeed "Calculated speed of the transmission output shaft.";
CM_ SG_ 2365484286 DirectionIndicator "Indicates the direction of the vehicle.";
CM_ SG_ 2365484286 HandlingInformation "Indicates that handling information is present.";
CM_ SG_ 2365484286 SystemEvent "Indicates that a tachograph event has occurred.";
CM_ SG_ 2365484286 Driver2TimeRelatedStates "Indicates if the driver approaches or exceeds working time limits (or other limits).";
CM_ SG_ 2365484286 Overspeed "Indicates whether the vehicle is exceeding the legal speed limit set in the tachograph.";
CM_ SG_ 2365484286 Driver1TimeRelatedStates "Indicates if the driver approaches or exceeds working time limits (or other limits).";
CM_ SG_ 2365484286 DriveRecognize "Indicates whether motion of the vehicle is detected or not.";
CM_ SG_ 2365484286 Driver2WorkingState "State of work of the driver.";
CM_ SG_ 2365484286 Driver1WorkingState "State of work of the driver.";
CM_ BO_ 2566840835 "Transmission Configuration";
CM_ SG_ 2566840835 NumberOfForwardGearRatios "Number of forward gear ratios in the transmission, provided as part of the configuration.";
CM_ SG_ 2566840835 NumberOfReverseGearRatios "Number of reverse gear ratios in the transmission, provided as part of the transmission configuration.";
CM_ BO_ 2348876577 "Transmission Control 1";
CM_ SG_ 2348876577 TrnsShftSlctorDisplayModeSwitch "Status of the operator�s switch used to �toggle� through multiple display modes of a shift selector display.";
CM_ SG_ 2348876577 TransMode4 "Indicates whether transmission mode 4 is enabled.";
CM_ SG_ 2348876577 TransMode3 "Indicates whether transmission mode 3 is enabled.";
CM_ SG_ 2348876577 TransMode2 "Indicates whether transmission mode 2 is enabled.";
CM_ SG_ 2348876577 TransMode1 "Indicates whether transmission mode 1 is enabled.";
CM_ SG_ 2348876577 DisengageDiffLockRqCentralRear "Command signal used to disengage the various differential locks, e.";
CM_ SG_ 2348876577 DisengageDiffLockRqCentralFront "Command signal used to disengage the various differential locks, e.";
CM_ SG_ 2348876577 DisengageDiffLockRqCentral "Command signal used to disengage the various differential locks, e.";
CM_ SG_ 2348876577 DisengageDiffLockRqRearAxle2 "Command signal used to disengage the various differential locks, e.";
CM_ SG_ 2348876577 DisengageDiffLockRqRearAxle1 "Command signal used to disengage the various differential locks, e.";
CM_ SG_ 2348876577 DisengageDiffLockRqFrontAxle2 "Command signal used to disengage the various differential locks, e.";
CM_ SG_ 2348876577 DisengageDiffLockRqFrontAxle1 "Command signal used to disengage the various differential locks, e.";
CM_ SG_ 2348876577 TransRqedGear "Gear requested by the operator, ABS, or engine.";
CM_ SG_ 2348876577 RqedPercentClutchSlip "Parameter which represents the percent clutch slip requested by a device.";
CM_ SG_ 2348876577 DisengageDrivelineRq "Command signal used to simply disengage the driveline, e.";
CM_ SG_ 2348876577 TorqueConverterLockupDisableRq "Command signal to prevent torque converter lockup, which may cause problems in certain circumstances for ASR.";
CM_ SG_ 2348876577 TransGearShiftInhibitRq "Command signal to inhibit gear shifts.";
CM_ BO_ 2566838784 "Software Identification";
CM_ SG_ 2566838784 Sub2Version "Ist ein ASCII-Text mit bis zu 200 Zeichen. Wird mit * terminiert.";
CM_ SG_ 2566838784 Sub1Version "Ist ein ASCII-Text mit bis zu 200 Zeichen. Wird mit * terminiert.";
CM_ SG_ 2566838784 SpecialSoftwareVersion "Ist ein ASCII-Text mit bis zu 200 Zeichen. Wird mit * terminiert.";
CM_ SG_ 2566838784 SoftwareVersion "Ist ein ASCII-Text mit bis zu 200 Zeichen. Wird mit * terminiert.";
CM_ SG_ 2566838784 NmbrOfSftwrIdentificationFields "Number of software identification designators represented in the software identification parameter group.";
CM_ BO_ 2566847235 "Retarder fluids";
CM_ SG_ 2566847235 HydRetarderOilTemp "Temperature of oil found in a hydraulic retarder.";
CM_ SG_ 2566847235 HydRetarderPress "Gage pressure of oil in hydraulic retarder system.";
CM_ BO_ 2631859966 "Reset";
CM_ SG_ 2631859966 EngBuildHoursReset "Command signal used to reset the engine rebuild hours.";
CM_ SG_ 2631859966 ServiceComponentIdentification "Identification of component needing service.";
CM_ SG_ 2631859966 TripGroup2Proprietary "Command signal used to reset proprietary parameters associated with a trip but not defined within this document.";
CM_ SG_ 2631859966 TripGroup1 "Command signal used to reset the PGNs and parameters as defined in Table SPN988_A.";
CM_ BO_ 2566840830 "Retarder Configuration";
CM_ SG_ 2566840830 ReferenceRetarderTorque "This parameter is the 100% reference value for all defined indicated retarder torque parameters.";
CM_ SG_ 2566840830 RetarderSpeedAtPoint4 "Retarder speed of point 4 of the engine retarder torque map.";
CM_ SG_ 2566840830 RetarderSpeedAtPoint3 "Retarder speed of point 3 of the engine retarder torque map.";
CM_ SG_ 2566840830 PercentTorqueAtMaxSpeedPoint2 "The torque limit that indicates the available retarder torque which can be provided by the retarder at its maximum speed.";
CM_ SG_ 2566840830 MaxRetarderSpeedPoint2 "Maximum speed of retarder (Please reference PGN 65249).";
CM_ SG_ 2566840830 PercentTorqueAtIdlePoint1 "The torque limit that indicates the available retarder torque which can be provided by the retarder at idle speed.";
CM_ SG_ 2566840830 RetarderCtrlMethod "This parameter identifies the number of steps used by the retarder.";
CM_ SG_ 2566840830 RetarderType "A vehicle retarder is a supplementary device to the wheel brakes for the driver to better control the vehicle.";
CM_ BO_ 2566844670 "Power Takeoff Information";
CM_ SG_ 2566844670 EngPTOSetSwitch "Switch signal of the PTO control activator which indicates that the activator is in the position set.";
CM_ SG_ 2566844670 EngPTOEnableSwitch "Switch signal which indicates that the PTO governor toggle switch is in the enabled position.";
CM_ BO_ 2566844928 "Fuel Economy (Liquid)";
CM_ SG_ 2566844928 EngAverageFuelEconomy "Average of instantaneous fuel economy for that segment of vehicle operation of interest.";
CM_ SG_ 2566844928 EngInstantaneousFuelEconomy "Current fuel economy at current vehicle velocity.";
CM_ SG_ 2566844928 EngFuelRate "Amount of fuel consumed by engine per unit of time.";
CM_ SG_ 2566844928 EngThrottlePos "The position of the valve used to regulate the supply of a fluid, usually air or fuel/air mixture, to an engine.";
CM_ BO_ 2566842624 "Fuel Consumption (Liquid)";
CM_ SG_ 2566842624 EngTotalFuelUsed "Accumulated amount of fuel used during vehicle operation.";
CM_ SG_ 2566842624 EngTripFuel "Fuel consumed during all or part of a journey.";
CM_ BO_ 2364542206 "Electronic Transmission Controller #8";
CM_ SG_ 2364542206 TransTorqueConverterRatio "Ratio of the transmissions torque converter output torque to torque converter input torque at current speed.";
CM_ BO_ 2566801924 "Electronic Transmission Controller 7";
CM_ SG_ 2566801924 TransShiftInhibitIndicator "State signal indicating a transmission request for the Shift Inhibit Indicator to be active or inactive.";
CM_ SG_ 2566801924 TransEngCrankEnable "State signal from the transmission indicating if the transmission�s status is such that engine cranking is allowed (i.";
CM_ SG_ 2566801924 TransServiceIndicator "Signal from transmission indicating that some aspect of the gearbox requires servicing.";
CM_ SG_ 2566801924 TransCurrRangeDisplayBlankState "State signal indicating a transmission request for the display of the Transmission Current Range parameter.";
CM_ BO_ 2565867006 "Electronic Transmission Controller 2";
CM_ SG_ 2565867006 TransCurrentRange "Range currently being commanded by the transmission control system.";
CM_ SG_ 2565867006 TransRqedRange "Range selected by the operator.";
CM_ SG_ 2565867006 TransActualGearRatio "Actual ratio of input shaft speed to output shaft speed.";
CM_ BO_ 2364539395 "Electronic Transmission Controller 1";
CM_ SG_ 2364539395 SrcAddrssOfCtrllngDvcFrTrnsCtrl "The source address of the SAE J1939 device currently controlling the transmission.";
CM_ SG_ 2364539395 TransInputShaftSpeed "Rotational velocity of the primary shaft transferring power into the transmission.";
CM_ SG_ 2364539395 ProgressiveShiftDisable "Command signal used to indicate that progressive shifting by the engine should be disallowed.";
CM_ SG_ 2364539395 PercentClutchSlip "Parameter which represents the ratio of input shaft speed to current engine speed (in percent).";
CM_ SG_ 2364539395 TransOutputShaftSpeed "Calculated speed of the transmission output shaft.";
CM_ SG_ 2364539395 TransShiftInProcess "Indicates that the transmission is in process of shifting from the current gear to the selected gear.";
CM_ SG_ 2364539395 TorqueConverterLockupEngaged "State signal which indicates whether the torque converter lockup is engaged.";
CM_ BO_ 2566843904 "Engine Temperature 1";
CM_ SG_ 2566843904 EngIntercoolerThermostatOpening "The current position of the thermostat used to regulate the temperature of the engine intercooler.";
CM_ SG_ 2566843904 EngIntercoolerTemp "Temperature of liquid found in the intercooler located after the turbocharger.";
CM_ SG_ 2566843904 EngTurboOilTemp "Temperature of the turbocharger lubricant.";
CM_ SG_ 2566843904 EngOilTemp1 "Temperature of the engine lubricant.";
CM_ SG_ 2566843904 EngFuelTemp "Temperature of fuel entering injectors.";
CM_ SG_ 2566843904 EngCoolantTemp "Temperature of liquid found in engine cooling system.";
CM_ BO_ 2565865475 "Electronic Retarder Controller 1";
CM_ SG_ 2565865475 ActlMxAvlblRtarderPercentTorque "This is the maximum amount of torque that the retarder can immediately deliver.";
CM_ SG_ 2565865475 SrcAddrssOfCtrllngDvcFrRtrdrCtrl "The source address of the SAE J1939 device currently controlling the retarder.";
CM_ SG_ 2565865475 EngCoolantLoadIncrease "Status of an event, external to the engine, that may increase the nominal temperature of the engine coolant liquid.";
CM_ SG_ 2565865475 IntendedRetarderPercentTorque "Braking torque of retarder that the retarder is currently trying to achieve.";
CM_ SG_ 2565865475 ActualRetarderPercentTorque "Actual braking torque of the retarder as a percent of retarder configuration reference torque SPN 556.";
CM_ SG_ 2565865475 RetarderEnableShiftAssistSwitch "Switch signal which indicates whether the operator wishes the retarder to be enabled for transmission shift assist.";
CM_ SG_ 2565865475 RetarderEnableBrakeAssistSwitch "Switch signal which indicates whether the operator wishes the retarder to be enabled for vehicle braking assist.";
CM_ SG_ 2565865475 RetarderTorqueMode "State signal which indicates which retarder torque mode is currently generating, limiting, or controlling the torque.";
CM_ BO_ 2566844414 "Engine Fluid Level/Pressure 1";
CM_ SG_ 2566844414 EngCoolantLevel "Ratio of volume of liquid found in engine cooling system to total cooling system volume.";
CM_ SG_ 2566844414 EngCoolantPress "Gage pressure of liquid found in engine cooling system.";
CM_ SG_ 2566844414 EngCrankcasePress "Gage pressure inside engine crankcase.";
CM_ SG_ 2566844414 EngOilPress "Gage pressure of oil in engine lubrication system as provided by oil pump.";
CM_ SG_ 2566844414 EngOilLevel "Ratio of current volume of engine sump oil to maximum required volume.";
CM_ SG_ 2566844414 EngExCrankcaseBlowbyPress "Differential crankcase blow-by pressure as measured through a tube with a venturi.";
CM_ SG_ 2566844414 EngFuelDeliveryPress "Gage pressure of fuel in system as delivered from supply pump to the injection pump.";
CM_ BO_ 2566840064 "Electronic Engine Controller 3";
CM_ SG_ 2566840064 EngsDesiredOperatingSpeed "An indication by the engine of the optimal operating speed of the engine for the current existing conditions.";
CM_ BO_ 2364539648 "Electronic Engine Controller 2";
CM_ SG_ 2364539648 AccelPedal2LowIdleSwitch "Switch signal which indicates the state of the accelerator pedal 2 low idle switch.";
CM_ SG_ 2364539648 RoadSpeedLimitStatus "Status (active or not active) of the system used to limit maximum vehicle velocity.";
CM_ SG_ 2364539648 AccelPedalKickdownSwitch "Switch signal which indicates whether the accelerator pedal kickdown switch is opened or closed.";
CM_ SG_ 2364539648 AccelPedal1LowIdleSwitch "Switch signal which indicates the state of the accelerator pedal 1 low idle switch.";
CM_ BO_ 2364539904 "Electronic Engine Controller 1";
CM_ SG_ 2364539904 EngStarterMode "There are several phases in a starting action and different reasons why a start cannot take place.";
CM_ SG_ 2364539904 SrcAddrssOfCtrllngDvcForEngCtrl "The source address of the SAE J1939 device currently controlling the engine.";
CM_ SG_ 2364539904 EngSpeed "Actual engine speed which is calculated over a minimum crankshaft angle of 720 degrees divided by the number of cylinders.";
CM_ SG_ 2364539904 ActualEngPercentTorque "The calculated output torque of the engine.";
CM_ SG_ 2364539904 DriversDemandEngPercentTorque "The requested torque output of the engine by the driver.";
CM_ SG_ 2364539904 EngTorqueMode0 "State signal which indicates which engine torque mode is currently generating, limiting, or controlling the torque.";
CM_ SG_ 2364539904 ActualEnginePercentTorqueHiRes "This parameter displays an additional torque in percent of the reference engine torque.";
CM_ BO_ 2566841342 "Engine Configuration";
CM_ SG_ 2566841342 SupportTSC1CtrlPurposeGroup4Of4 "This parameter indicates which TSC1 control purposes are supported in group 4 of 4.";
CM_ SG_ 2566841342 SupportTSC1CtrlPurposeGroup3Of4 "This parameter indicates which TSC1 control purposes are supported in group 3 of 4.";
CM_ SG_ 2566841342 SupportTSC1CtrlPurposeGroup2Of4 "This parameter indicates which TSC1 control purposes are supported in group 2 of 4.";
CM_ SG_ 2566841342 SupportTSC1CtrlPurposeGroup1Of4 "This parameter indicates which TSC1 control purposes are supported in group 1 of 4.";
CM_ SG_ 2566841342 EngDefaultTorqueLimit "Companion parameter to Transmission Torque Limit (SPN 1845).";
CM_ SG_ 2566841342 EngMomentOfInertia "Moment of inertia for the engine, including items driven full-time by the engine such as fuel, oil and cooling pumps.";
CM_ SG_ 2566841342 EngRqdTorqueCtrlRangeUpperLimit "The maximum engine torque that the engine will allow when operating in a torque control/limit mode.";
CM_ SG_ 2566841342 EngRqdTorqueCtrlRangeLowerLimit "The minimum engine torque that the engine will allow when operating in a torque control/limit mode.";
CM_ SG_ 2566841342 EngRqedSpeedCtrlRangeLowerLimit "The minimum engine speed that the engine will allow when operating in a speed control/limit mode.";
CM_ SG_ 2566841342 EngMxMomentaryOverrideTimeLimit "The maximum time limit allowed to override the engine's high idle speed.";
CM_ SG_ 2566841342 EngMxMmntaryOverrideSpeedPoint7 "The maximum engine speed above high idle allowed by the engine control during a momentary high idle override.";
CM_ SG_ 2566841342 EngReferenceTorque "This parameter is the 100% reference value for all defined indicated engine torque parameters.";
CM_ SG_ 2566841342 EngSpeedAtHighIdlePoint6 "Engine speed of high idle (point 6) of the engine torque map (see PGN 65251 and supporting document).";
CM_ SG_ 2566841342 EngSpeedAtPoint5 "Engine speed of point 3, 4, and 5 of the engine torque map (see PGN 65251 and supporting document).";
CM_ SG_ 2566841342 EngSpeedAtPoint4 "Engine speed of point 3, 4, and 5 of the engine torque map (see PGN 65251 and supporting document).";
CM_ SG_ 2566841342 EngSpeedAtPoint3 "Engine speed of point 3, 4, and 5 of the engine torque map (see PGN 65251 and supporting document).";
CM_ SG_ 2566841342 EngSpeedAtPoint2 "Engine speed of point 2 of the engine torque map (see PGN 65251 and supporting document).";
CM_ SG_ 2566841342 EngPercentTorqueAtIdlePoint1 "The torque limit that indicates the available engine torque which can be provided by the engine at idle speed.";
CM_ BO_ 2566767870 "Electronic Brake Controller 5";
CM_ SG_ 2566767870 BrakeTempWarning "This parameter indicates if the temperature in the service brakes exceeds a certain value.";
CM_ SG_ 2566767870 XBRAccelerationLimit "The brake system may temporarily or generally limit the maximum brake performance available for external systems.";
CM_ SG_ 2566767870 XBRActiveCtrlMode "This parameter indicates which XBR Control Mode is executed by the brake system.";
CM_ SG_ 2566767870 XBRSystemState "This parameter indicates which external brake control is allowed.";
CM_ SG_ 2566767870 FoundationBrakeUse "This parameter indicates if the brake system presently uses the foundation brakes.";
CM_ SG_ 2566767870 HillHolderMode "Signal which indicates the current mode of the hill holder function.";
CM_ SG_ 2566767870 HaltBrakeMode "Signal which indicates the current mode of the halt brake function.";
CM_ BO_ 2566827518 "Wheel Application Pressure High Range Information";
CM_ SG_ 2566827518 BrkAppPrssHghRngRrAxl3RghtWheel "The brake application pressure for the right wheel on the rear axle #3.";
CM_ SG_ 2566827518 BrkAppPrssHghRngRrAxl3LeftWheel "The brake application pressure for the left wheel on the rear axle #3.";
CM_ SG_ 2566827518 BrkAppPrssHghRngRrAxl2RghtWheel "The brake application pressure for the right wheel on the rear axle #2.";
CM_ SG_ 2566827518 BrkAppPrssHghRngRrAxl2LeftWheel "The brake application pressure for the left wheel on the rear axle #2.";
CM_ SG_ 2566827518 BrkAppPrssHghRngRrAxl1RghtWheel "The brake application pressure for the right wheel on the rear axle #1.";
CM_ SG_ 2566827518 BrkAppPrssHghRngRrAxl1LeftWheel "The brake application pressure for the left wheel on the rear axle #1.";
CM_ SG_ 2566827518 BrkAppPrssHghRngFrntAxlRghtWhel "The brake application pressure for the right wheel on the front axle.";
CM_ SG_ 2566827518 BrkAppPrssHghRngFrntAxlLftWheel "The brake application pressure for the left wheel on the front axle.";
CM_ BO_ 2566832126 "Wheel Speed Information";
CM_ SG_ 2566832126 RlativeSpeedRearAxle2RightWheel "The speed of the rear axle #2, right wheel relative to the front axle speed, SPN 904.";
CM_ SG_ 2566832126 RelativeSpeedRearAxle2LeftWheel "The speed of the rear axle #2, left wheel relative to the front axle speed, SPN 904.";
CM_ SG_ 2566832126 RlativeSpeedRearAxle1RightWheel "The speed of the rear axle #1, right wheel relative to the front axle speed, SPN 904.";
CM_ SG_ 2566832126 RelativeSpeedRearAxle1LeftWheel "The speed of the rear axle #1, left wheel relative to the front axle speed, SPN 904.";
CM_ SG_ 2566832126 RlativeSpeedFrontAxleRightWheel "The speed of the front axle, right wheel relative to the front axle speed, SPN 904.";
CM_ SG_ 2566832126 RelativeSpeedFrontAxleLeftWheel "The speed of the front axle, left wheel relative to the front axle speed, SPN 904.";
CM_ SG_ 2566832126 FrontAxleSpeed "The average speed of the two front wheels.";
CM_ BO_ 2565865982 "Electronic Brake Controller 1";
CM_ SG_ 2565865982 SrcAddrssOfCtrllngDvcFrBrkCntrl "The source address of the SAE J1939 device currently controlling the brake system.";
CM_ SG_ 2565865982 BrakePedalPos "Ratio of brake pedal position to maximum pedal position.";
CM_ SG_ 2565865982 TrctrMntdTrilerABSWarningSignal "This parameter commands the tractor-mounted trailer ABS optical warning signal.";
CM_ SG_ 2565865982 TrailerABSStatus "State signal which indicates that ABS in the trailer is actively controlling the brakes.";
CM_ SG_ 2565865982 HaltBrakeSwitch "Switch signal which indicates the position of the halt brake switch.";
CM_ SG_ 2565865982 ATC_ASRInformationSignal "This parameter commands the ATC/ASR driver information signal, for example a dash lamp.";
CM_ SG_ 2565865982 RemoteAccelEnableSwitch "Switch signal which indicates that the remote accelerator has been enabled and controls the engine.";
CM_ SG_ 2565865982 EngAuxEngShutdownSwitch "Switch signal which requests that all engine fueling stop.";
CM_ SG_ 2565865982 EngDerateSwitch "Switch signal used to activate the torque limiting feature of the engine.";
CM_ SG_ 2565865982 AccelInterlockSwitch "Switch signal used to disable the accelerator and remote accelerator inputs, causing the engine to return to idle.";
CM_ SG_ 2565865982 TractionCtrlOverrideSwitch "Switch signal which indicates the position of the traction control override switch.";
CM_ SG_ 2565865982 ASRHillHolderSwitch "Switch signal which indicates the position of the ASR �hill holder� switch.";
CM_ SG_ 2565865982 ASROffroadSwitch "Switch signal which indicates the position of the ASR off-road switch.";
CM_ SG_ 2565865982 ABSOffroadSwitch "Switch signal which indicates the position of the ABS off-road switch.";
CM_ SG_ 2565865982 EBSBrakeSwitch "Switch signal which indicates that the brake pedal is being pressed.";
CM_ SG_ 2565865982 AntiLockBrakingActive "State signal which indicates that the ABS is active.";
CM_ SG_ 2565865982 ASRBrakeCtrlActive "State signal which indicates that ASR brake control is active.";
CM_ SG_ 2565865982 ASREngCtrlActive "State signal which indicates that ASR engine control has been commanded to be active.";
CM_ BO_ 2566847742 "Dash Display";
CM_ SG_ 2566847742 CargoAmbientTemp "Temperature of air inside vehicle container used to accommodate cargo.";
CM_ SG_ 2566847742 EngFuelFilterDiffPress "Differential pressure measured across the fuel filter located between the fuel tank and the supply pump.";
CM_ SG_ 2566847742 FuelLevel "Ratio of volume of fuel to the total volume of fuel storage container.";
CM_ SG_ 2566847742 WasherFluidLevel "Ratio of volume of liquid to total container volume of fluid reservoir in windshield wash system.";
CM_ BO_ 2564872707 "Cab Message 1";
CM_ SG_ 2564872707 RqCabZoneHeating "Request to activate cab zone heating.";
CM_ SG_ 2564872707 RqEngZoneHeating "Request to activate engine zone heating.";
CM_ SG_ 2564872707 AuxHeaterModeRq "Request to activate the auxiliary heater.";
CM_ SG_ 2564872707 EngAutomaticStartEnableSwitch "Switch signal which enables the idle management system to be enabled.";
CM_ SG_ 2564872707 VhclLmtngSpdGvrnrIncrmentSwitch "Switch signal which increases the Vehicle Limiting Speed Governor (VLSG).";
CM_ SG_ 2564872707 VhclLmtngSpdGvrnrDcrementSwitch "Switch signal which decreases the Vehicle Limiting Speed Governor (VLSG).";
CM_ SG_ 2564872707 BatteryMainSwitchHoldRq "Request to hold the battery main switch.";
CM_ SG_ 2564872707 AuxHeaterCoolantPumpRq "Indicates whether to activate the auxiliary heater coolant water pump.";
CM_ SG_ 2564872707 CabInteriorTempCmd "Parameter used to command a certain cab interior temperature.";
CM_ SG_ 2564872707 RqedPercentFanSpeed "Fan speed as a ratio of the actual fan drive (current speed) to the fully engaged fan drive (maximum fan speed).";
CM_ BO_ 2566843136 "Component Identification";
CM_ BO_ 2566844926 "Cruise Control/Vehicle Speed";
CM_ SG_ 2566844926 EngShutdownOverrideSwitch "Switch signal which indicates the position of the engine shutdown override switch.";
CM_ SG_ 2566844926 EngTestModeSwitch "Switch signal which indicates the position of the engine test mode switch.";
CM_ SG_ 2566844926 EngIdleDecrementSwitch "Switch signal which indicates the position of the idle decrement switch.";
CM_ SG_ 2566844926 EngIdleIncrementSwitch "Switch signal which indicates the position of the idle increment switch.";
CM_ SG_ 2566844926 CruiseCtrlStates "This parameter is used to indicate the current state, or mode, of operation by the cruise control device.";
CM_ SG_ 2566844926 PtoGovernorState "This parameter is used to indicate the current state or mode of operation by the power takeoff (PTO) device.";
CM_ SG_ 2566844926 CruiseCtrlSetSpeed "Value of set (chosen) velocity of velocity control system.";
CM_ SG_ 2566844926 CruiseCtrlAccelerateSwitch "Switch signal of the cruise control activator which indicates that the activator is in the position �accelerate.";
CM_ SG_ 2566844926 CruiseCtrlResumeSwitch "Switch signal of the cruise control activator which indicates that the activator is in the position �resume.";
CM_ SG_ 2566844926 CruiseCtrlCoastSwitch "Switch signal of the cruise control activator which indicates that the activator is in the position �coast (decelerate).";
CM_ SG_ 2566844926 CruiseCtrlSetSwitch "Switch signal of the cruise control activator which indicates that the activator is in the position �set.";
CM_ SG_ 2566844926 ClutchSwitch "Switch signal which indicates that the clutch pedal is being pressed.";
CM_ SG_ 2566844926 BrakeSwitch "Switch signal which indicates that the driver operated brake foot pedal is being pressed.";
CM_ SG_ 2566844926 CruiseCtrlEnableSwitch "Switch signal which indicates that it is possible to manage the cruise control function.";
CM_ SG_ 2566844926 CruiseCtrlActive "Cruise control is switched on.";
CM_ SG_ 2566844926 WheelBasedVehicleSpeed "Speed of the vehicle as calculated from wheel or tailshaft speed.";
CM_ SG_ 2566844926 CruiseCtrlPauseSwitch "Switch signal which indicates the position of the Cruise Control Pause Switch used on Remote Cruise Control applications.";
CM_ SG_ 2566844926 ParkingBrakeSwitch "Switch signal which indicates when the parking brake is set.";
CM_ SG_ 2566844926 TwoSpeedAxleSwitch "Switch signal which indicates the current axle range.";
CM_ BO_ 2566835710 "Freeze frame parameters";
CM_ SG_ 2566835710 FreezeFrameLength "The freeze frame length shall be equal to the number of bytes in the required parameters plus the number of bytes in the
manufacturer specific parameters.";
CM_ SG_ 2566835710 EngSpeed "Actual engine speed which is calculated over a minimum crankshaft angle of 720 degrees divided by the number of cylinders.";
CM_ SG_ 2566835710 EngTorqueMode1 "State signal which indicates which engine torque mode is currently generating, limiting, or controlling the torque.";
CM_ SG_ 2566835710 EngTurboBoostPress "Gage pressure of air measured downstream on the compressor discharge side of the turbocharger.";
CM_ SG_ 2566835710 WheelBasedVehicleSpeed "Speed of the vehicle as calculated from wheel or tailshaft speed.";
CM_ BO_ 2566835454 "Diagnostic data clear/reset of previously active DTCs.";
CM_ BO_ 2566834944 "Previously active diagnostic trouble codes";
CM_ SG_ 2566834944 MalfunctionIndicatorLampStatus "A lamp used to relay only emissions-related trouble code information.";
CM_ SG_ 2566834944 RedStopLampState "This lamp is uesed to relay trouble code information that is of a severe enought condition that it warrants stopping the vehicle.";
CM_ SG_ 2566834944 AmberWarningLampStatus "This lamp is used to relay trouble code information that is reporting a problem with the vehicle system but the vehicle need
not be immediately stopped.";
CM_ SG_ 2566834944 ProtectLampStatus "This lamp is used to relay trouble code informatio that is reporting a problem with a vehicle system that is most
probably not electronic subsystem related.";
CM_ SG_ 2566834944 FlashRedStopLamp "This parameter provides the capability to flash the RSL (SPN 3039).";
CM_ SG_ 2566834944 FlashProtectLamp "This parameter provides the capability to flash the engine protect lamp (SPN 3041).";
CM_ SG_ 2566834944 FlashMalfuncIndicatorLamp "This parameter provides the capability to flash the MIL (SPN 3038).";
CM_ SG_ 2566834944 FlashAmberWarningLamp "This parameter provides the capability to flash the AWL (SPN 3040). ";
CM_ BO_ 2564816638 "Stop start broadcast";
CM_ SG_ 2564816638 HoldSignal "Indicator to all nodes that the communication ports that have been acted upon by the 'Stop start broadcast'
PGN are remaining in the modified state.";
CM_ SG_ 2564816638 J1939Network3 "Identifies the action to be performed on the SAE J1939 Network #3.";
CM_ SG_ 2564816638 J1939Network2 "Identifies the action to be performed on the SAE J1939 Network #2.";
CM_ SG_ 2564816638 ISO9141 "Identifies the action to be performed on the ISO9141 communications port.";
CM_ SG_ 2564816638 SAE_J1850 "Identifies the action to be performed on the SAE J1850 communications port.";
CM_ SG_ 2564816638 ManufacturerSpecificPort "Identifies the action to be performed on 'Other, manufacturer specific port' communications port.";
CM_ SG_ 2564816638 CurrentDataLink "Identifies the action to be performed on the communications port that this parameter was received.";
CM_ SG_ 2564816638 SAE_J1587 "Identifies the action to be performed on the SAE J1587 communications port.";
CM_ SG_ 2564816638 SAE_J1922 "Identifies the action to be performed on the SAE J1922 communications port.";
CM_ SG_ 2564816638 J1939Network1 "Identifies the action to be performed on the SAE J1939 Network #1, Primary vehicle communications port.";
CM_ BO_ 2566836992 "Diagnostic data clear/Reset for active DTCs";
CM_ BO_ 2565799678 "Address Claimed";
CM_ SG_ 2565799678 ManufacturerCode "Assigned by NMEA 2000 Committee";
CM_ SG_ 2565799678 IndustryGroup "0 = Global; 
   1  = On-Highway; 
   2  = Agricultural and Forestry; 
   3  = Construction; 
   4  = Marine;
   5  = Industrial - Process
          Control - Stationary (Gen-Sets)
   6  = Reserve for SAE
   7  = Reserve for SAE";
CM_ BO_ 2565603070 "Transport Protocol - Data Transfer";
CM_ BO_ 2565668606 "Transport Protocol - Connection Management";
CM_ SG_ 2565668606 TotalNumberOfPacketsEoMA "Total number of packets for BAM message.Total number of packets received for RTS/CTS message.Total number of packets for RTS/CTS message.";
CM_ SG_ 2565668606 TotalMessageSizeEoMA "Total message size (in bytes) for BAM message.Total message size (in bytes) for RTS/CTS message.Total message size (in bytes) for RTS/CTS message.";
CM_ SG_ 2565668606 TotalMessageSizeBAM "Total message size (in bytes) for BAM message.Total message size (in bytes) for RTS/CTS message.Total message size (in bytes) for RTS/CTS message.";
CM_ SG_ 2565668606 TotalNumberOfPacketsBAM "Total number of packets for BAM message.Total number of packets received for RTS/CTS message.Total number of packets for RTS/CTS message.";
CM_ SG_ 2565668606 ConnectionAbortReason "Reason for connection abort message.";
CM_ SG_ 2565668606 NextPacketNumberToBeSent "Next Packet Number to be sent (TP.CM_CTS)";
CM_ SG_ 2565668606 NumberOfPacketsThatCanBeSent "Number of Packets that can be sent (TP.CM_CTS)";
CM_ SG_ 2565668606 MaximumNumberOfPackets "Maximum number of packets for RTS/CTS message.";
CM_ SG_ 2565668606 TotalNumberOfPackets "Total number of packets for BAM message.Total number of packets received for RTS/CTS message.Total number of packets for RTS/CTS message.";
CM_ SG_ 2565668606 TotalMessageSize "Total message size (in bytes) for BAM message.Total message size (in bytes) for RTS/CTS message.Total message size (in bytes) for RTS/CTS message.";
CM_ BO_ 2565472505 "Request";
CM_ SG_ 2565472505 ParameterGroupNumber "PGN which is requested by Request2 message";
CM_ BO_ 2566838561 "Auxiliary Input/Output Status 1";
CM_ SG_ 2566838561 AuxIoChannel2 "Auxiliary channel of data (16 bit) read by the ECU.";
CM_ SG_ 2566838561 AuxIoChannel1 "Auxiliary channel of data (16 bit) read by the ECU.";
CM_ BO_ 2566845696 "Ambient Conditions";
CM_ SG_ 2566845696 RoadSurfaceTemp "Indicated temperature of road surface over which vehicle is operating.";
CM_ SG_ 2566845696 EngAirInletTemp "Temperature of air entering vehicle air induction system.";
CM_ SG_ 2566845696 AmbientAirTemp "Temperature of air surrounding vehicle.";
CM_ SG_ 2566845696 CabInteriorTemp "Temperature of air inside the part of the vehicle that encloses the driver and vehicle operating controls.";
CM_ SG_ 2566845696 BarometricPress "Absolute air pressure of the atmosphere.";
CM_ BO_ 2432593918 "Adaptive Cruise Control";
CM_ SG_ 2432593918 ACCDistanceAlertSignal "Signal to indicate to the operator that the ACC system is not able to maintain the distance to the target.";
CM_ SG_ 2432593918 ACCSystemShutoffWarning "Signal to warn the driver of system deactivation due to non-driver actions.";
CM_ SG_ 2432593918 ACCTargetDetected "Signal to indicate to the driver that the ACC system has detected a target.";
CM_ SG_ 2432593918 RoadCurvature "Estimated value of the current road curvature for use by the adaptive cruise control system.";
CM_ SG_ 2432593918 AdptveCruiseCtrlSetDistanceMode "Selected distance mode for adaptive cruise control.";
CM_ SG_ 2432593918 AdaptiveCruiseCtrlMode "This parameter is used to indicate the current state, or mode, of operation by the Adaptive Cruise Control (ACC) device.";
CM_ SG_ 2432593918 AdaptiveCruiseCtrlSetSpeed "Value of the desired (chosen) velocity of the adaptive cruise control system.";
CM_ SG_ 2432593918 DistanceToForwardVehicle "Distance to the preceding vehicle situated within 250 m in the same lane and moving in the same direction.";
CM_ SG_ 2432593918 SpeedOfForwardVehicle "Absolute velocity of the preceding vehicle situated within 250 m in the same lane and moving in the same direction.";
CM_ BO_ 2565406462 "Acknowledgment Message";
CM_ SG_ 2565406462 ParameterGroupNumber "PGN which is requested by Request2 message";
CM_ SG_ 2565406462 GroupFunctionValue "Group Function of PGN being acknowledged. This field identifies for a device the specific group function of a PGN being acknowledged or declined.  This field is not used if the PGN being acknowledged or declined is not a group function PGN.";
CM_ BO_ 2566846467 "Transmission Fluids 1";
CM_ SG_ 2566846467 TransOilLevelHigh_Low "Amount of current volume of transmission sump oil compared to recommended volume.";
CM_ SG_ 2566846467 TransOilTemp "Temperature of the transmission lubricant.";
CM_ SG_ 2566846467 TransOilPress "Gage pressure of lubrication fluid in transmission, measured after pump.";
CM_ SG_ 2566846467 TransOilLevel "Ratio of volume of transmission sump oil to recommended volume.";
CM_ SG_ 2566846467 ClutchPress "Gage pressure of oil within a wet clutch.";
CM_ BO_ 2566846208 "Vehicle Electrical Power #1";
CM_ SG_ 2566846208 KeyswitchBatteryPotential "Electrical potential measured at the input of the electronic control unit supplied through a switching device.";
CM_ SG_ 2566846208 BatteryPotential "Measured electrical potential of the battery.";
CM_ SG_ 2566846208 ChargingSystemPotential "Electrical potential measured at the charging system output.";
CM_ SG_ 2566846208 AltCurrent "Measure of electrical current flow from the alternator.";
CM_ SG_ 2566846208 NetBatteryCurrent "Net flow of electrical current into/out of the battery or batteries.";
BA_DEF_ SG_  "GenSigStartValue" INT 0 10000;
BA_DEF_ SG_  "GenSigSendType" ENUM  "Cyclic","OnWrite","reserved","OnChange","reserved","reserved","reserved","NoSigSendType";
BA_DEF_ SG_  "GenSigILSupport" ENUM  "Yes","No";
BA_DEF_ SG_  "GenSigEVName" STRING ;
BA_DEF_ SG_  "SPN" INT 0 524287;
BA_DEF_ SG_  "SigType" ENUM  "Default","Range","RangeSigned","ASCII","Discrete","Control","ReferencePGN","DTC","StringDelimiter","StringLength","StringLengthControl";
BA_DEF_ BO_  "GenMsgILSupport" ENUM  "Yes","No";
BA_DEF_ BO_  "GenMsgRequestable" INT 0 1;
BA_DEF_ BO_  "GenMsgSendType" ENUM  "cyclic","reserved","cyclicIfActive","reserved","reserved","reserved","reserved","reserved","noMsgSendType";
BA_DEF_ BO_  "VFrameFormat" ENUM  "StandardCAN","ExtendedCAN","reserved","J1939PG";
BA_DEF_ BO_  "GenMsgCycleTime" INT 0 3600000;
BA_DEF_ BU_  "NmStationAddress" INT 0 255;
BA_DEF_  "DatabaseVersion" STRING ;
BA_DEF_  "BusType" STRING ;
BA_DEF_  "ProtocolType" STRING ;
BA_DEF_  "SAE_J1939_75_SpecVersion" STRING ;
BA_DEF_  "SAE_J1939_21_SpecVersion" STRING ;
BA_DEF_  "SAE_J1939_73_SpecVersion" STRING ;
BA_DEF_  "SAE_J1939_71_SpecVersion" STRING ;
BA_DEF_DEF_  "GenSigStartValue" 0;
BA_DEF_DEF_  "GenSigSendType" "NoSigSendType";
BA_DEF_DEF_  "GenSigILSupport" "Yes";
BA_DEF_DEF_  "GenSigEVName" "Env@Nodename_@Signame";
BA_DEF_DEF_  "SPN" 0;
BA_DEF_DEF_  "SigType" "Default";
BA_DEF_DEF_  "GenMsgILSupport" "Yes";
BA_DEF_DEF_  "GenMsgRequestable" 1;
BA_DEF_DEF_  "GenMsgSendType" "noMsgSendType";
BA_DEF_DEF_  "VFrameFormat" "J1939PG";
BA_DEF_DEF_  "GenMsgCycleTime" 0;
BA_DEF_DEF_  "NmStationAddress" 254;
BA_DEF_DEF_  "DatabaseVersion" "";
BA_DEF_DEF_  "BusType" "";
BA_DEF_DEF_  "ProtocolType" "";
BA_DEF_DEF_  "SAE_J1939_75_SpecVersion" "";
BA_DEF_DEF_  "SAE_J1939_21_SpecVersion" "";
BA_DEF_DEF_  "SAE_J1939_73_SpecVersion" "";
BA_DEF_DEF_  "SAE_J1939_71_SpecVersion" "";
BA_ "DatabaseVersion" "6.1 SP2";
BA_ "BusType" "CAN";
BA_ "ProtocolType" "J1939";
BA_ "SAE_J1939_75_SpecVersion" "2005-10";
BA_ "SAE_J1939_21_SpecVersion" "2006-10";
BA_ "SAE_J1939_73_SpecVersion" "2004-09";
BA_ "SAE_J1939_71_SpecVersion" "2006-07";
BA_ "NmStationAddress" BU_ JetXCI1 208;
BA_ "NmStationAddress" BU_ Bordrechner4 250;
BA_ "NmStationAddress" BU_ Bordrechner3 249;
BA_ "NmStationAddress" BU_ Bordrechner2 242;
BA_ "NmStationAddress" BU_ Bordrechner1 241;
BA_ "NmStationAddress" BU_ Hydrop_Joystick 132;
BA_ "NmStationAddress" BU_ JetEIM1_JIM1_2 214;
BA_ "NmStationAddress" BU_ JetEIM1_JIM1_1 212;
BA_ "NmStationAddress" BU_ JetEIM1_JIM1_0 210;
BA_ "NmStationAddress" BU_ Getriebe2 5;
BA_ "NmStationAddress" BU_ Getriebe1 4;
BA_ "NmStationAddress" BU_ Getriebe0 3;
BA_ "NmStationAddress" BU_ Retarder_Motor 15;
BA_ "NmStationAddress" BU_ Motor 0;
BA_ "NmStationAddress" BU_ Bordrechner0 33;
BA_ "NmStationAddress" BU_ Luefter 218;
BA_ "GenMsgSendType" BO_ 2566845952 0;
BA_ "GenMsgCycleTime" BO_ 2566845952 500;
BA_ "GenMsgSendType" BO_ 2566832638 0;
BA_ "GenMsgCycleTime" BO_ 2566832638 1000;
BA_ "GenMsgSendType" BO_ 2566805246 0;
BA_ "GenMsgCycleTime" BO_ 2566805246 1000;
BA_ "GenMsgSendType" BO_ 2365484286 0;
BA_ "GenMsgCycleTime" BO_ 2365484286 50;
BA_ "GenMsgSendType" BO_ 2566847235 0;
BA_ "GenMsgCycleTime" BO_ 2566847235 1000;
BA_ "GenMsgSendType" BO_ 2566844670 0;
BA_ "GenMsgCycleTime" BO_ 2566844670 100;
BA_ "GenMsgSendType" BO_ 2566844928 0;
BA_ "GenMsgCycleTime" BO_ 2566844928 100;
BA_ "GenMsgSendType" BO_ 2364542206 0;
BA_ "GenMsgCycleTime" BO_ 2364542206 20;
BA_ "GenMsgSendType" BO_ 2566801924 0;
BA_ "GenMsgCycleTime" BO_ 2566801924 100;
BA_ "GenMsgSendType" BO_ 2565867006 0;
BA_ "GenMsgCycleTime" BO_ 2565867006 100;
BA_ "GenMsgSendType" BO_ 2364539395 0;
BA_ "GenMsgCycleTime" BO_ 2364539395 10;
BA_ "GenMsgSendType" BO_ 2566843904 0;
BA_ "GenMsgCycleTime" BO_ 2566843904 1000;
BA_ "GenMsgSendType" BO_ 2565865475 0;
BA_ "GenMsgCycleTime" BO_ 2565865475 100;
BA_ "GenMsgSendType" BO_ 2566844414 0;
BA_ "GenMsgCycleTime" BO_ 2566844414 500;
BA_ "GenMsgSendType" BO_ 2566840064 0;
BA_ "GenMsgCycleTime" BO_ 2566840064 250;
BA_ "GenMsgSendType" BO_ 2364539648 0;
BA_ "GenMsgCycleTime" BO_ 2364539648 50;
BA_ "GenMsgSendType" BO_ 2364539904 0;
BA_ "GenMsgCycleTime" BO_ 2364539904 100;
BA_ "GenMsgSendType" BO_ 2566767870 0;
BA_ "GenMsgCycleTime" BO_ 2566767870 100;
BA_ "GenMsgSendType" BO_ 2566827518 0;
BA_ "GenMsgCycleTime" BO_ 2566827518 100;
BA_ "GenMsgSendType" BO_ 2566832126 0;
BA_ "GenMsgCycleTime" BO_ 2566832126 100;
BA_ "GenMsgSendType" BO_ 2565865982 0;
BA_ "GenMsgCycleTime" BO_ 2565865982 100;
BA_ "GenMsgSendType" BO_ 2566847742 0;
BA_ "GenMsgCycleTime" BO_ 2566847742 1000;
BA_ "GenMsgSendType" BO_ 2564872707 0;
BA_ "GenMsgCycleTime" BO_ 2564872707 1000;
BA_ "GenMsgSendType" BO_ 2566844926 0;
BA_ "GenMsgCycleTime" BO_ 2566844926 100;
BA_ "GenMsgSendType" BO_ 2566845696 0;
BA_ "GenMsgCycleTime" BO_ 2566845696 1000;
BA_ "GenMsgSendType" BO_ 2432593918 0;
BA_ "GenMsgCycleTime" BO_ 2432593918 100;
BA_ "GenMsgSendType" BO_ 2566846467 0;
BA_ "GenMsgCycleTime" BO_ 2566846467 1000;
BA_ "GenMsgSendType" BO_ 2566846208 0;
BA_ "GenMsgCycleTime" BO_ 2566846208 1000;
BA_ "SPN" SG_ 3221225472 ExhaustGasMass 3236;
BA_ "SigType" SG_ 3221225472 ExhaustGasMass 1;
BA_ "SPN" SG_ 3221225472 AftrTrtmntIntakeDewPointMessage 3237;
BA_ "SPN" SG_ 3221225472 AftrTrtmntExhustDewPointMessage 3238;
BA_ "SPN" SG_ 3221225472 EngTurboBoostPress 102;
BA_ "SigType" SG_ 3221225472 EngTurboBoostPress 1;
BA_ "SigType" SG_ 3221225472 DTC5 7;
BA_ "SigType" SG_ 3221225472 DTC4 7;
BA_ "SigType" SG_ 3221225472 DTC3 7;
BA_ "SigType" SG_ 3221225472 DTC2 7;
BA_ "SigType" SG_ 3221225472 DTC1 7;
BA_ "SPN" SG_ 3221225472 EstEngPrsticLossesPercentTorque 2978;
BA_ "SigType" SG_ 3221225472 EstEngPrsticLossesPercentTorque 1;
BA_ "SPN" SG_ 3221225472 EngsDsrdOprtngSpdAsymmtryAdjstmn 519;
BA_ "SigType" SG_ 3221225472 EngsDsrdOprtngSpdAsymmtryAdjstmn 1;
BA_ "SPN" SG_ 3221225472 EngsDesiredOperatingSpeed 515;
BA_ "SigType" SG_ 3221225472 EngsDesiredOperatingSpeed 1;
BA_ "SPN" SG_ 3221225472 NominalFrictionPercentTorque 514;
BA_ "SigType" SG_ 3221225472 NominalFrictionPercentTorque 1;
BA_ "SPN" SG_ 3221225472 OperatorPTOMemorySelectSwitch 2897;
BA_ "SigType" SG_ 3221225472 OperatorPTOMemorySelectSwitch 4;
BA_ "SPN" SG_ 3221225472 EngPTOAccelerateSwitch 981;
BA_ "SigType" SG_ 3221225472 EngPTOAccelerateSwitch 4;
BA_ "SPN" SG_ 3221225472 EngPTOResumeSwitch 982;
BA_ "SigType" SG_ 3221225472 EngPTOResumeSwitch 4;
BA_ "SPN" SG_ 3221225472 EngPTOCoast_DecelerateSwitch 983;
BA_ "SigType" SG_ 3221225472 EngPTOCoast_DecelerateSwitch 4;
BA_ "SPN" SG_ 3221225472 EngRmtPTOVriableSpeedCtrlSwitch 978;
BA_ "SigType" SG_ 3221225472 EngRmtPTOVriableSpeedCtrlSwitch 4;
BA_ "SPN" SG_ 3221225472 EngRmtPTOPrprgrmmdSpdCtrlSwitch 979;
BA_ "SigType" SG_ 3221225472 EngRmtPTOPrprgrmmdSpdCtrlSwitch 4;
BA_ "SPN" SG_ 3221225472 PowerTakeoffSetSpeed 187;
BA_ "SigType" SG_ 3221225472 PowerTakeoffSetSpeed 1;
BA_ "SPN" SG_ 3221225472 PowerTakeoffSpeed 186;
BA_ "SigType" SG_ 3221225472 PowerTakeoffSpeed 1;
BA_ "SPN" SG_ 3221225472 PowerTakeoffOilTemp 90;
BA_ "SigType" SG_ 3221225472 PowerTakeoffOilTemp 1;
BA_ "SPN" SG_ 3221225472 RmtPTOPrprgrmmdSpeedCtrlSwitch2 3447;
BA_ "SigType" SG_ 3221225472 RmtPTOPrprgrmmdSpeedCtrlSwitch2 4;
BA_ "SPN" SG_ 3221225472 AuxInputIgnoreSwitch 3448;
BA_ "SigType" SG_ 3221225472 AuxInputIgnoreSwitch 4;
BA_ "SPN" SG_ 3221225472 Make 586;
BA_ "SigType" SG_ 3221225472 Make 8;
BA_ "SigType" SG_ 3221225472 DTC1 7;
BA_ "GenSigStartValue" SG_ 2566850260 OilTemperature 40;
BA_ "GenSigStartValue" SG_ 2566850004 OilTemperature 40;
BA_ "SPN" SG_ 2566834688 MalfunctionIndicatorLampStatus 1213;
BA_ "SigType" SG_ 2566834688 MalfunctionIndicatorLampStatus 4;
BA_ "SPN" SG_ 2566834688 RedStopLampState 623;
BA_ "SigType" SG_ 2566834688 RedStopLampState 4;
BA_ "SPN" SG_ 2566834688 AmberWarningLampStatus 624;
BA_ "SigType" SG_ 2566834688 AmberWarningLampStatus 4;
BA_ "SPN" SG_ 2566834688 ProtectLampStatus 987;
BA_ "SigType" SG_ 2566834688 ProtectLampStatus 4;
BA_ "SPN" SG_ 2566834688 FlashRedStopLamp 3039;
BA_ "SPN" SG_ 2566834688 FlashProtectLamp 3041;
BA_ "SPN" SG_ 2566834688 FlashMalfuncIndicatorLamp 3038;
BA_ "SigType" SG_ 2566834688 FlashMalfuncIndicatorLamp 4;
BA_ "SPN" SG_ 2566834688 FlashAmberWarningLamp 3040;
BA_ "GenSigStartValue" SG_ 2564545057 KuehlwasserTempNT 40;
BA_ "GenSigStartValue" SG_ 2564545057 KuehlwasserTempHT 40;
BA_ "SPN" SG_ 2566845952 EngCoolantFilterDiffPress 112;
BA_ "SigType" SG_ 2566845952 EngCoolantFilterDiffPress 1;
BA_ "SPN" SG_ 2566845952 EngExhaustGasTemp 173;
BA_ "SigType" SG_ 2566845952 EngExhaustGasTemp 1;
BA_ "SPN" SG_ 2566845952 EngAirFilter1DiffPress 107;
BA_ "SigType" SG_ 2566845952 EngAirFilter1DiffPress 1;
BA_ "SPN" SG_ 2566845952 EngAirInletPress 106;
BA_ "SigType" SG_ 2566845952 EngAirInletPress 1;
BA_ "SPN" SG_ 2566845952 EngIntakeManifold1Temp 105;
BA_ "SigType" SG_ 2566845952 EngIntakeManifold1Temp 1;
BA_ "SPN" SG_ 2566845952 EngParticulateTrapInletPress 81;
BA_ "SigType" SG_ 2566845952 EngParticulateTrapInletPress 1;
BA_ "SPN" SG_ 2566841854 EngTotalRevolutions 249;
BA_ "SigType" SG_ 2566841854 EngTotalRevolutions 1;
BA_ "SPN" SG_ 2566841854 EngTotalHoursOfOperation 247;
BA_ "SigType" SG_ 2566841854 EngTotalHoursOfOperation 1;
BA_ "SPN" SG_ 2566832638 HighResolutionTripDistance 918;
BA_ "SigType" SG_ 2566832638 HighResolutionTripDistance 1;
BA_ "SPN" SG_ 2566832638 HghRslutionTotalVehicleDistance 917;
BA_ "SigType" SG_ 2566832638 HghRslutionTotalVehicleDistance 1;
BA_ "SPN" SG_ 2348810243 ControlPurpose 3350;
BA_ "SigType" SG_ 2348810243 ControlPurpose 4;
BA_ "SPN" SG_ 2348810243 TransmissionRate 3349;
BA_ "SigType" SG_ 2348810243 TransmissionRate 4;
BA_ "SPN" SG_ 2348810243 EngRqedTorque_TorqueLimit 518;
BA_ "SigType" SG_ 2348810243 EngRqedTorque_TorqueLimit 1;
BA_ "SPN" SG_ 2348810243 EngRqedSpeed_SpeedLimit 898;
BA_ "SigType" SG_ 2348810243 EngRqedSpeed_SpeedLimit 1;
BA_ "SPN" SG_ 2348810243 OverrideCtrlModePriority 897;
BA_ "SigType" SG_ 2348810243 OverrideCtrlModePriority 4;
BA_ "SPN" SG_ 2348810243 EngRqedSpeedCtrlConditions 696;
BA_ "SigType" SG_ 2348810243 EngRqedSpeedCtrlConditions 4;
BA_ "SPN" SG_ 2348810243 EngOverrideCtrlMode 695;
BA_ "SigType" SG_ 2348810243 EngOverrideCtrlMode 4;
BA_ "SPN" SG_ 2348810243 EngineRequestedTorqueHiRes 4191;
BA_ "SigType" SG_ 2348810243 EngineRequestedTorqueHiRes 1;
BA_ "SPN" SG_ 2566805246 CatalystTankTemp 3031;
BA_ "SigType" SG_ 2566805246 CatalystTankTemp 1;
BA_ "SPN" SG_ 2566805246 CatalystTankLevel 1761;
BA_ "SigType" SG_ 2566805246 CatalystTankLevel 1;
BA_ "SPN" SG_ 2566805246 CatalystTankLevelPreliminaryFMI 3532;
BA_ "SigType" SG_ 2566805246 CatalystTankLevelPreliminaryFMI 4;
BA_ "SPN" SG_ 2566805246 CatalystTankLevel2 3517;
BA_ "SigType" SG_ 2566805246 CatalystTankLevel2 1;
BA_ "SPN" SG_ 2566842110 LocalHourOffset 1602;
BA_ "SigType" SG_ 2566842110 LocalHourOffset 1;
BA_ "SPN" SG_ 2566842110 LocalMinuteOffset 1601;
BA_ "SigType" SG_ 2566842110 LocalMinuteOffset 1;
BA_ "SPN" SG_ 2566842110 Year 964;
BA_ "SigType" SG_ 2566842110 Year 1;
BA_ "SPN" SG_ 2566842110 Day 962;
BA_ "SigType" SG_ 2566842110 Day 1;
BA_ "SPN" SG_ 2566842110 Month 963;
BA_ "SigType" SG_ 2566842110 Month 1;
BA_ "SPN" SG_ 2566842110 Hours 961;
BA_ "SigType" SG_ 2566842110 Hours 1;
BA_ "SPN" SG_ 2566842110 Minutes 960;
BA_ "SigType" SG_ 2566842110 Minutes 1;
BA_ "SPN" SG_ 2566842110 Seconds 959;
BA_ "SigType" SG_ 2566842110 Seconds 1;
BA_ "SPN" SG_ 2365484286 TachographVehicleSpeed 1624;
BA_ "SigType" SG_ 2365484286 TachographVehicleSpeed 1;
BA_ "SPN" SG_ 2365484286 TachographOutputShaftSpeed 1623;
BA_ "SigType" SG_ 2365484286 TachographOutputShaftSpeed 1;
BA_ "SPN" SG_ 2365484286 DirectionIndicator 1619;
BA_ "SigType" SG_ 2365484286 DirectionIndicator 4;
BA_ "SPN" SG_ 2365484286 TachographPerformance 1620;
BA_ "SigType" SG_ 2365484286 TachographPerformance 4;
BA_ "SPN" SG_ 2365484286 HandlingInformation 1621;
BA_ "SigType" SG_ 2365484286 HandlingInformation 4;
BA_ "SPN" SG_ 2365484286 SystemEvent 1622;
BA_ "SigType" SG_ 2365484286 SystemEvent 4;
BA_ "SPN" SG_ 2365484286 DriverCardDriver2 1616;
BA_ "SigType" SG_ 2365484286 DriverCardDriver2 4;
BA_ "SPN" SG_ 2365484286 Driver2TimeRelatedStates 1618;
BA_ "SigType" SG_ 2365484286 Driver2TimeRelatedStates 4;
BA_ "SPN" SG_ 2365484286 Overspeed 1614;
BA_ "SigType" SG_ 2365484286 Overspeed 4;
BA_ "SPN" SG_ 2365484286 DriverCardDriver1 1615;
BA_ "SigType" SG_ 2365484286 DriverCardDriver1 4;
BA_ "SPN" SG_ 2365484286 Driver1TimeRelatedStates 1617;
BA_ "SigType" SG_ 2365484286 Driver1TimeRelatedStates 4;
BA_ "SPN" SG_ 2365484286 DriveRecognize 1611;
BA_ "SigType" SG_ 2365484286 DriveRecognize 4;
BA_ "SPN" SG_ 2365484286 Driver2WorkingState 1613;
BA_ "SigType" SG_ 2365484286 Driver2WorkingState 4;
BA_ "SPN" SG_ 2365484286 Driver1WorkingState 1612;
BA_ "SigType" SG_ 2365484286 Driver1WorkingState 4;
BA_ "SPN" SG_ 2566840835 TransGearRatio 581;
BA_ "SigType" SG_ 2566840835 TransGearRatio 1;
BA_ "SPN" SG_ 2566840835 NumberOfForwardGearRatios 957;
BA_ "SigType" SG_ 2566840835 NumberOfForwardGearRatios 1;
BA_ "SPN" SG_ 2566840835 NumberOfReverseGearRatios 958;
BA_ "SigType" SG_ 2566840835 NumberOfReverseGearRatios 1;
BA_ "SPN" SG_ 2348876577 TrnsShftSlctorDisplayModeSwitch 2985;
BA_ "SigType" SG_ 2348876577 TrnsShftSlctorDisplayModeSwitch 4;
BA_ "SPN" SG_ 2348876577 TransMode4 1855;
BA_ "SigType" SG_ 2348876577 TransMode4 4;
BA_ "SPN" SG_ 2348876577 TransMode3 1854;
BA_ "SigType" SG_ 2348876577 TransMode3 4;
BA_ "SPN" SG_ 2348876577 TransMode2 1853;
BA_ "SigType" SG_ 2348876577 TransMode2 4;
BA_ "SPN" SG_ 2348876577 TransMode1 1852;
BA_ "SigType" SG_ 2348876577 TransMode1 4;
BA_ "SPN" SG_ 2348876577 DisengageDiffLockRqCentralRear 691;
BA_ "SigType" SG_ 2348876577 DisengageDiffLockRqCentralRear 4;
BA_ "SPN" SG_ 2348876577 DisengageDiffLockRqCentralFront 690;
BA_ "SigType" SG_ 2348876577 DisengageDiffLockRqCentralFront 4;
BA_ "SPN" SG_ 2348876577 DisengageDiffLockRqCentral 689;
BA_ "SigType" SG_ 2348876577 DisengageDiffLockRqCentral 4;
BA_ "SPN" SG_ 2348876577 DisengageDiffLockRqRearAxle2 688;
BA_ "SigType" SG_ 2348876577 DisengageDiffLockRqRearAxle2 4;
BA_ "SPN" SG_ 2348876577 DisengageDiffLockRqRearAxle1 687;
BA_ "SigType" SG_ 2348876577 DisengageDiffLockRqRearAxle1 4;
BA_ "SPN" SG_ 2348876577 DisengageDiffLockRqFrontAxle2 686;
BA_ "SigType" SG_ 2348876577 DisengageDiffLockRqFrontAxle2 4;
BA_ "SPN" SG_ 2348876577 DisengageDiffLockRqFrontAxle1 685;
BA_ "SigType" SG_ 2348876577 DisengageDiffLockRqFrontAxle1 4;
BA_ "SPN" SG_ 2348876577 TransRqedGear 525;
BA_ "SigType" SG_ 2348876577 TransRqedGear 1;
BA_ "SPN" SG_ 2348876577 RqedPercentClutchSlip 684;
BA_ "SigType" SG_ 2348876577 RqedPercentClutchSlip 1;
BA_ "SPN" SG_ 2348876577 DisengageDrivelineRq 683;
BA_ "SigType" SG_ 2348876577 DisengageDrivelineRq 4;
BA_ "SPN" SG_ 2348876577 TorqueConverterLockupDisableRq 682;
BA_ "SigType" SG_ 2348876577 TorqueConverterLockupDisableRq 4;
BA_ "SPN" SG_ 2348876577 TransGearShiftInhibitRq 681;
BA_ "SigType" SG_ 2348876577 TransGearShiftInhibitRq 4;
BA_ "SPN" SG_ 2566838784 Sub1Version 234;
BA_ "SigType" SG_ 2566838784 Sub1Version 8;
BA_ "SPN" SG_ 2566838784 SpecialSoftwareVersion 234;
BA_ "SigType" SG_ 2566838784 SpecialSoftwareVersion 8;
BA_ "SPN" SG_ 2566838784 SoftwareVersion 234;
BA_ "SigType" SG_ 2566838784 SoftwareVersion 8;
BA_ "SPN" SG_ 2566838784 NmbrOfSftwrIdentificationFields 965;
BA_ "SigType" SG_ 2566838784 NmbrOfSftwrIdentificationFields 1;
BA_ "SPN" SG_ 2566847235 HydRetarderOilTemp 120;
BA_ "SigType" SG_ 2566847235 HydRetarderOilTemp 1;
BA_ "SPN" SG_ 2566847235 HydRetarderPress 119;
BA_ "SigType" SG_ 2566847235 HydRetarderPress 1;
BA_ "SPN" SG_ 2631859966 EngBuildHoursReset 1211;
BA_ "SigType" SG_ 2631859966 EngBuildHoursReset 4;
BA_ "SPN" SG_ 2631859966 ServiceComponentIdentification 1584;
BA_ "SigType" SG_ 2631859966 ServiceComponentIdentification 1;
BA_ "SPN" SG_ 2631859966 TripGroup2Proprietary 989;
BA_ "SigType" SG_ 2631859966 TripGroup2Proprietary 4;
BA_ "SPN" SG_ 2631859966 TripGroup1 988;
BA_ "SigType" SG_ 2631859966 TripGroup1 4;
BA_ "SPN" SG_ 2566840830 PercentTorqueAtPeakTorquePoint5 555;
BA_ "SigType" SG_ 2566840830 PercentTorqueAtPeakTorquePoint5 1;
BA_ "SPN" SG_ 2566840830 ReferenceRetarderTorque 556;
BA_ "SigType" SG_ 2566840830 ReferenceRetarderTorque 1;
BA_ "SPN" SG_ 2566840830 RetarderSpeedAtPeakTorquePoint5 547;
BA_ "SigType" SG_ 2566840830 RetarderSpeedAtPeakTorquePoint5 1;
BA_ "SPN" SG_ 2566840830 PercentTorqueAtPoint4 554;
BA_ "SigType" SG_ 2566840830 PercentTorqueAtPoint4 1;
BA_ "SPN" SG_ 2566840830 RetarderSpeedAtPoint4 550;
BA_ "SigType" SG_ 2566840830 RetarderSpeedAtPoint4 1;
BA_ "SPN" SG_ 2566840830 PercentTorqueAtPoint3 553;
BA_ "SigType" SG_ 2566840830 PercentTorqueAtPoint3 1;
BA_ "SPN" SG_ 2566840830 RetarderSpeedAtPoint3 549;
BA_ "SigType" SG_ 2566840830 RetarderSpeedAtPoint3 1;
BA_ "SPN" SG_ 2566840830 PercentTorqueAtMaxSpeedPoint2 552;
BA_ "SigType" SG_ 2566840830 PercentTorqueAtMaxSpeedPoint2 1;
BA_ "SPN" SG_ 2566840830 MaxRetarderSpeedPoint2 548;
BA_ "SigType" SG_ 2566840830 MaxRetarderSpeedPoint2 1;
BA_ "SPN" SG_ 2566840830 PercentTorqueAtIdlePoint1 551;
BA_ "SigType" SG_ 2566840830 PercentTorqueAtIdlePoint1 1;
BA_ "SPN" SG_ 2566840830 RetarderSpeedAtIdlePoint1 546;
BA_ "SigType" SG_ 2566840830 RetarderSpeedAtIdlePoint1 1;
BA_ "SPN" SG_ 2566840830 RetarderCtrlMethod 557;
BA_ "SigType" SG_ 2566840830 RetarderCtrlMethod 1;
BA_ "SPN" SG_ 2566840830 RetarderLocation 902;
BA_ "SigType" SG_ 2566840830 RetarderLocation 4;
BA_ "SPN" SG_ 2566840830 RetarderType 901;
BA_ "SigType" SG_ 2566840830 RetarderType 4;
BA_ "SPN" SG_ 2566844670 EngPTOSetSwitch 984;
BA_ "SigType" SG_ 2566844670 EngPTOSetSwitch 4;
BA_ "SPN" SG_ 2566844670 EngPTOEnableSwitch 980;
BA_ "SigType" SG_ 2566844670 EngPTOEnableSwitch 4;
BA_ "SPN" SG_ 2566844928 EngAverageFuelEconomy 185;
BA_ "SigType" SG_ 2566844928 EngAverageFuelEconomy 1;
BA_ "SPN" SG_ 2566844928 EngInstantaneousFuelEconomy 184;
BA_ "SigType" SG_ 2566844928 EngInstantaneousFuelEconomy 1;
BA_ "SPN" SG_ 2566844928 EngFuelRate 183;
BA_ "SigType" SG_ 2566844928 EngFuelRate 1;
BA_ "SPN" SG_ 2566844928 EngThrottle2Pos 3673;
BA_ "SigType" SG_ 2566844928 EngThrottle2Pos 1;
BA_ "SPN" SG_ 2566844928 EngThrottlePos 51;
BA_ "SigType" SG_ 2566844928 EngThrottlePos 1;
BA_ "SPN" SG_ 2566842624 EngTotalFuelUsed 250;
BA_ "SigType" SG_ 2566842624 EngTotalFuelUsed 1;
BA_ "SPN" SG_ 2566842624 EngTripFuel 182;
BA_ "SigType" SG_ 2566842624 EngTripFuel 1;
BA_ "SPN" SG_ 2364542206 TransTorqueConverterRatio 3030;
BA_ "SigType" SG_ 2364542206 TransTorqueConverterRatio 1;
BA_ "SPN" SG_ 2566801924 TransRqedGearFeedback 3289;
BA_ "SigType" SG_ 2566801924 TransRqedGearFeedback 1;
BA_ "SPN" SG_ 2566801924 TransMode1Indicator 2536;
BA_ "SigType" SG_ 2566801924 TransMode1Indicator 4;
BA_ "SPN" SG_ 2566801924 TransMode2Indicator 2537;
BA_ "SigType" SG_ 2566801924 TransMode2Indicator 4;
BA_ "SPN" SG_ 2566801924 TransMode3Indicator 2538;
BA_ "SigType" SG_ 2566801924 TransMode3Indicator 4;
BA_ "SPN" SG_ 2566801924 TransMode4Indicator 2539;
BA_ "SigType" SG_ 2566801924 TransMode4Indicator 4;
BA_ "SPN" SG_ 2566801924 TransShiftInhibitIndicator 1851;
BA_ "SigType" SG_ 2566801924 TransShiftInhibitIndicator 4;
BA_ "SPN" SG_ 2566801924 TransEngCrankEnable 2900;
BA_ "SigType" SG_ 2566801924 TransEngCrankEnable 4;
BA_ "SPN" SG_ 2566801924 ActiveShiftConsoleIndicator 2945;
BA_ "SigType" SG_ 2566801924 ActiveShiftConsoleIndicator 4;
BA_ "SPN" SG_ 2566801924 TransReadyForBrakeRelease 3086;
BA_ "SigType" SG_ 2566801924 TransReadyForBrakeRelease 4;
BA_ "SPN" SG_ 2566801924 TransRqedRangeDisplayFlashState 1849;
BA_ "SigType" SG_ 2566801924 TransRqedRangeDisplayFlashState 4;
BA_ "SPN" SG_ 2566801924 TransRqedRangeDisplayBlankState 1850;
BA_ "SigType" SG_ 2566801924 TransRqedRangeDisplayBlankState 4;
BA_ "SPN" SG_ 2566801924 TransServiceIndicator 4178;
BA_ "SigType" SG_ 2566801924 TransServiceIndicator 4;
BA_ "SPN" SG_ 2566801924 TransCurrRangeDisplayBlankState 4176;
BA_ "SigType" SG_ 2566801924 TransCurrRangeDisplayBlankState 4;
BA_ "SPN" SG_ 2565867006 TransCurrentRange 163;
BA_ "SigType" SG_ 2565867006 TransCurrentRange 1;
BA_ "SPN" SG_ 2565867006 TransRqedRange 162;
BA_ "SigType" SG_ 2565867006 TransRqedRange 1;
BA_ "SPN" SG_ 2565867006 TransCurrentGear 523;
BA_ "SigType" SG_ 2565867006 TransCurrentGear 1;
BA_ "SPN" SG_ 2565867006 TransActualGearRatio 526;
BA_ "SigType" SG_ 2565867006 TransActualGearRatio 1;
BA_ "SPN" SG_ 2565867006 TransSelectedGear 524;
BA_ "SigType" SG_ 2565867006 TransSelectedGear 1;
BA_ "SPN" SG_ 2364539395 SrcAddrssOfCtrllngDvcFrTrnsCtrl 1482;
BA_ "SigType" SG_ 2364539395 SrcAddrssOfCtrllngDvcFrTrnsCtrl 1;
BA_ "SPN" SG_ 2364539395 TransInputShaftSpeed 161;
BA_ "SigType" SG_ 2364539395 TransInputShaftSpeed 1;
BA_ "SPN" SG_ 2364539395 ProgressiveShiftDisable 607;
BA_ "SigType" SG_ 2364539395 ProgressiveShiftDisable 4;
BA_ "SPN" SG_ 2364539395 EngMomentaryOverspeedEnable 606;
BA_ "SigType" SG_ 2364539395 EngMomentaryOverspeedEnable 4;
BA_ "SPN" SG_ 2364539395 PercentClutchSlip 522;
BA_ "SigType" SG_ 2364539395 PercentClutchSlip 1;
BA_ "SPN" SG_ 2364539395 TransOutputShaftSpeed 191;
BA_ "SigType" SG_ 2364539395 TransOutputShaftSpeed 1;
BA_ "SPN" SG_ 2364539395 TransShiftInProcess 574;
BA_ "SigType" SG_ 2364539395 TransShiftInProcess 4;
BA_ "SPN" SG_ 2364539395 TorqueConverterLockupEngaged 573;
BA_ "SigType" SG_ 2364539395 TorqueConverterLockupEngaged 4;
BA_ "SPN" SG_ 2364539395 TransDrivelineEngaged 560;
BA_ "SigType" SG_ 2364539395 TransDrivelineEngaged 4;
BA_ "SPN" SG_ 2566843904 EngIntercoolerThermostatOpening 1134;
BA_ "SigType" SG_ 2566843904 EngIntercoolerThermostatOpening 1;
BA_ "SPN" SG_ 2566843904 EngIntercoolerTemp 52;
BA_ "SigType" SG_ 2566843904 EngIntercoolerTemp 1;
BA_ "SPN" SG_ 2566843904 EngTurboOilTemp 176;
BA_ "SigType" SG_ 2566843904 EngTurboOilTemp 1;
BA_ "SPN" SG_ 2566843904 EngOilTemp1 175;
BA_ "SigType" SG_ 2566843904 EngOilTemp1 1;
BA_ "SPN" SG_ 2566843904 EngFuelTemp 174;
BA_ "SigType" SG_ 2566843904 EngFuelTemp 1;
BA_ "SPN" SG_ 2566843904 EngCoolantTemp 110;
BA_ "SigType" SG_ 2566843904 EngCoolantTemp 1;
BA_ "SPN" SG_ 2565865475 RetarderSelectionNonEng 1716;
BA_ "SigType" SG_ 2565865475 RetarderSelectionNonEng 1;
BA_ "SPN" SG_ 2565865475 ActlMxAvlblRtarderPercentTorque 1717;
BA_ "SigType" SG_ 2565865475 ActlMxAvlblRtarderPercentTorque 1;
BA_ "SPN" SG_ 2565865475 DrvrsDmandRetarderPercentTorque 1715;
BA_ "SigType" SG_ 2565865475 DrvrsDmandRetarderPercentTorque 1;
BA_ "SPN" SG_ 2565865475 SrcAddrssOfCtrllngDvcFrRtrdrCtrl 1480;
BA_ "SigType" SG_ 2565865475 SrcAddrssOfCtrllngDvcFrRtrdrCtrl 1;
BA_ "SPN" SG_ 2565865475 RetarderRqingBrakeLight 1667;
BA_ "SigType" SG_ 2565865475 RetarderRqingBrakeLight 4;
BA_ "SPN" SG_ 2565865475 EngCoolantLoadIncrease 1082;
BA_ "SigType" SG_ 2565865475 EngCoolantLoadIncrease 4;
BA_ "SPN" SG_ 2565865475 IntendedRetarderPercentTorque 1085;
BA_ "SigType" SG_ 2565865475 IntendedRetarderPercentTorque 1;
BA_ "SPN" SG_ 2565865475 ActualRetarderPercentTorque 520;
BA_ "SigType" SG_ 2565865475 ActualRetarderPercentTorque 1;
BA_ "SPN" SG_ 2565865475 RetarderEnableShiftAssistSwitch 572;
BA_ "SigType" SG_ 2565865475 RetarderEnableShiftAssistSwitch 4;
BA_ "SPN" SG_ 2565865475 RetarderEnableBrakeAssistSwitch 571;
BA_ "SigType" SG_ 2565865475 RetarderEnableBrakeAssistSwitch 4;
BA_ "SPN" SG_ 2565865475 RetarderTorqueMode 900;
BA_ "SigType" SG_ 2565865475 RetarderTorqueMode 4;
BA_ "SPN" SG_ 2566844414 EngCoolantLevel 111;
BA_ "SigType" SG_ 2566844414 EngCoolantLevel 1;
BA_ "SPN" SG_ 2566844414 EngCoolantPress 109;
BA_ "SigType" SG_ 2566844414 EngCoolantPress 1;
BA_ "SPN" SG_ 2566844414 EngCrankcasePress 101;
BA_ "SigType" SG_ 2566844414 EngCrankcasePress 1;
BA_ "SPN" SG_ 2566844414 EngOilPress 100;
BA_ "SigType" SG_ 2566844414 EngOilPress 1;
BA_ "SPN" SG_ 2566844414 EngOilLevel 98;
BA_ "SigType" SG_ 2566844414 EngOilLevel 1;
BA_ "SPN" SG_ 2566844414 EngExCrankcaseBlowbyPress 22;
BA_ "SigType" SG_ 2566844414 EngExCrankcaseBlowbyPress 1;
BA_ "SPN" SG_ 2566844414 EngFuelDeliveryPress 94;
BA_ "SigType" SG_ 2566844414 EngFuelDeliveryPress 1;
BA_ "SPN" SG_ 2566840064 EstEngPrsticLossesPercentTorque 2978;
BA_ "SigType" SG_ 2566840064 EstEngPrsticLossesPercentTorque 1;
BA_ "SPN" SG_ 2566840064 EngsDsrdOprtngSpdAsymmtryAdjstmn 519;
BA_ "SigType" SG_ 2566840064 EngsDsrdOprtngSpdAsymmtryAdjstmn 1;
BA_ "SPN" SG_ 2566840064 EngsDesiredOperatingSpeed 515;
BA_ "SigType" SG_ 2566840064 EngsDesiredOperatingSpeed 1;
BA_ "SPN" SG_ 2566840064 NominalFrictionPercentTorque 514;
BA_ "SigType" SG_ 2566840064 NominalFrictionPercentTorque 1;
BA_ "SPN" SG_ 2364539648 EngPercentLoadAtCurrentSpeed 92;
BA_ "SigType" SG_ 2364539648 EngPercentLoadAtCurrentSpeed 1;
BA_ "SPN" SG_ 2364539648 AccelPedal2LowIdleSwitch 2970;
BA_ "SigType" SG_ 2364539648 AccelPedal2LowIdleSwitch 4;
BA_ "SPN" SG_ 2364539648 RoadSpeedLimitStatus 1437;
BA_ "SigType" SG_ 2364539648 RoadSpeedLimitStatus 4;
BA_ "SPN" SG_ 2364539648 AccelPedalKickdownSwitch 559;
BA_ "SigType" SG_ 2364539648 AccelPedalKickdownSwitch 4;
BA_ "SPN" SG_ 2364539648 AccelPedal1LowIdleSwitch 558;
BA_ "SigType" SG_ 2364539648 AccelPedal1LowIdleSwitch 4;
BA_ "SPN" SG_ 2364539648 AccelPedalPos1 91;
BA_ "SigType" SG_ 2364539648 AccelPedalPos1 1;
BA_ "SPN" SG_ 2364539904 EngDemandPercentTorque 2432;
BA_ "SigType" SG_ 2364539904 EngDemandPercentTorque 1;
BA_ "SPN" SG_ 2364539904 EngStarterMode 1675;
BA_ "SigType" SG_ 2364539904 EngStarterMode 4;
BA_ "SPN" SG_ 2364539904 SrcAddrssOfCtrllngDvcForEngCtrl 1483;
BA_ "SigType" SG_ 2364539904 SrcAddrssOfCtrllngDvcForEngCtrl 1;
BA_ "SPN" SG_ 2364539904 EngSpeed 190;
BA_ "SigType" SG_ 2364539904 EngSpeed 1;
BA_ "SPN" SG_ 2364539904 ActualEngPercentTorque 513;
BA_ "SigType" SG_ 2364539904 ActualEngPercentTorque 1;
BA_ "SPN" SG_ 2364539904 DriversDemandEngPercentTorque 512;
BA_ "SigType" SG_ 2364539904 DriversDemandEngPercentTorque 1;
BA_ "SPN" SG_ 2364539904 EngTorqueMode0 899;
BA_ "SigType" SG_ 2364539904 EngTorqueMode0 4;
BA_ "SPN" SG_ 2364539904 ActualEnginePercentTorqueHiRes 4154;
BA_ "SigType" SG_ 2364539904 ActualEnginePercentTorqueHiRes 1;
BA_ "SPN" SG_ 2566841342 SupportTSC1CtrlPurposeGroup4Of4 3348;
BA_ "SigType" SG_ 2566841342 SupportTSC1CtrlPurposeGroup4Of4 1;
BA_ "SPN" SG_ 2566841342 SupportVariableRateTSC1Message 3344;
BA_ "SigType" SG_ 2566841342 SupportVariableRateTSC1Message 1;
BA_ "SPN" SG_ 2566841342 SupportTSC1CtrlPurposeGroup3Of4 3347;
BA_ "SigType" SG_ 2566841342 SupportTSC1CtrlPurposeGroup3Of4 1;
BA_ "SPN" SG_ 2566841342 SupportTSC1CtrlPurposeGroup2Of4 3346;
BA_ "SigType" SG_ 2566841342 SupportTSC1CtrlPurposeGroup2Of4 1;
BA_ "SPN" SG_ 2566841342 SupportTSC1CtrlPurposeGroup1Of4 3345;
BA_ "SigType" SG_ 2566841342 SupportTSC1CtrlPurposeGroup1Of4 1;
BA_ "SPN" SG_ 2566841342 EngDefaultTorqueLimit 1846;
BA_ "SigType" SG_ 2566841342 EngDefaultTorqueLimit 1;
BA_ "SPN" SG_ 2566841342 EngMomentOfInertia 1794;
BA_ "SigType" SG_ 2566841342 EngMomentOfInertia 1;
BA_ "SPN" SG_ 2566841342 EngExRngRqdSpdCtrlRngUpperLimit 1712;
BA_ "SigType" SG_ 2566841342 EngExRngRqdSpdCtrlRngUpperLimit 1;
BA_ "SPN" SG_ 2566841342 EngRqdTorqueCtrlRangeUpperLimit 538;
BA_ "SigType" SG_ 2566841342 EngRqdTorqueCtrlRangeUpperLimit 1;
BA_ "SPN" SG_ 2566841342 EngRqdTorqueCtrlRangeLowerLimit 537;
BA_ "SigType" SG_ 2566841342 EngRqdTorqueCtrlRangeLowerLimit 1;
BA_ "SPN" SG_ 2566841342 EngRqedSpeedCtrlRangeUpperLimit 536;
BA_ "SigType" SG_ 2566841342 EngRqedSpeedCtrlRangeUpperLimit 1;
BA_ "SPN" SG_ 2566841342 EngRqedSpeedCtrlRangeLowerLimit 535;
BA_ "SigType" SG_ 2566841342 EngRqedSpeedCtrlRangeLowerLimit 1;
BA_ "SPN" SG_ 2566841342 EngMxMomentaryOverrideTimeLimit 534;
BA_ "SigType" SG_ 2566841342 EngMxMomentaryOverrideTimeLimit 1;
BA_ "SPN" SG_ 2566841342 EngMxMmntaryOverrideSpeedPoint7 533;
BA_ "SigType" SG_ 2566841342 EngMxMmntaryOverrideSpeedPoint7 1;
BA_ "SPN" SG_ 2566841342 EngReferenceTorque 544;
BA_ "SigType" SG_ 2566841342 EngReferenceTorque 1;
BA_ "SPN" SG_ 2566841342 EngSpeedAtHighIdlePoint6 532;
BA_ "SigType" SG_ 2566841342 EngSpeedAtHighIdlePoint6 1;
BA_ "SPN" SG_ 2566841342 EngGainOfEndspeedGovernor 545;
BA_ "SigType" SG_ 2566841342 EngGainOfEndspeedGovernor 1;
BA_ "SPN" SG_ 2566841342 EngPercentTorqueAtPoint5 543;
BA_ "SigType" SG_ 2566841342 EngPercentTorqueAtPoint5 1;
BA_ "SPN" SG_ 2566841342 EngSpeedAtPoint5 531;
BA_ "SigType" SG_ 2566841342 EngSpeedAtPoint5 1;
BA_ "SPN" SG_ 2566841342 EngPercentTorqueAtPoint4 542;
BA_ "SigType" SG_ 2566841342 EngPercentTorqueAtPoint4 1;
BA_ "SPN" SG_ 2566841342 EngSpeedAtPoint4 530;
BA_ "SigType" SG_ 2566841342 EngSpeedAtPoint4 1;
BA_ "SPN" SG_ 2566841342 EngPercentTorqueAtPoint3 541;
BA_ "SigType" SG_ 2566841342 EngPercentTorqueAtPoint3 1;
BA_ "SPN" SG_ 2566841342 EngSpeedAtPoint3 529;
BA_ "SigType" SG_ 2566841342 EngSpeedAtPoint3 1;
BA_ "SPN" SG_ 2566841342 EngPercentTorqueAtPoint2 540;
BA_ "SigType" SG_ 2566841342 EngPercentTorqueAtPoint2 1;
BA_ "SPN" SG_ 2566841342 EngSpeedAtPoint2 528;
BA_ "SigType" SG_ 2566841342 EngSpeedAtPoint2 1;
BA_ "SPN" SG_ 2566841342 EngPercentTorqueAtIdlePoint1 539;
BA_ "SigType" SG_ 2566841342 EngPercentTorqueAtIdlePoint1 1;
BA_ "SPN" SG_ 2566841342 EngSpeedAtIdlePoint1 188;
BA_ "SigType" SG_ 2566841342 EngSpeedAtIdlePoint1 1;
BA_ "SPN" SG_ 2566767870 BrakeTempWarning 3839;
BA_ "SigType" SG_ 2566767870 BrakeTempWarning 4;
BA_ "SPN" SG_ 2566767870 XBRAccelerationLimit 2921;
BA_ "SigType" SG_ 2566767870 XBRAccelerationLimit 1;
BA_ "SPN" SG_ 2566767870 XBRActiveCtrlMode 2918;
BA_ "SigType" SG_ 2566767870 XBRActiveCtrlMode 4;
BA_ "SPN" SG_ 2566767870 XBRSystemState 2917;
BA_ "SigType" SG_ 2566767870 XBRSystemState 4;
BA_ "SPN" SG_ 2566767870 FoundationBrakeUse 2919;
BA_ "SigType" SG_ 2566767870 FoundationBrakeUse 4;
BA_ "SPN" SG_ 2566767870 HillHolderMode 2912;
BA_ "SigType" SG_ 2566767870 HillHolderMode 4;
BA_ "SPN" SG_ 2566767870 HaltBrakeMode 2913;
BA_ "SigType" SG_ 2566767870 HaltBrakeMode 4;
BA_ "SPN" SG_ 2566827518 BrkAppPrssHghRngRrAxl3RghtWheel 1098;
BA_ "SigType" SG_ 2566827518 BrkAppPrssHghRngRrAxl3RghtWheel 1;
BA_ "SPN" SG_ 2566827518 BrkAppPrssHghRngRrAxl3LeftWheel 1097;
BA_ "SigType" SG_ 2566827518 BrkAppPrssHghRngRrAxl3LeftWheel 1;
BA_ "SPN" SG_ 2566827518 BrkAppPrssHghRngRrAxl2RghtWheel 1096;
BA_ "SigType" SG_ 2566827518 BrkAppPrssHghRngRrAxl2RghtWheel 1;
BA_ "SPN" SG_ 2566827518 BrkAppPrssHghRngRrAxl2LeftWheel 1095;
BA_ "SigType" SG_ 2566827518 BrkAppPrssHghRngRrAxl2LeftWheel 1;
BA_ "SPN" SG_ 2566827518 BrkAppPrssHghRngRrAxl1RghtWheel 1094;
BA_ "SigType" SG_ 2566827518 BrkAppPrssHghRngRrAxl1RghtWheel 1;
BA_ "SPN" SG_ 2566827518 BrkAppPrssHghRngRrAxl1LeftWheel 1093;
BA_ "SigType" SG_ 2566827518 BrkAppPrssHghRngRrAxl1LeftWheel 1;
BA_ "SPN" SG_ 2566827518 BrkAppPrssHghRngFrntAxlRghtWhel 1092;
BA_ "SigType" SG_ 2566827518 BrkAppPrssHghRngFrntAxlRghtWhel 1;
BA_ "SPN" SG_ 2566827518 BrkAppPrssHghRngFrntAxlLftWheel 1091;
BA_ "SigType" SG_ 2566827518 BrkAppPrssHghRngFrntAxlLftWheel 1;
BA_ "SPN" SG_ 2566832126 RlativeSpeedRearAxle2RightWheel 910;
BA_ "SigType" SG_ 2566832126 RlativeSpeedRearAxle2RightWheel 1;
BA_ "SPN" SG_ 2566832126 RelativeSpeedRearAxle2LeftWheel 909;
BA_ "SigType" SG_ 2566832126 RelativeSpeedRearAxle2LeftWheel 1;
BA_ "SPN" SG_ 2566832126 RlativeSpeedRearAxle1RightWheel 908;
BA_ "SigType" SG_ 2566832126 RlativeSpeedRearAxle1RightWheel 1;
BA_ "SPN" SG_ 2566832126 RelativeSpeedRearAxle1LeftWheel 907;
BA_ "SigType" SG_ 2566832126 RelativeSpeedRearAxle1LeftWheel 1;
BA_ "SPN" SG_ 2566832126 RlativeSpeedFrontAxleRightWheel 906;
BA_ "SigType" SG_ 2566832126 RlativeSpeedFrontAxleRightWheel 1;
BA_ "SPN" SG_ 2566832126 RelativeSpeedFrontAxleLeftWheel 905;
BA_ "SigType" SG_ 2566832126 RelativeSpeedFrontAxleLeftWheel 1;
BA_ "SPN" SG_ 2566832126 FrontAxleSpeed 904;
BA_ "SigType" SG_ 2566832126 FrontAxleSpeed 1;
BA_ "SPN" SG_ 2565865982 SrcAddrssOfCtrllngDvcFrBrkCntrl 1481;
BA_ "SigType" SG_ 2565865982 SrcAddrssOfCtrllngDvcFrBrkCntrl 1;
BA_ "SPN" SG_ 2565865982 BrakePedalPos 521;
BA_ "SigType" SG_ 2565865982 BrakePedalPos 1;
BA_ "SPN" SG_ 2565865982 TrctrMntdTrilerABSWarningSignal 1792;
BA_ "SigType" SG_ 2565865982 TrctrMntdTrilerABSWarningSignal 4;
BA_ "SPN" SG_ 2565865982 TrailerABSStatus 1836;
BA_ "SigType" SG_ 2565865982 TrailerABSStatus 4;
BA_ "SPN" SG_ 2565865982 HaltBrakeSwitch 2911;
BA_ "SigType" SG_ 2565865982 HaltBrakeSwitch 4;
BA_ "SPN" SG_ 2565865982 ATC_ASRInformationSignal 1793;
BA_ "SigType" SG_ 2565865982 ATC_ASRInformationSignal 4;
BA_ "SPN" SG_ 2565865982 ABS_EBSAmberWarningSignal 1438;
BA_ "SigType" SG_ 2565865982 ABS_EBSAmberWarningSignal 4;
BA_ "SPN" SG_ 2565865982 EBSRedWarningSignal 1439;
BA_ "SigType" SG_ 2565865982 EBSRedWarningSignal 4;
BA_ "SPN" SG_ 2565865982 ABSFullyOperational 1243;
BA_ "SigType" SG_ 2565865982 ABSFullyOperational 4;
BA_ "SPN" SG_ 2565865982 EngRetarderSelection 973;
BA_ "SigType" SG_ 2565865982 EngRetarderSelection 1;
BA_ "SPN" SG_ 2565865982 RemoteAccelEnableSwitch 969;
BA_ "SigType" SG_ 2565865982 RemoteAccelEnableSwitch 4;
BA_ "SPN" SG_ 2565865982 EngAuxEngShutdownSwitch 970;
BA_ "SigType" SG_ 2565865982 EngAuxEngShutdownSwitch 4;
BA_ "SPN" SG_ 2565865982 EngDerateSwitch 971;
BA_ "SigType" SG_ 2565865982 EngDerateSwitch 4;
BA_ "SPN" SG_ 2565865982 AccelInterlockSwitch 972;
BA_ "SigType" SG_ 2565865982 AccelInterlockSwitch 4;
BA_ "SPN" SG_ 2565865982 TractionCtrlOverrideSwitch 1238;
BA_ "SigType" SG_ 2565865982 TractionCtrlOverrideSwitch 4;
BA_ "SPN" SG_ 2565865982 ASRHillHolderSwitch 577;
BA_ "SigType" SG_ 2565865982 ASRHillHolderSwitch 4;
BA_ "SPN" SG_ 2565865982 ASROffroadSwitch 576;
BA_ "SigType" SG_ 2565865982 ASROffroadSwitch 4;
BA_ "SPN" SG_ 2565865982 ABSOffroadSwitch 575;
BA_ "SigType" SG_ 2565865982 ABSOffroadSwitch 4;
BA_ "SPN" SG_ 2565865982 EBSBrakeSwitch 1121;
BA_ "SigType" SG_ 2565865982 EBSBrakeSwitch 4;
BA_ "SPN" SG_ 2565865982 AntiLockBrakingActive 563;
BA_ "SigType" SG_ 2565865982 AntiLockBrakingActive 4;
BA_ "SPN" SG_ 2565865982 ASRBrakeCtrlActive 562;
BA_ "SigType" SG_ 2565865982 ASRBrakeCtrlActive 4;
BA_ "SPN" SG_ 2565865982 ASREngCtrlActive 561;
BA_ "SigType" SG_ 2565865982 ASREngCtrlActive 4;
BA_ "SPN" SG_ 2566847742 CargoAmbientTemp 169;
BA_ "SigType" SG_ 2566847742 CargoAmbientTemp 1;
BA_ "SPN" SG_ 2566847742 EngOilFilterDiffPress 99;
BA_ "SigType" SG_ 2566847742 EngOilFilterDiffPress 1;
BA_ "SPN" SG_ 2566847742 EngFuelFilterDiffPress 95;
BA_ "SigType" SG_ 2566847742 EngFuelFilterDiffPress 1;
BA_ "SPN" SG_ 2566847742 FuelLevel 96;
BA_ "SigType" SG_ 2566847742 FuelLevel 1;
BA_ "SPN" SG_ 2566847742 WasherFluidLevel 80;
BA_ "SigType" SG_ 2566847742 WasherFluidLevel 1;
BA_ "SPN" SG_ 2564872707 SelectedMaxVehicleSpeedLimit 2596;
BA_ "SigType" SG_ 2564872707 SelectedMaxVehicleSpeedLimit 1;
BA_ "SPN" SG_ 2564872707 RqCabZoneHeating 1686;
BA_ "SigType" SG_ 2564872707 RqCabZoneHeating 4;
BA_ "SPN" SG_ 2564872707 RqEngZoneHeating 1685;
BA_ "SigType" SG_ 2564872707 RqEngZoneHeating 4;
BA_ "SPN" SG_ 2564872707 AuxHeaterModeRq 1683;
BA_ "SigType" SG_ 2564872707 AuxHeaterModeRq 4;
BA_ "SPN" SG_ 2564872707 EngAutomaticStartEnableSwitch 1656;
BA_ "SigType" SG_ 2564872707 EngAutomaticStartEnableSwitch 4;
BA_ "SPN" SG_ 2564872707 AtmaticGearShiftingEnableSwitch 1666;
BA_ "SigType" SG_ 2564872707 AtmaticGearShiftingEnableSwitch 4;
BA_ "SPN" SG_ 2564872707 VhclLmtngSpdGvernorEnableSwitch 1653;
BA_ "SigType" SG_ 2564872707 VhclLmtngSpdGvernorEnableSwitch 4;
BA_ "SPN" SG_ 2564872707 VhclLmtngSpdGvrnrIncrmentSwitch 1654;
BA_ "SigType" SG_ 2564872707 VhclLmtngSpdGvrnrIncrmentSwitch 4;
BA_ "SPN" SG_ 2564872707 VhclLmtngSpdGvrnrDcrementSwitch 1655;
BA_ "SigType" SG_ 2564872707 VhclLmtngSpdGvrnrDcrementSwitch 4;
BA_ "SPN" SG_ 2564872707 SeatBeltSwitch 1856;
BA_ "SigType" SG_ 2564872707 SeatBeltSwitch 4;
BA_ "SPN" SG_ 2564872707 OperatorSeatDirectionSwitch 1714;
BA_ "SigType" SG_ 2564872707 OperatorSeatDirectionSwitch 4;
BA_ "SPN" SG_ 2564872707 BatteryMainSwitchHoldRq 1682;
BA_ "SigType" SG_ 2564872707 BatteryMainSwitchHoldRq 4;
BA_ "SPN" SG_ 2564872707 AuxHeaterCoolantPumpRq 1684;
BA_ "SigType" SG_ 2564872707 AuxHeaterCoolantPumpRq 4;
BA_ "SPN" SG_ 2564872707 CabInteriorTempCmd 1691;
BA_ "SigType" SG_ 2564872707 CabInteriorTempCmd 1;
BA_ "SPN" SG_ 2564872707 RqedPercentFanSpeed 986;
BA_ "SigType" SG_ 2564872707 RqedPercentFanSpeed 1;
BA_ "SPN" SG_ 2566843136 UnitNumber 233;
BA_ "SigType" SG_ 2566843136 UnitNumber 8;
BA_ "SPN" SG_ 2566843136 SerialNumber 588;
BA_ "SigType" SG_ 2566843136 SerialNumber 8;
BA_ "SPN" SG_ 2566843136 Model 587;
BA_ "SigType" SG_ 2566843136 Model 8;
BA_ "SPN" SG_ 2566844926 ParkBrakeReleaseInhibitRq 3807;
BA_ "SigType" SG_ 2566844926 ParkBrakeReleaseInhibitRq 4;
BA_ "SPN" SG_ 2566844926 EngShutdownOverrideSwitch 1237;
BA_ "SigType" SG_ 2566844926 EngShutdownOverrideSwitch 4;
BA_ "SPN" SG_ 2566844926 EngTestModeSwitch 966;
BA_ "SigType" SG_ 2566844926 EngTestModeSwitch 4;
BA_ "SPN" SG_ 2566844926 EngIdleDecrementSwitch 967;
BA_ "SigType" SG_ 2566844926 EngIdleDecrementSwitch 4;
BA_ "SPN" SG_ 2566844926 EngIdleIncrementSwitch 968;
BA_ "SigType" SG_ 2566844926 EngIdleIncrementSwitch 4;
BA_ "SPN" SG_ 2566844926 CruiseCtrlStates 527;
BA_ "SigType" SG_ 2566844926 CruiseCtrlStates 4;
BA_ "SPN" SG_ 2566844926 PtoGovernorState 976;
BA_ "SigType" SG_ 2566844926 PtoGovernorState 4;
BA_ "SPN" SG_ 2566844926 CruiseCtrlSetSpeed 86;
BA_ "SigType" SG_ 2566844926 CruiseCtrlSetSpeed 1;
BA_ "SPN" SG_ 2566844926 CruiseCtrlAccelerateSwitch 602;
BA_ "SigType" SG_ 2566844926 CruiseCtrlAccelerateSwitch 4;
BA_ "SPN" SG_ 2566844926 CruiseCtrlResumeSwitch 601;
BA_ "SigType" SG_ 2566844926 CruiseCtrlResumeSwitch 4;
BA_ "SPN" SG_ 2566844926 CruiseCtrlCoastSwitch 600;
BA_ "SigType" SG_ 2566844926 CruiseCtrlCoastSwitch 4;
BA_ "SPN" SG_ 2566844926 CruiseCtrlSetSwitch 599;
BA_ "SigType" SG_ 2566844926 CruiseCtrlSetSwitch 4;
BA_ "SPN" SG_ 2566844926 ClutchSwitch 598;
BA_ "SigType" SG_ 2566844926 ClutchSwitch 4;
BA_ "SPN" SG_ 2566844926 BrakeSwitch 597;
BA_ "SigType" SG_ 2566844926 BrakeSwitch 4;
BA_ "SPN" SG_ 2566844926 CruiseCtrlEnableSwitch 596;
BA_ "SigType" SG_ 2566844926 CruiseCtrlEnableSwitch 4;
BA_ "SPN" SG_ 2566844926 CruiseCtrlActive 595;
BA_ "SigType" SG_ 2566844926 CruiseCtrlActive 4;
BA_ "SPN" SG_ 2566844926 WheelBasedVehicleSpeed 84;
BA_ "SigType" SG_ 2566844926 WheelBasedVehicleSpeed 1;
BA_ "SPN" SG_ 2566844926 CruiseCtrlPauseSwitch 1633;
BA_ "SigType" SG_ 2566844926 CruiseCtrlPauseSwitch 4;
BA_ "SPN" SG_ 2566844926 ParkingBrakeSwitch 70;
BA_ "SigType" SG_ 2566844926 ParkingBrakeSwitch 4;
BA_ "SPN" SG_ 2566844926 TwoSpeedAxleSwitch 69;
BA_ "SigType" SG_ 2566844926 TwoSpeedAxleSwitch 4;
BA_ "SPN" SG_ 2566835710 FreezeFrameLength 1217;
BA_ "SPN" SG_ 2566835710 EngSpeed 190;
BA_ "SigType" SG_ 2566835710 EngSpeed 1;
BA_ "SPN" SG_ 2566835710 EngTorqueMode1 899;
BA_ "SigType" SG_ 2566835710 EngTorqueMode1 4;
BA_ "SPN" SG_ 2566835710 EngTurboBoostPress 102;
BA_ "SigType" SG_ 2566835710 EngTurboBoostPress 1;
BA_ "SPN" SG_ 2566835710 WheelBasedVehicleSpeed 84;
BA_ "SigType" SG_ 2566835710 WheelBasedVehicleSpeed 1;
BA_ "SPN" SG_ 2566835710 EngPercentLoadAtCurrentSpeed 92;
BA_ "SigType" SG_ 2566835710 EngPercentLoadAtCurrentSpeed 1;
BA_ "SPN" SG_ 2566835710 EngineCoolantTemperature 110;
BA_ "SigType" SG_ 2566835710 EngineCoolantTemperature 1;
BA_ "SPN" SG_ 2566834944 MalfunctionIndicatorLampStatus 1213;
BA_ "SigType" SG_ 2566834944 MalfunctionIndicatorLampStatus 4;
BA_ "SPN" SG_ 2566834944 RedStopLampState 623;
BA_ "SigType" SG_ 2566834944 RedStopLampState 4;
BA_ "SPN" SG_ 2566834944 AmberWarningLampStatus 624;
BA_ "SigType" SG_ 2566834944 AmberWarningLampStatus 4;
BA_ "SPN" SG_ 2566834944 ProtectLampStatus 987;
BA_ "SigType" SG_ 2566834944 ProtectLampStatus 4;
BA_ "SPN" SG_ 2566834944 FlashRedStopLamp 3039;
BA_ "SPN" SG_ 2566834944 FlashProtectLamp 3041;
BA_ "SPN" SG_ 2566834944 FlashMalfuncIndicatorLamp 3038;
BA_ "SigType" SG_ 2566834944 FlashMalfuncIndicatorLamp 4;
BA_ "SPN" SG_ 2566834944 FlashAmberWarningLamp 3040;
BA_ "SPN" SG_ 2564816638 HoldSignal 1236;
BA_ "SigType" SG_ 2564816638 HoldSignal 4;
BA_ "SPN" SG_ 2564816638 J1939Network3 1235;
BA_ "SigType" SG_ 2564816638 J1939Network3 4;
BA_ "SPN" SG_ 2564816638 J1939Network2 1231;
BA_ "SigType" SG_ 2564816638 J1939Network2 4;
BA_ "SPN" SG_ 2564816638 ISO9141 1232;
BA_ "SigType" SG_ 2564816638 ISO9141 4;
BA_ "SPN" SG_ 2564816638 SAE_J1850 1233;
BA_ "SigType" SG_ 2564816638 SAE_J1850 4;
BA_ "SPN" SG_ 2564816638 ManufacturerSpecificPort 1234;
BA_ "SigType" SG_ 2564816638 ManufacturerSpecificPort 4;
BA_ "SPN" SG_ 2564816638 CurrentDataLink 1230;
BA_ "SigType" SG_ 2564816638 CurrentDataLink 4;
BA_ "SPN" SG_ 2564816638 SAE_J1587 608;
BA_ "SigType" SG_ 2564816638 SAE_J1587 4;
BA_ "SPN" SG_ 2564816638 SAE_J1922 622;
BA_ "SigType" SG_ 2564816638 SAE_J1922 4;
BA_ "SPN" SG_ 2564816638 J1939Network1 639;
BA_ "SigType" SG_ 2564816638 J1939Network1 4;
BA_ "SPN" SG_ 2564816638 SuspendSignal 2618;
BA_ "SPN" SG_ 2564816638 SuspendDuration 2619;
BA_ "SigType" SG_ 2565799678 ManufacturerCode 1;
BA_ "SigType" SG_ 2565799678 IndustryGroup 4;
BA_ "SPN" SG_ 2565603070 SequenceNumber 2572;
BA_ "SigType" SG_ 2565603070 SequenceNumber 1;
BA_ "SPN" SG_ 2565668606 TotalNumberOfPacketsEoMA 2558;
BA_ "SigType" SG_ 2565668606 TotalNumberOfPacketsEoMA 1;
BA_ "SPN" SG_ 2565668606 TotalMessageSizeEoMA 2557;
BA_ "SigType" SG_ 2565668606 TotalMessageSizeEoMA 1;
BA_ "SPN" SG_ 2565668606 TotalMessageSizeBAM 2557;
BA_ "SigType" SG_ 2565668606 TotalMessageSizeBAM 1;
BA_ "SPN" SG_ 2565668606 TotalNumberOfPacketsBAM 2558;
BA_ "SigType" SG_ 2565668606 TotalNumberOfPacketsBAM 1;
BA_ "SPN" SG_ 2565668606 ConnectionAbortReason 2570;
BA_ "SigType" SG_ 2565668606 ConnectionAbortReason 1;
BA_ "SPN" SG_ 2565668606 NextPacketNumberToBeSent 2562;
BA_ "SigType" SG_ 2565668606 NextPacketNumberToBeSent 1;
BA_ "SPN" SG_ 2565668606 NumberOfPacketsThatCanBeSent 2561;
BA_ "SigType" SG_ 2565668606 NumberOfPacketsThatCanBeSent 1;
BA_ "SPN" SG_ 2565668606 PGNumber 2560;
BA_ "SPN" SG_ 2565668606 MaximumNumberOfPackets 2559;
BA_ "SigType" SG_ 2565668606 MaximumNumberOfPackets 1;
BA_ "SPN" SG_ 2565668606 TotalNumberOfPackets 2558;
BA_ "SigType" SG_ 2565668606 TotalNumberOfPackets 1;
BA_ "SPN" SG_ 2565668606 TotalMessageSize 2557;
BA_ "SigType" SG_ 2565668606 TotalMessageSize 1;
BA_ "SPN" SG_ 2565668606 ControlByte 2556;
BA_ "SPN" SG_ 2565472505 ParameterGroupNumber 2574;
BA_ "SigType" SG_ 2565472505 ParameterGroupNumber 1;
BA_ "SPN" SG_ 2566838561 AuxIoChannel2 1084;
BA_ "SigType" SG_ 2566838561 AuxIoChannel2 1;
BA_ "SPN" SG_ 2566838561 AuxIoChannel1 1083;
BA_ "SigType" SG_ 2566838561 AuxIoChannel1 1;
BA_ "SPN" SG_ 2566845696 RoadSurfaceTemp 79;
BA_ "SigType" SG_ 2566845696 RoadSurfaceTemp 1;
BA_ "SPN" SG_ 2566845696 EngAirInletTemp 172;
BA_ "SigType" SG_ 2566845696 EngAirInletTemp 1;
BA_ "SPN" SG_ 2566845696 AmbientAirTemp 171;
BA_ "SigType" SG_ 2566845696 AmbientAirTemp 1;
BA_ "SPN" SG_ 2566845696 CabInteriorTemp 170;
BA_ "SigType" SG_ 2566845696 CabInteriorTemp 1;
BA_ "SPN" SG_ 2566845696 BarometricPress 108;
BA_ "SigType" SG_ 2566845696 BarometricPress 1;
BA_ "SPN" SG_ 2432593918 ACCDistanceAlertSignal 1796;
BA_ "SigType" SG_ 2432593918 ACCDistanceAlertSignal 4;
BA_ "SPN" SG_ 2432593918 ACCSystemShutoffWarning 1797;
BA_ "SigType" SG_ 2432593918 ACCSystemShutoffWarning 4;
BA_ "SPN" SG_ 2432593918 ACCTargetDetected 1798;
BA_ "SigType" SG_ 2432593918 ACCTargetDetected 4;
BA_ "SPN" SG_ 2432593918 RoadCurvature 1591;
BA_ "SigType" SG_ 2432593918 RoadCurvature 1;
BA_ "SPN" SG_ 2432593918 AdptveCruiseCtrlSetDistanceMode 1589;
BA_ "SigType" SG_ 2432593918 AdptveCruiseCtrlSetDistanceMode 4;
BA_ "SPN" SG_ 2432593918 AdaptiveCruiseCtrlMode 1590;
BA_ "SigType" SG_ 2432593918 AdaptiveCruiseCtrlMode 4;
BA_ "SPN" SG_ 2432593918 AdaptiveCruiseCtrlSetSpeed 1588;
BA_ "SigType" SG_ 2432593918 AdaptiveCruiseCtrlSetSpeed 1;
BA_ "SPN" SG_ 2432593918 DistanceToForwardVehicle 1587;
BA_ "SigType" SG_ 2432593918 DistanceToForwardVehicle 1;
BA_ "SPN" SG_ 2432593918 SpeedOfForwardVehicle 1586;
BA_ "SigType" SG_ 2432593918 SpeedOfForwardVehicle 1;
BA_ "SPN" SG_ 2565406462 AckNack 2541;
BA_ "SPN" SG_ 2565406462 ParameterGroupNumber 2574;
BA_ "SigType" SG_ 2565406462 ParameterGroupNumber 1;
BA_ "SPN" SG_ 2565406462 GroupFunctionValue 2542;
BA_ "SigType" SG_ 2565406462 GroupFunctionValue 1;
BA_ "SPN" SG_ 2566846467 TransOilLevelMeasurementStatus 3026;
BA_ "SigType" SG_ 2566846467 TransOilLevelMeasurementStatus 4;
BA_ "SPN" SG_ 2566846467 TransOilLevelCountdownTimer 3028;
BA_ "SigType" SG_ 2566846467 TransOilLevelCountdownTimer 4;
BA_ "SPN" SG_ 2566846467 TransOilLevelHigh_Low 3027;
BA_ "SigType" SG_ 2566846467 TransOilLevelHigh_Low 1;
BA_ "SPN" SG_ 2566846467 TransOilTemp 177;
BA_ "SigType" SG_ 2566846467 TransOilTemp 1;
BA_ "SPN" SG_ 2566846467 TransOilPress 127;
BA_ "SigType" SG_ 2566846467 TransOilPress 1;
BA_ "SPN" SG_ 2566846467 TransFilterDiffPress 126;
BA_ "SigType" SG_ 2566846467 TransFilterDiffPress 1;
BA_ "SPN" SG_ 2566846467 TransOilLevel 124;
BA_ "SigType" SG_ 2566846467 TransOilLevel 1;
BA_ "SPN" SG_ 2566846467 ClutchPress 123;
BA_ "SigType" SG_ 2566846467 ClutchPress 1;
BA_ "SPN" SG_ 2566846208 KeyswitchBatteryPotential 158;
BA_ "SigType" SG_ 2566846208 KeyswitchBatteryPotential 1;
BA_ "SPN" SG_ 2566846208 BatteryPotential 168;
BA_ "SigType" SG_ 2566846208 BatteryPotential 1;
BA_ "SPN" SG_ 2566846208 ChargingSystemPotential 167;
BA_ "SigType" SG_ 2566846208 ChargingSystemPotential 1;
BA_ "SPN" SG_ 2566846208 AltCurrent 115;
BA_ "SigType" SG_ 2566846208 AltCurrent 1;
BA_ "SPN" SG_ 2566846208 NetBatteryCurrent 114;
BA_ "SigType" SG_ 2566846208 NetBatteryCurrent 1;
VAL_ 3221225472 OperatorPTOMemorySelectSwitch 3 "notAvailable" 2 "error" 1 "PTOSetSpeedMemory2Selected" 0 "PTOSetSpeedMemory1Selected" ;
VAL_ 3221225472 EngPTOAccelerateSwitch 3 "NotAvailable" 2 "Error" 1 "On" 0 "Off" ;
VAL_ 3221225472 EngPTOResumeSwitch 3 "NotAvailable" 2 "Error" 1 "On" 0 "Off" ;
VAL_ 3221225472 EngPTOCoast_DecelerateSwitch 3 "NotAvailable" 2 "Error" 1 "On" 0 "Off" ;
VAL_ 3221225472 EngRmtPTOVriableSpeedCtrlSwitch 3 "NotAvailable" 2 "Error" 1 "On" 0 "Off" ;
VAL_ 3221225472 EngRmtPTOPrprgrmmdSpdCtrlSwitch 3 "NotAvailable" 2 "Error" 1 "On" 0 "Off" ;
VAL_ 3221225472 RmtPTOPrprgrmmdSpeedCtrlSwitch2 3 "NotAvailable" 2 "Error" 1 "On" 0 "Off" ;
VAL_ 3221225472 AuxInputIgnoreSwitch 3 "NotAvailable" 2 "Error" 1 "On" 0 "Off" ;
VAL_ 2364538622 ShutDownOverride 3 "not available" 2 "error" 1 "on" 0 "off" ;
VAL_ 2364538622 EngineStart 3 "not available" 2 "error" 1 "on" 0 "off" ;
VAL_ 2364538622 InhibitFuelInjection 3 "not available" 2 "error" 1 "on" 0 "off" ;
VAL_ 2364538622 InhibitEngineStart 3 "not available" 2 "error" 1 "on" 0 "off" ;
VAL_ 2365534851 Pushbutton2 3 "not available" 2 "error" 1 "on" 0 "off" ;
VAL_ 2365534851 Pushbutton1 3 "not available" 2 "error" 1 "on" 0 "off" ;
VAL_ 2566851796 Source 3 "not available" 2 "error" 1 "on" 0 "off" ;
VAL_ 2566851796 VoltageOk 3 "not available" 2 "error" 1 "on" 0 "off" ;
VAL_ 2365524950 Running 3 "not available" 2 "error" 1 "on" 0 "off" ;
VAL_ 2365524950 Warmup 3 "not available" 2 "error" 1 "on" 0 "off" ;
VAL_ 2365524950 UnderLocalControl 3 "not available" 2 "error" 1 "on" 0 "off" ;
VAL_ 2566850774 ShiftInhibit 3 "not available" 2 "error" 1 "on" 0 "off" ;
VAL_ 2566850260 OilTemperatureOk 3 "not available" 2 "error" 1 "on" 0 "off" ;
VAL_ 2566850260 OilPressureOk 3 "not available" 2 "error" 1 "on" 0 "off" ;
VAL_ 2566850260 PowerPresent 3 "not available" 2 "error" 1 "on" 0 "off" ;
VAL_ 2566850004 OilTemperatureOk 3 "not available" 2 "error" 1 "on" 0 "off" ;
VAL_ 2566850004 OilPressureOk 3 "not available" 2 "error" 1 "on" 0 "off" ;
VAL_ 2566850004 PowerPresent 3 "not available" 2 "error" 1 "on" 0 "off" ;
VAL_ 2365522128 CautionPresent 3 "not available" 2 "error" 1 "on" 0 "off" ;
VAL_ 2566834688 MalfunctionIndicatorLampStatus 3 "Not available" 2 "Reserved" 1 "Lamp on" 0 "Lamp off" ;
VAL_ 2566834688 RedStopLampState 3 "Not available" 2 "Reserved" 1 "Lamp on" 0 "Lamp off" ;
VAL_ 2566834688 AmberWarningLampStatus 3 "Not available" 2 "Reserved" 1 "Lamp on" 0 "Lamp off" ;
VAL_ 2566834688 ProtectLampStatus 3 "Not available" 2 "Reserved" 1 "Lamp on" 0 "Lamp off" ;
VAL_ 2566834688 FlashRedStopLamp 3 "Unavailable / Do Not Flash" 2 "Reserved" 1 "Fast Flash" 0 "Slow Flash" ;
VAL_ 2566834688 FlashProtectLamp 3 "Unavailable / Do Not Flash" 2 "Reserved" 1 "Fast Flash" 0 "Slow Flash" ;
VAL_ 2566834688 FlashMalfuncIndicatorLamp 3 "Unavailable / Do Not Flash" 2 "Reserved" 1 "Fast Flash" 0 "Slow Flash" ;
VAL_ 2566834688 FlashAmberWarningLamp 3 "Unavailable / Do Not Flash" 2 "Reserved" 1 "Fast Flash" 0 "Slow Flash" ;
VAL_ 2564545057 BrandImMotorraum 3 "not available" 2 "error" 1 "on" 0 "off" ;
VAL_ 2564545057 Klimakompressor 3 "not available" 2 "error" 1 "on" 0 "off" ;
VAL_ 2564497626 Fehler_FY92 3 "not available" 2 "error" 1 "on" 0 "off" ;
VAL_ 2564497626 Fehler_FY91 3 "not available" 2 "error" 1 "on" 0 "off" ;
VAL_ 2564497626 Fehler_FB6 3 "not available" 2 "error" 1 "on" 0 "off" ;
VAL_ 2564497626 Fehler_FB1 3 "not available" 2 "error" 1 "on" 0 "off" ;
VAL_ 2348810243 ControlPurpose 5 "TemporaryPowerTrainControl" 4 "EngineProtection" 3 "RoadSpeedGovernor" 2 "PTOGovernor" 1 "CruiseControl" 0 "AcceleratorPedal" ;
VAL_ 2348810243 TransmissionRate 7 "UseStandardRate" 6 "25ms" 5 "50ms" 4 "100ms" 3 "250ms" 2 "500ms" 1 "750ms" 0 "1000ms" ;
VAL_ 2348810243 OverrideCtrlModePriority 3 "LowPriority" 2 "MdmPrrtyUsdFrPwrtrnCtrlOprtnsWh" 1 "HighPriority" 0 "HghstPrrtyUsdFrSttnsThtRqrImmdt" ;
VAL_ 2348810243 EngRqedSpeedCtrlConditions 2 "ThsCtrlCndtnHsBnOptmzdTMnmzRpmO" 3 "StbltyOptmzdFrDrvlnEnggdAnd_OrI" 1 "StbltyOptmzdFrDrvlnDsnggdAndNnl" 0 "ThsSpdGvrnrGnSlctnIsAdjstdTPrvd" ;
VAL_ 2348810243 EngOverrideCtrlMode 3 "Spd_TrqLmtCtrlLmtSpdAnd_OrTrqBs" 2 "TrqCtrlCntrlTrqTInclddDsrdTrqVl" 1 "SpdCtrlGvrnSpdTInclddDsrdSpdVle" 0 "OvrrdDsbldDsblAnyExstngCtrlCmdd" ;
VAL_ 2365484286 DirectionIndicator 3 "NotAvailable" 2 "Error" 1 "Reverse" 0 "Forward" ;
VAL_ 2365484286 TachographPerformance 3 "NotAvailable" 2 "Error" 1 "PerformanceAnalysis" 0 "NormalPerformance" ;
VAL_ 2365484286 HandlingInformation 3 "NotAvailable" 2 "Error" 1 "HandlingInformation" 0 "NoHandlingInformation" ;
VAL_ 2365484286 SystemEvent 3 "NotAvailable" 2 "Error" 1 "TachographEvent" 0 "NoTachographEvent" ;
VAL_ 2365484286 DriverCardDriver2 3 "NotAvailable" 2 "Error" 1 "DriverCardPresent" 0 "DriverCardNotPresent" ;
VAL_ 2365484286 Driver2TimeRelatedStates 15 "NotAvailable" 14 "Error" 13 "Other" 7 "1100Reserved" 6 "Limit616HReached" 5 "Limit515MinBefore16H" 4 "Limit49HReached" 3 "Limit315MinBefore9H" 2 "Limit24HReached" 1 "Limit115MinBefore4H" 0 "Normal_NoLimitsReached" ;
VAL_ 2365484286 Overspeed 3 "NotAvailable" 2 "Error" 1 "Overspeed" 0 "NoOverspeed" ;
VAL_ 2365484286 DriverCardDriver1 3 "NotAvailable" 2 "Error" 1 "DriverCardPresent" 0 "DriverCardNotPresent" ;
VAL_ 2365484286 Driver1TimeRelatedStates 15 "NotAvailable" 14 "Error" 13 "Other" 7 "1100Reserved" 6 "Limit616HReached" 5 "Limit515MinBefore16H" 4 "Limit49HReached" 3 "Limit315MinBefore9H" 2 "Limit24HReached" 1 "Limit115MinBefore4H" 0 "Normal_NoLimitsReached" ;
VAL_ 2365484286 DriveRecognize 3 "NotAvailable" 2 "Error" 1 "VehicleMotionDetected" 0 "VehicleMotionNotDetected" ;
VAL_ 2365484286 Driver2WorkingState 7 "NotAvailable" 6 "Error" 4 "101Reserved" 3 "DriveBehindWheel" 2 "WrkLdngUnldingWorkingInAnOffice" 1 "DriverAvailableShortBreak" 0 "RestSleeping" ;
VAL_ 2365484286 Driver1WorkingState 7 "NotAvailable" 6 "Error" 4 "101Reserved" 3 "DriveBehindWheel" 2 "WrkLdngUnldingWorkingInAnOffice" 1 "DriverAvailableShortBreak" 0 "RestSleeping" ;
VAL_ 2348876577 TransMode8 3 "not available" 2 "error" 1 "on" 0 "off" ;
VAL_ 2348876577 TransMode7 3 "not available" 2 "error" 1 "on" 0 "off" ;
VAL_ 2348876577 TransMode6 3 "not available" 2 "error" 1 "on" 0 "off" ;
VAL_ 2348876577 TransMode5 3 "not available" 2 "error" 1 "on" 0 "off" ;
VAL_ 2348876577 TransReqLaunchGear 3 "not available" 2 "error" 1 "on" 0 "off" ;
VAL_ 2348876577 TransRevGearShfitInhibitRq 3 "not available" 2 "error" 1 "on" 0 "off" ;
VAL_ 2348876577 TrnsShftSlctorDisplayModeSwitch 3 "NotAvailable" 2 "Error" 1 "On" 0 "Off" ;
VAL_ 2348876577 TransMode4 3 "TakeNoAction" 2 "Reserved" 1 "Enable" 0 "Disable" ;
VAL_ 2348876577 TransMode3 3 "TakeNoAction" 2 "Reserved" 1 "Enable" 0 "Disable" ;
VAL_ 2348876577 TransMode2 3 "TakeNoAction" 2 "Reserved" 1 "Enable" 0 "Disable" ;
VAL_ 2348876577 TransMode1 3 "TakeNoAction" 2 "Reserved" 1 "Enable" 0 "Disable" ;
VAL_ 2348876577 DisengageDiffLockRqCentralRear 2 "Reserved" 3 "TakeNoAction" 1 "DisengageDiffLock" 0 "EngageDiffLock" ;
VAL_ 2348876577 DisengageDiffLockRqCentralFront 2 "Reserved" 3 "TakeNoAction" 1 "DisengageDiffLock" 0 "EngageDiffLock" ;
VAL_ 2348876577 DisengageDiffLockRqCentral 2 "Reserved" 3 "TakeNoAction" 1 "DisengageDiffLock" 0 "EngageDiffLock" ;
VAL_ 2348876577 DisengageDiffLockRqRearAxle2 2 "Reserved" 3 "TakeNoAction" 1 "DisengageDiffLock" 0 "EngageDiffLock" ;
VAL_ 2348876577 DisengageDiffLockRqRearAxle1 2 "Reserved" 3 "TakeNoAction" 1 "DisengageDiffLock" 0 "EngageDiffLock" ;
VAL_ 2348876577 DisengageDiffLockRqFrontAxle2 2 "Reserved" 3 "TakeNoAction" 1 "DisengageDiffLock" 0 "EngageDiffLock" ;
VAL_ 2348876577 DisengageDiffLockRqFrontAxle1 2 "Reserved" 3 "TakeNoAction" 1 "DisengageDiffLock" 0 "EngageDiffLock" ;
VAL_ 2348876577 TransRqedGear 61 "Reserved" 222 "NeutralSelectorPos" 223 "ReverseSelectorPos" 224 "PsUnknownAnd_OrNoButtonsPressed" 225 "PrssOfMmntryBttnTRslctCrrentPos" 226 "BtwnRvrsAndPrkShiftSelectorPoss" 227 "BtwnNtrlAndRvrsShftSelectorPoss" 228 "BtwnDrvAndNtrlShiftSelectorPoss" 229 "BtwnD1AndDriveShiftSelectorPoss" 230 "BetweenD2AndD1ShiftSelectorPoss" 231 "BetweenD3AndD2ShiftSelectorPoss" 232 "BetweenD4AndD3ShiftSelectorPoss" 233 "BetweenD5AndD4ShiftSelectorPoss" 234 "BetweenD6AndD5ShiftSelectorPoss" 235 "BetweenD7AndD6ShiftSelectorPoss" 236 "BtwnTwoForwardShiftSelectorPoss" 237 "BtwnTwoReverseShiftSelectorPoss" 238 "BetweenTwoShiftSelectorPoss" 239 "D77thFrwrdSlctrPsRfrncdFrmDrive" 240 "D66thFrwrdSlctrPsRfrncdFrmDrive" 241 "D55thFrwrdSlctrPsRfrncdFrmDrive" 242 "D44thFrwrdSlctrPsRfrncdFrmDrive" 243 "D33rdFrwrdSlctrPsRfrncdFrmDrive" 244 "D22ndFrwrdSlctrPsRfrncdFrmDrive" 245 "D11stFrwrdSlctrPsRfrncdFrmDrive" 246 "Downshift2GearsFromCurrentPos" 247 "Downshift1GearFromCurrentPos" 248 "Upshift2GearsFromCurrentPos" 249 "Upshift1GearFromCurrentPos" 250 "ForwardLowPos" 251 "ParkPos" 252 "ForwardDrivePos" 253 "HoldCurrentGear" ;
VAL_ 2348876577 DisengageDrivelineRq 2 "Reserved" 3 "TakeNoAction" 1 "DisengageDriveline" 0 "AllowDrivelineEngagement" ;
VAL_ 2348876577 TorqueConverterLockupDisableRq 2 "Reserved" 3 "TakeNoAction" 1 "DisableTorqueConvertorLockup" 0 "AllowTorqueConvertorLockup" ;
VAL_ 2348876577 TransGearShiftInhibitRq 2 "Reserved" 3 "TakeNoAction" 1 "GearShiftsAreInhibited" 0 "GearShiftsAreAllowed" ;
VAL_ 2631859966 EngBuildHoursReset 2 "Reserved" 3 "TakeNoAction" 1 "Reset" 0 "DoNotReset" ;
VAL_ 2631859966 TripGroup2Proprietary 2 "Reserved" 3 "NotApplicable" 1 "Reset" 0 "TakeNoAction" ;
VAL_ 2631859966 TripGroup1 2 "Reserved" 3 "NotApplicable" 1 "Reset" 0 "TakeNoAction" ;
VAL_ 2566840830 RetarderLocation 15 "NotAvailable" 14 "Other" 6 "1101NotDefined" 5 "Trailer" 4 "Driveline" 3 "TransOutput" 2 "TransInput" 1 "EngExhaustBrake" 0 "EngCompressionReleaseBrake" ;
VAL_ 2566840830 RetarderType 15 "NotAvailable" 14 "Other" 5 "1101NotDefined" 4 "Exhaust" 3 "CompressionRelease" 2 "CooledFriction" 1 "Hyd" 0 "Electric_Magnetic" ;
VAL_ 2566844670 EngPTOSetSwitch 3 "NotAvailable" 2 "Error" 1 "On" 0 "Off" ;
VAL_ 2566844670 EngPTOEnableSwitch 3 "NotAvailable" 2 "Error" 1 "On" 0 "Off" ;
VAL_ 2566801924 TransRevGearShiftInhibitStat 3 "not available" 2 "error" 1 "on" 0 "off" ;
VAL_ 2566801924 TransMode5Indicator 3 "NotAvailable" 2 "Error" 1 "TransMode5Active" 0 "TransMode5NotActive" ;
VAL_ 2566801924 TransMode6Indicator 3 "NotAvailable" 2 "Error" 1 "TransMode6Active" 0 "TransMode6NotActive" ;
VAL_ 2566801924 TransMode7Indicator 3 "NotAvailable" 2 "Error" 1 "TransMode7Active" 0 "TransMode7NotActive" ;
VAL_ 2566801924 TransMode8Indicator 3 "NotAvailable" 2 "Error" 1 "TransMode8Active" 0 "TransMode8NotActive" ;
VAL_ 2566801924 TransMode1Indicator 3 "NotAvailable" 2 "Error" 1 "TransMode1Active" 0 "TransMode1NotActive" ;
VAL_ 2566801924 TransMode2Indicator 3 "NotAvailable" 2 "Error" 1 "TransMode2Active" 0 "TransMode2NotActive" ;
VAL_ 2566801924 TransMode3Indicator 3 "NotAvailable" 2 "Error" 1 "TransMode3Active" 0 "TransMode3NotActive" ;
VAL_ 2566801924 TransMode4Indicator 3 "NotAvailable" 2 "Error" 1 "TransMode4Active" 0 "TransMode4NotActive" ;
VAL_ 2566801924 TransShiftInhibitIndicator 3 "TakeNoAction" 2 "Reserved" 1 "ActiveShiftIsInhibited" 0 "InactiveShiftIsNotInhibited" ;
VAL_ 2566801924 TransEngCrankEnable 3 "NotAvailable" 2 "Error" 1 "CrnkngEnbldEngCrnkngIsAllwdByTr" 0 "CrnkngDsbldEngCrnkngIsPrhbtdByT" ;
VAL_ 2566801924 ActiveShiftConsoleIndicator 3 "NotAvailable" 2 "Reserved" 1 "SecondShiftConsoleIsActive" 0 "PrimaryShiftConsoleIsActive" ;
VAL_ 2566801924 TransReadyForBrakeRelease 3 "DontCare" 2 "Reserved" 1 "TransReadyForBrakeRelease" 0 "TransNotReadyForBrakeRelease" ;
VAL_ 2566801924 TransRqedRangeDisplayFlashState 3 "TakeNoAction" 2 "Reserved" 1 "ActvTrnsRqdRngDsplyShldBFlshing" 0 "InctvTrnsRqdRngDsplyShldNtBFlsh" ;
VAL_ 2566801924 TransRqedRangeDisplayBlankState 3 "TakeNoAction" 2 "Reserved" 1 "ActvTrnsRqdRngDsplyShldBBlanked" 0 "InctvTrnsRqdRngDsplyShldNtBBlnk" ;
VAL_ 2566801924 TransServiceIndicator 3 "NotAvailable" 2 "ServiceIndicatorFlashing" 1 "ServiceIndicatorOn" 0 "SeviceIndicatorOff" ;
VAL_ 2566801924 TransCurrRangeDisplayBlankState 3 "NotSupported" 2 "Error" 1 "Blanked" 0 "NotBlanked" ;
VAL_ 2364539395 ProgressiveShiftDisable 2 "Reserved" 3 "TakeNoAction" 1 "ProgressiveShiftIsDisabled" 0 "ProgressiveShiftIsNotDisabled" ;
VAL_ 2364539395 EngMomentaryOverspeedEnable 2 "Reserved" 3 "TakeNoAction" 1 "MomentaryEngOverspeedIsEnabled" 0 "MomentaryEngOverspeedIsDisabled" ;
VAL_ 2364539395 TransShiftInProcess 3 "NotAvailable" 2 "Error" 1 "ShiftInProcess" 0 "ShiftIsNotInProcess" ;
VAL_ 2364539395 TorqueConverterLockupEngaged 3 "NotAvailable" 2 "Error" 1 "TorqueConverterLockupEngaged" 0 "TorqueConverterLockupDisengaged" ;
VAL_ 2364539395 TransDrivelineEngaged 3 "NotAvailable" 2 "Error" 1 "DrivelineEngaged" 0 "DrivelineDisengaged" ;
VAL_ 2565865475 RetarderRoadSpeedLimitSwitch 3 "not available" 2 "error" 1 "on" 0 "off" ;
VAL_ 2565865475 RetarderRoadSpeedExceedStatus 3 "not available" 2 "error" 1 "on" 0 "off" ;
VAL_ 2565865475 EngCoolantLoadIncrease 3 "NotAvailable" 2 "Error" 1 "CoolantLoadIncreasePossible" 0 "NoCoolantLoadIncrease" ;
VAL_ 2565865475 RetarderEnableShiftAssistSwitch 3 "NotAvailable" 2 "Error" 1 "RetarderShiftAssistEnabled" 0 "RetarderShiftAssistDisabled" ;
VAL_ 2565865475 RetarderEnableBrakeAssistSwitch 3 "NotAvailable" 2 "Error" 1 "RetarderBrakeAssistEnabled" 0 "RetarderBrakeAssistDisabled" ;
VAL_ 2566840064 AfterTr1IntDewPoint 3 "not available" 2 "error" 1 "on" 0 "off" ;
VAL_ 2566840064 AfterTr1ExhDewPoint 3 "not available" 2 "error" 1 "on" 0 "off" ;
VAL_ 2566840064 AfterTr2IntDewPoint 3 "not available" 2 "error" 1 "on" 0 "off" ;
VAL_ 2566840064 AfterTr2ExhDewPoint 3 "not available" 2 "error" 1 "on" 0 "off" ;
VAL_ 2364539648 VehicleAccelRateLimitStatus 3 "not available" 2 "error" 1 "on" 0 "off" ;
VAL_ 2364539648 AccelPedal2LowIdleSwitch 3 "NotAvailable" 2 "Error" 1 "AccelPedal2InLowIdleCondition" 0 "AcclPedal2NotInLowIdleCondition" ;
VAL_ 2364539648 RoadSpeedLimitStatus 3 "NotAvailable" 2 "Error" 1 "NotActive" 0 "Active" ;
VAL_ 2364539648 AccelPedalKickdownSwitch 3 "NotAvailable" 2 "Error" 1 "KickdownActive" 0 "KickdownPassive" ;
VAL_ 2364539648 AccelPedal1LowIdleSwitch 3 "NotAvailable" 2 "Error" 1 "AccelPedal1InLowIdleCondition" 0 "AcclPedal1NotInLowIdleCondition" ;
VAL_ 2364539904 EngStarterMode 15 "notAvailable" 14 "error" 12 "starterInhibitedReasonUnknown" 9 "1011Reserved" 8 "strtrInhbtdDueToStarterOvertemp" 7 "strtrInhbtdDToActiveImmobilizer" 6 "strtrInhbtdDTDrvlnEnggdOthrTrns" 5 "strtrInhbtdDTEngNtReadyForStart" 4 "strtrInhbtdDToEngAlreadyRunning" 3 "strtFnshdStrtrNtActvAftrHvngBnA" 2 "starterActiveGearEngaged" 1 "starterActiveGearNotEngaged" 0 "startNotRqed" ;
VAL_ 2364539904 EngTorqueMode0 15 "Not available" 11 "Remote accelerator" 10 "Braking system" 9 "High speed governor" 8 "Torque limiting" 7 "ABS control" 6 "Transmission control" 5 "ASR control" 4 "Road speed governor" 3 "PTO governor" 2 "Cruise control" 1 "Accelerator pedal/operator selec" 0 "Low idle governor/no request (de" ;
VAL_ 2566841342 SupportTSC1CtrlPurposeGroup4Of4 1 "P25ReservedForAssignmentBySAE" ;
VAL_ 2566841342 SupportVariableRateTSC1Message 1 "MsTransRate" ;
VAL_ 2566841342 SupportTSC1CtrlPurposeGroup3Of4 1 "P17ReservedForAssignmentBySAE" ;
VAL_ 2566841342 SupportTSC1CtrlPurposeGroup2Of4 1 "P9ReservedForAssignmentBySAE" ;
VAL_ 2566841342 SupportTSC1CtrlPurposeGroup1Of4 1 "P1AccelPedal_OperatorSelection" ;
VAL_ 2566767870 BrakeTempWarning 3 "notAvailable" 2 "Reserved" 1 "Active" 0 "NotActive" ;
VAL_ 2566767870 XBRActiveCtrlMode 15 "NotAvailable" 4 "1110ReservedForSAEAssignment" 3 "MxMdOfXBRAcclrtnCtrlBngExecuted" 2 "AddtnMdOfXBRAcclrtnCtrlBngExctd" 1 "DrvrsBrkDmndBngExctdNExtlBrkDmn" 0 "NoBrakeDemandBeingExecuted" ;
VAL_ 2566767870 XBRSystemState 3 "NotAvailable" 2 "NoExtlBrakeDemandWillBeAccepted" 1 "OnlyExtlBrkDmndOfHghstXBRPrrtyW" 0 "AnyExtlBrkeDemandWillBeAccepted" ;
VAL_ 2566767870 FoundationBrakeUse 3 "NotAvailable" 2 "Reserved" 1 "FoundationBrakesInUse" 0 "FoundationBrakesNotInUse" ;
VAL_ 2566767870 HillHolderMode 7 "NotAvailable" 6 "Reserved" 3 "101NotDefined" 2 "ActvBtWllChngTInctvInAShortTime" 1 "Active" 0 "Inactive" ;
VAL_ 2566767870 HaltBrakeMode 7 "NotAvailable" 6 "Reserved" 3 "101NotDefined" 2 "ActiveButNotFunctioningProperly" 1 "Active" 0 "Inactive" ;
VAL_ 2565865982 TrctrMntdTrilerABSWarningSignal 3 "TakeNoAction" 2 "Reserved" 1 "On" 0 "Off" ;
VAL_ 2565865982 TrailerABSStatus 3 "TrlrABSSttsInfrmtnNtAvlblPrmtrN" 2 "Reserved" 1 "TrailerABSActive" 0 "TrlrABSSttsInfrmtnAvlblBtNtActv" ;
VAL_ 2565865982 HaltBrakeSwitch 3 "NotAvailable" 2 "Error" 1 "HaltBrakeSwitchActive" 0 "HaltBrakeSwitchPassive" ;
VAL_ 2565865982 ATC_ASRInformationSignal 3 "TakeNoAction" 2 "Reserved" 1 "On" 0 "Off" ;
VAL_ 2565865982 ABS_EBSAmberWarningSignal 3 "TakeNoAction" 2 "Reserved" 1 "On" 0 "Off" ;
VAL_ 2565865982 EBSRedWarningSignal 3 "TakeNoAction" 2 "Reserved" 1 "On" 0 "Off" ;
VAL_ 2565865982 ABSFullyOperational 3 "NotAvailable" 2 "Reserved" 1 "FullyOperational" 0 "NotFullyOperational" ;
VAL_ 2565865982 RemoteAccelEnableSwitch 3 "NotAvailable" 2 "Error" 1 "On" 0 "Off" ;
VAL_ 2565865982 EngAuxEngShutdownSwitch 3 "NotAvailable" 2 "Error" 1 "On" 0 "Off" ;
VAL_ 2565865982 EngDerateSwitch 3 "NotAvailable" 2 "Error" 1 "On" 0 "Off" ;
VAL_ 2565865982 AccelInterlockSwitch 3 "NotAvailable" 2 "Error" 1 "On" 0 "Off" ;
VAL_ 2565865982 TractionCtrlOverrideSwitch 3 "NotAvailableNotInstalled" 2 "Error" 1 "On" 0 "Off" ;
VAL_ 2565865982 ASRHillHolderSwitch 3 "NotAvailable" 2 "Error" 1 "ASRHillHolderSwitchActive" 0 "ASRHillHolderSwitchPassive" ;
VAL_ 2565865982 ASROffroadSwitch 2 "Error" 1 "ASROffroadSwitchActive" 0 "ASROffroadSwitchPassive" 3 "NotAvailable" ;
VAL_ 2565865982 ABSOffroadSwitch 3 "NotAvailable" 2 "Error" 1 "ABSOffroadSwitchActive" 0 "ABSOffroadSwitchPassive" ;
VAL_ 2565865982 EBSBrakeSwitch 3 "NotAvailable" 2 "Error" 1 "BrakePedalIsBeingPressed" 0 "BrakePedalIsNotBeingPressed" ;
VAL_ 2565865982 AntiLockBrakingActive 3 "NotAvailable" 2 "Reserved" 1 "ABSActive" 0 "ABSPassiveButInstalled" ;
VAL_ 2565865982 ASRBrakeCtrlActive 3 "NotAvailable" 2 "Reserved" 1 "ASRBrakeCtrlActive" 0 "ASRBrakeCtrlPassiveButInstalled" ;
VAL_ 2565865982 ASREngCtrlActive 3 "NotAvailable" 2 "Reserved" 1 "ASREngCtrlActive" 0 "ASREngCtrlPassiveButInstalled" ;
VAL_ 2564872707 RqCabZoneHeating 3 "DontCare_TakeNoAction" 2 "Reserved" 1 "HeatCabZone" 0 "DoNotCabEngZone" ;
VAL_ 2564872707 RqEngZoneHeating 3 "DontCare_TakeNoAction" 2 "Reserved" 1 "HeatEngZone" 0 "DoNotHeatEngZone" ;
VAL_ 2564872707 AuxHeaterModeRq 15 "DontCare_TakeNoAction" 14 "Reserved" 4 "1101NotDefined" 3 "NormalMode" 2 "EconomyMode" 1 "OffDTADRPrErpnRgltnsFrTrnsprtOf" 0 "DeactivateAuxHeater" ;
VAL_ 2564872707 SeatBeltSwitch 3 "NotAvailable" 2 "ErrrSwtchStteCannotBeDetermined" 1 "OKSeatBeltIsBuckled" 0 "NOTBuckled" ;
VAL_ 2564872707 OperatorSeatDirectionSwitch 3 "NotAvailable" 2 "Error" 1 "OperatorSeatIsFacingForward" 0 "OperatorSeatNotFacingForward" ;
VAL_ 2564872707 BatteryMainSwitchHoldRq 3 "DontCare_TakeNoAction" 2 "undefined" 1 "HoldBatteryMainSwitch" 0 "ReleaseBatteryMainSwitch" ;
VAL_ 2564872707 AuxHeaterCoolantPumpRq 3 "DontCare_TakeNoAction" 2 "Reserved" 1 "ActivateWaterPump" 0 "DeactivateWaterPump" ;
VAL_ 2566844926 ParkBrakeReleaseInhibitRq 3 "Unavailable" 2 "SAEReserved" 1 "ParkBrakeReleaseInhibitRqed" 0 "ParkBrakeReleaseInhibitNotRqed" ;
VAL_ 2566844926 EngShutdownOverrideSwitch 3 "NotAvailable" 2 "Error" 1 "On" 0 "Off" ;
VAL_ 2566844926 EngTestModeSwitch 3 "NotAvailable" 2 "Error" 1 "On" 0 "Off" ;
VAL_ 2566844926 EngIdleDecrementSwitch 3 "NotAvailable" 2 "Error" 1 "On" 0 "Off" ;
VAL_ 2566844926 EngIdleIncrementSwitch 3 "NotAvailable" 2 "Error" 1 "On" 0 "Off" ;
VAL_ 2566844926 PtoGovernorState 31 "NotAvailable" 20 "11110NotDefined" 19 "PTOSetSpeedMemory2" 18 "PTOSetSpeedMemory1" 17 "PreprogrammedSetSpeed8" 16 "PreprogrammedSetSpeed7" 15 "PreprogrammedSetSpeed6" 14 "PreprogrammedSetSpeed5" 13 "PreprogrammedSetSpeed4" 12 "PreprogrammedSetSpeed3" 11 "PreprogrammedSetSpeed2" 10 "PreprogrammedSetSpeed1" 9 "AccelOverride" 8 "Accelerate" 7 "Resume" 6 "Decelerate_Coast" 5 "Set" 4 "RemoteStandby" 3 "Standby" 2 "RemoteHold" 1 "Hold" 0 "Off_Disabled" ;
VAL_ 2566844926 CruiseCtrlAccelerateSwitch 3 "NotAvailable" 2 "Error" 1 "CrsCtrlActivatorInPosAccelerate" 0 "CrsCtrlActvtrNotInPosAccelerate" ;
VAL_ 2566844926 CruiseCtrlResumeSwitch 3 "NotAvailable" 2 "Error" 1 "CruiseCtrlActivatorInPosResume" 0 "CrseCtrlActivatorNotInPosResume" ;
VAL_ 2566844926 CruiseCtrlCoastSwitch 3 "NotAvailable" 2 "Error" 1 "CruiseCtrlActivatorInPosCoast" 0 "CriseCtrlActivatorNotInPosCoast" ;
VAL_ 2566844926 CruiseCtrlSetSwitch 3 "NotAvailable" 2 "Error" 1 "CruiseCtrlActivatorInPosSet" 0 "CruiseCtrlActivatorNotInPosSet" ;
VAL_ 2566844926 ClutchSwitch 3 "NotAvailable" 2 "Error" 1 "ClutchPedalDepressed" 0 "ClutchPedalReleased" ;
VAL_ 2566844926 BrakeSwitch 3 "NotAvailable" 2 "Error" 1 "BrakePedalDepressed" 0 "BrakePedalReleased" ;
VAL_ 2566844926 CruiseCtrlEnableSwitch 3 "NotAvailable" 2 "Error" 1 "CruiseCtrlEnabled" 0 "CruiseCtrlDisabled" ;
VAL_ 2566844926 CruiseCtrlActive 3 "NotAvailable" 2 "Error" 1 "CruiseCtrlSwitchedOn" 0 "CruiseCtrlSwitchedOff" ;
VAL_ 2566844926 CruiseCtrlPauseSwitch 3 "TakeNoAction" 2 "ErrorIndicator" 1 "On" 0 "Off" ;
VAL_ 2566844926 ParkingBrakeSwitch 3 "NotAvailable" 2 "Error" 1 "ParkingBrakeSet" 0 "ParkingBrakeNotSet" ;
VAL_ 2566844926 TwoSpeedAxleSwitch 3 "NotAvailable" 2 "Error" 1 "HighSpeedRange" 0 "LowSpeedRange" ;
VAL_ 2566835710 EngTorqueMode1 15 "Not available" 11 "Remote accelerator" 10 "Braking system" 9 "High speed governor" 8 "Torque limiting" 7 "ABS control" 6 "Transmission control" 5 "ASR control" 4 "Road speed governor" 3 "PTO governor" 2 "Cruise control" 1 "Accelerator pedal/operator selec" 0 "Low idle governor/no request (de" ;
VAL_ 2566834944 MalfunctionIndicatorLampStatus 3 "Not available" 2 "Reserved" 1 "Lamp on" 0 "Lamp off" ;
VAL_ 2566834944 RedStopLampState 3 "Not available" 2 "Reserved" 1 "Lamp on" 0 "Lamp off" ;
VAL_ 2566834944 AmberWarningLampStatus 3 "Not available" 2 "Reserved" 1 "Lamp on" 0 "Lamp off" ;
VAL_ 2566834944 ProtectLampStatus 3 "Not available" 2 "Reserved" 1 "Lamp on" 0 "Lamp off" ;
VAL_ 2566834944 FlashRedStopLamp 3 "Unavailable / Do Not Flash" 2 "Reserved" 1 "Fast Flash" 0 "Slow Flash" ;
VAL_ 2566834944 FlashProtectLamp 3 "Unavailable / Do Not Flash" 2 "Reserved" 1 "Fast Flash" 0 "Slow Flash" ;
VAL_ 2566834944 FlashMalfuncIndicatorLamp 3 "Unavailable / Do Not Flash" 2 "Reserved" 1 "Fast Flash" 0 "Slow Flash" ;
VAL_ 2566834944 FlashAmberWarningLamp 3 "Unavailable / Do Not Flash" 2 "Reserved" 1 "Fast Flash" 0 "Slow Flash" ;
VAL_ 2564816638 HoldSignal 15 "Not available" 1 "Devices whose broadcast state ha" 0 "All devices" ;
VAL_ 2564816638 J1939Network3 3 "Don't care" 2 "Reserved" 1 "Start broadcast" 0 "Stop broadcast" ;
VAL_ 2564816638 J1939Network2 3 "Don't care" 2 "Reserved" 1 "Start broadcast" 0 "Stop broadcast" ;
VAL_ 2564816638 ISO9141 3 "Don't care" 2 "Reserved" 1 "Start broadcast" 0 "Stop broadcast" ;
VAL_ 2564816638 SAE_J1850 3 "Don't care" 2 "Reserved" 1 "Start broadcast" 0 "Stop broadcast" ;
VAL_ 2564816638 ManufacturerSpecificPort 3 "Don't care" 2 "Reserved" 1 "Start broadcast" 0 "Stop broadcast" ;
VAL_ 2564816638 CurrentDataLink 3 "Don't care" 2 "Reserved" 1 "Start broadcast" 0 "Stop broadcast" ;
VAL_ 2564816638 SAE_J1587 3 "Don't care" 2 "Reserved" 1 "Start broadcast" 0 "Stop broadcast" ;
VAL_ 2564816638 SAE_J1922 3 "Don't care" 2 "Reserved" 1 "Start broadcast" 0 "Stop broadcast" ;
VAL_ 2564816638 J1939Network1 3 "Don't care" 2 "Reserved" 1 "Start broadcast" 0 "Stop broadcast" ;
VAL_ 2564816638 SuspendSignal 15 "NotAvailable" 14 "ResumingNormalBroadcastPattern" 3 "TemporarySuspensionOfSomeMessages" 2 "TemporarySuspensionOfAllBroadcasts" 1 "IndefiniteSuspensionOfSomeMessages" 0 "IndefiniteSuspensionOfAllBroadcasts" ;
VAL_ 2565799678 ManufacturerCode 1863 "Thomas G. Faria Co." 1862 "Sanshin" 1861 "Vector CANtech" 1860 "MMP" 1859 "Kvasar AB" 1858 "Litton" 1857 "Simrad" 1856 "Trimble" 1855 "Furuno USA" 1854 "Northstar Technologies" 1853 "Japan Radio Co." 1852 "Navionics" 1851 "Raymarine" 1850 "Teleflex" 222 "Generac Power Systems, Inc." 221 "SiE" 220 "Beede Electrical Instrument Company, Inc." 219 "Cat OEM Solutions" 218 "Gits Manufacturing Company" 217 "RM Michaelides Software & Elektronik GmbH" 216 "Paneltronics Inc." 215 "Aetna Engineering/Fireboy-Xintex" 214 "MC elettronica Srl" 213 "CNH Belgium N.V." 212 "Sure Power Industries, Inc." 211 "DNA Group" 210 "Iteris, Inc." 209 "Bell Equip. Co. SA (PTY) LTD" 208 "Drew Technologies, Inc." 207 "Otto Engineering" 206 "port GmbH" 205 "SmarTire Systems Inc" 204 "The Morey Corporation" 203 "MILtronik GmbH" 202 "Curtis Instruments, Inc." 201 "Disenos y Tecnologia S.A." 200 "MGM Brakes" 199 "Actia Corp." 198 "Mystic Valley Communications" 197 "Mechron Power Systems" 196 "LEMKEN GmbH & Co. KG" 195 "General Engine Products" 194 "TriMark Corporation" 193 "Jeppesen Marine" 192 "Floscan" 191 "XATA Corporation" 190 "Hella KGaA Hueck & Co." 189 "QUALCOMM" 188 "EMP Corp." 187 "Air-Weigh" 186 "Altronic, Inc." 185 "Beede Electrical Instrument Company" 184 "EIA Electronics" 183 "KDS Controls, Inc." 182 "Vehicle Systems Engineering B.V." 181 "Coretronics, Inc." 180 "Smart Power Systems" 179 "Midwest Technologies Illinois, LLC" 178 "Siemens VDO Automotive AG" 177 "Diagnostic System Associates" 176 "Moritz Aerospace" 175 "Veris Technologies, Inc." 174 "AB Volvo Penta" 173 "Ryeso, Inc." 172 "Yanmar Marine USA" 171 "Wachendorff Elektronik GmbH & Co. KG" 170 "Computronics Corporation Ltd." 169 "Marlin Technologies Inc." 168 "Xantrex" 167 "JLG Industries Inc." 166 "Phoenix International" 165 "CPAC Systems AB" 164 "DaimlerChrysler Off-Highway" 163 "BRP Inc." 162 "Axiomatic Technologies" 161 "Offshore Systems (UK) Limited" 160 "Nido" 159 "NTech Industries Inc." 158 "Firestone Industrial Products Company" 157 "ISSPRO Inc." 156 "ITT Industries - Cannon" 155 "Vetronix Corporation" 154 "Westerbeke Corporation" 153 "Woodward, Industrial Controls Division" 152 "Elobau Elektrobauelemente GmbH & Co. KG" 151 "Raven Industries Inc. - Flow Controls Division" 150 "Fleetguard" 149 "Holset" 148 "Blue Water Data, Inc." 147 "Nautibus Electronic GmbH" 146 "Maxima Technologies" 145 "MurCal Controls" 144 "Mercury Marine" 143 "W. Gmeiner GmbH & Co." 142 "TRW Automotive (Commercial Steering Systems)" 141 "Thales Navigation Ltd." 140 "Lowrance Electronics, Inc." 139 "Caterpillar Trimble Control Technologies (CTCT), LLC" 138 "Georg Fritzmeier GmbH & Co. KG" 137 "Maretron" 136 "Komatsu Ltd." 135 "Airmar Technology Corporation" 134 "Iris Technology Ltd." 133 "Bucher Schoerling GmbH" 132 "Mulag-Fahrzeugwerk" 131 "ITT Industries" 130 "Nido - Universal Machines B.V." 129 "OMNEX Control Systems, Inc." 128 "Gerhard Duecker GmbH & Co. KG" 127 "Holland USA" 126 "Driver Tech" 125 "Nevada Automotive Test Center" 124 "Hydac Electronic" 123 "Basler Electric" 122 "FG Wilson (Engineering) Limited" 121 "HED (Hydro Electronic Devices, Inc.)" 120 "RDS Technology Ltd." 119 "IntegriNautics" 118 "Intron GmbH" 117 "HUSCO International" 116 "BEELINE Technologies" 115 "NACCO Materials Handling Group, Inc." 114 "EControls, Inc." 113 "Stress-Tek, Inc." 112 "MECALAC" 111 "Maschinenfabrik Bernhard Krone GmbH" 110 "EPIQ Sensor-Nite" 109 "LH Technologies ApS" 108 "WTK-Elecktronik GmbH" 107 "Grimme Landmaschinen GmbH & Co. KG" 106 "BAE Systems Controls, Inc." 105 "Kiepe Elektrik GmbH & Co. KG" 104 "Claas Selbstfahrende Erntemaschinen GmbH" 103 "Agrocom GmbH & Co. Agrarsystem KG" 102 "AGCO GmbH & Co." 101 "Sensoria" 100 "VDO Technik AG" 99 "International Transmissions Ltd (ITL)" 98 "Mueller-Elektronik GmbH & Co." 97 "Ag Leader Technology, Inc." 96 "Mech@tronic IT GmbH" 95 "Pacific Insight Electronics Corp." 94 "CNH Global N.V." 93 "Perkins Engines Company Ltd." 92 "Ag-Chem Equipment Co., Inc." 91 "BSG Bodensee Steuergeraete GmbH" 90 "Knorr-Bremse SfN GmbH" 89 "Kverneland Group, Electronics Division" 88 "Satloc Precision GPS" 87 "J.C. Bamford Excavators Ltd (JCB)" 86 "C.E. Niehoff & Company" 85 "Kohler Co." 84 "New Holland UK Limited" 83 "Eaton VORAD Technologies" 82 "Bobcat/Ingersoll-Rand" 81 "Fire Research Corp" 80 "Twin Disc, Inc." 79 "Daimler Benz AG - Engine Division (PBM)" 78 "Frank W. Murphy Manufacturing, Inc." 77 "Deere Power Systems Group" 76 "unused" 75 "Deere & Co. Agricultural Division" 74 "Eaton Axle-Brake Division" 73 "LeTourneau, Inc." 72 "Sisu Corporation" 71 "Vansco Electronics Ltd." 70 "Flex-Coil Limited" 69 "Trimble Navigation" 68 "Scania" 67 "Funk Manufacturing Company" 66 "John Deere Construction Equipment Division" 65 "MAN Nutzfahrzeuge AG" 64 "unused" 63 "ZF Industries Inc." 62 "Wabco" 61 "Volvo Truck Corp." 60 "Volvo Trucks North America Inc." 59 "VES Inc." 58 "SPX Corporation, OTC Division" 57 "Sauer-Danfoss Co." 56 "SAIC" 55 "Ryder System Inc." 54 "Meritor Wabco" 53 "Rockwell Land Transportation" 52 "Meritor Automotive, Inc." 51 "Robert Bosch GmbH" 50 "Robert Bosch Corp" 49 "RE America Inc." 48 "Pollak Alphabet" 47 "Phillips Semiconductor" 46 "Parasoft Computing Solutions" 45 "PACCAR" 44 "Nippondenso Co. Ltd." 43 "International Truck and Engine Corp. Vehicle Electronics" 42 "International Truck and Engine Corp. Engine Electronics" 41 "Motorola Inc." 40 "Motorola AIEG Inc." 39 "Microfirm Inc." 38 "Micro Processor Systems Inc." 37 "Mack Trucks Inc." 36 "Lucas Ltd." 35 "Kenworth Truck Co." 34 "Kelsey Hayes Co." 33 "John Deere" 32 "Jacobs Vehicle Systems" 31 "J Pollak Corp." 30 "Isuzu Motors Ltd." 29 "Hino Motors Ltd." 28 "Grote Ind. Inc." 27 "GMC" 26 "General Motors Corp., Service Technology Group" 25 "Freightliner LLC" 24 "Ford Motor Co., Vehicle Controls" 23 "Ford Motor Co., Heavy Truck" 22 "Ford Motor Co., Electronic Concepts $ Systems" 21 "Echilin Inc., Midland Brake Inc." 20 "Eaton Ltd" 19 "Eaton Corp. Trucking Info Services" 18 "Eaton Corp, Transmission Division" 17 "Eaton Corp. Res & Dev" 16 "Eaton Corp." 15 "Dickey-John Corp." 14 "Detroit Diesel Corporation" 13 "Delco Electronics" 12 "Deere & Company, Precision Farming" 11 "Dearborn Group Inc." 10 "Cummins Engine Co." 9 "Chrysler Corp." 8 "Caterpillar Inc." 7 "Case Corp." 6 "Berifors Electronics AB" 5 "AMP Inc." 4 "Ametek-Dixson" 3 "Ametek, US Gauge Division" 2 "Allison Transmission, GMC" 1 "Allied Signal Inc." 0 "Reserved" ;
VAL_ 2565799678 IndustryGroup 6 "Reserved for SAE" 7 "Reserved for SAE" 5 "IndustrialProcessCtrlStationary" 4 "Marine" 3 "Construction" 2 "Agricultural and Forestry" 1 "On-Highway" 0 "Global" ;
VAL_ 2565799678 Function 127 "Reserved" 126 "Reserved" 125 "Reserved" 124 "Reserved" 123 "Reserved" 122 "Reserved" 121 "Reserved" 120 "Reserved" 119 "Reserved" 118 "Reserved" 117 "Reserved" 116 "Reserved" 115 "Reserved" 114 "Reserved" 113 "Reserved" 112 "Reserved" 111 "Reserved" 110 "Reserved" 109 "Reserved" 108 "Reserved" 107 "Reserved" 106 "Reserved" 105 "Reserved" 104 "Reserved" 103 "Reserved" 102 "Reserved" 101 "Reserved" 42 "Water Pump Control" 41 "Lighting - Operator Controls" 40 "Seat Control" 39 "Ignition Control Module" 38 "Tire Pressure Control" 37 "Cab Controller" 36 "Pneumatic - System Controller" 35 "Suspension - System Controller" 34 "Hydraulic Pump Controller" 33 "System Monitor" 32 "Headway Controller" 31 "Propulsion Battery Charger" 30 "Management Computer" 29 "Virtual Terminal (In Cab)" 28 "Off Vehicle Gateway" 27 "Power TakeOff (Secondary or Front)" 26 "Body Controller" 25 "Network Interconnect ECU" 24 "Vehicle Security" 23 "Vehicle Navigation" 22 "Aerodynamic Control" 21 "Cab Climate Control" 20 "Trip Recorder" 19 "Instrument Cluster" 18 "Suspension - Drive Axle" 17 "Suspension - Steer Axle" 16 "Steeting Controller" 15 "Fuel System" 14 "Cruise Control" 13 "Retarder - Driveline" 12 "Retarder - Engine" 11 "Brakes - Drive Axle" 10 "Brakes - Steer Axle" 9 "Brakes - System Controller" 8 "Axle - Drive" 7 "Axle - Steering" 6 "Power TakeOff - (Main or Rear)" 5 "Shift Control/Console" 4 "Battery Pack Monitor" 3 "Transmission" 2 "Electric Propulsion Control" 1 "Auxiliary Power Unit (APU)" 0 "Engine" 100 "Reserved" 99 "Reserved" 98 "Reserved" 97 "Reserved" 96 "Reserved" 95 "Reserved" 94 "Reserved" 93 "Reserved" 92 "Reserved" 91 "Reserved" 90 "Reserved" 89 "Reserved" 88 "Reserved" 87 "Reserved" 86 "Reserved" 85 "Reserved" 84 "Reserved" 83 "Reserved" 82 "Reserved" 81 "Reserved" 80 "Reserved" 79 "Reserved" 78 "Reserved" 77 "Reserved" 76 "Reserved" 75 "Reserved" 74 "Reserved" 73 "Reserved" 72 "Coolant Valve Controller" 71 "Transfer Case Control" 70 "Auxiliary Regeneration Device" 69 "Engine Emission Aftertreatement System" 68 "Aftertreatment system gas measurement" 67 "Electrical System Controller" 66 "I/O Controller" 65 "Gas Flow Measurement" 64 "Endurance Braking" 63 "Engine Valve Controller" 62 "On-Board Diagnostic Unit" 61 "File Server/Printer" 60 "Cab Display" 59 "Starter" 58 "Fan Drive Control" 57 "Steering Column Unit" 56 "Communications Unit, Radio" 55 "Communications Unit, Satellite" 54 "Communications Unit, Cellular" 53 "Alternator/Charging System" 52 "Chassis Controller" 51 "Forward-Looking Collision Warning System" 50 "Auxiliary Heater" 49 "Clutch/Converter Control" 48 "Ramp Control" 47 "Information System Controller" 46 "Oil Sensor Unit" 45 "Vehicle Dynamic Stability Control" 44 "Exhaust Emission Control" 43 "Transmission Display" ;
VAL_ 2565799678 VehicleSystem 0 "Non-specific System" 127 "Not Available" ;
VAL_ 2565799678 VehicleSystem5 127 "Not Available" 0 "Ind. Process Control Stationary" ;
VAL_ 2565799678 VehicleSystem4 100 "Deck/Cargo/Fishing equip. sys" 90 "Environmental (HVAC) Systems" 80 "Instrumentation/General Systems" 70 "Communications Systems" 60 "Navigation Systems" 50 "Propulsion Systems" 40 "Steering Systems" 30 "Power Mgmt and lighting systems" 25 "Gateway" 20 "Safety Systems" 10 "System Tools" 127 "Not Available" 0 "Non-specific System" ;
VAL_ 2565799678 VehicleSystem3 8 "Grader" 7 "Four Wheel Drive Loader" 6 "Forklift" 5 "Excavator" 4 "Crawler" 3 "Backhoe" 2 "Articulated Dump Truck" 1 "Skid Steer Loader" 127 "Not Available" 0 "Non-specific System" ;
VAL_ 2565799678 VehicleSystem2 16 "Skidder" 15 "Earth Work" 14 "Special Crops" 13 "Powered Auxiliary Device" 12 "Farm Yard Operations" 11 "Transport/Trailer" 10 "Irrigation" 9 "Forage" 8 "Root Harvesters" 7 "Harvesters" 6 "Sprayers" 5 "Fertilizers" 4 "Planters/Seeders" 3 "Secondary Tillage" 2 "Tillage" 1 "Tractor" 127 "Not Available" 0 "Non-specific System" ;
VAL_ 2565799678 VehicleSystem1 2 "Trailer" 1 "Tractor" 127 "Not Available" 0 "Non-specific System" ;
VAL_ 2565668606 PGNumber 255 "NotAvailable" ;
VAL_ 2565668606 ControlByte 24 "EAbort" 23 "EEoMACK" 22 "EDPO" 21 "ECTS" 20 "ERTS" 255 "Abort" 32 "BAM" 19 "EoMA" 17 "CTS" 16 "RTS" ;
VAL_ 2566838561 AuxIo16_ED55 3 "not available" 2 "error" 1 "on" 0 "off" ;
VAL_ 2566838561 AuxIo15_ED54 3 "not available" 2 "error" 1 "on" 0 "off" ;
VAL_ 2566838561 AuxIo14_ED53 3 "not available" 2 "error" 1 "on" 0 "off" ;
VAL_ 2566838561 AuxIo13_ED52 3 "not available" 2 "error" 1 "on" 0 "off" ;
VAL_ 2566838561 AuxIo11_ED50 3 "not available" 2 "error" 1 "on" 0 "off" ;
VAL_ 2566838561 AuxIo10_ED49 3 "not available" 2 "error" 1 "on" 0 "off" ;
VAL_ 2566838561 AuxIo09_ED48 3 "not available" 2 "error" 1 "on" 0 "off" ;
VAL_ 2566838561 AuxIo08_ED47 3 "not available" 2 "error" 1 "on" 0 "off" ;
VAL_ 2566838561 AuxIo07_ED46 3 "not available" 2 "error" 1 "on" 0 "off" ;
VAL_ 2566838561 AuxIo06_KampschalterEin 3 "not available" 2 "error" 1 "on" 0 "off" ;
VAL_ 2566838561 AuxIo12_ED51 3 "not available" 2 "error" 1 "on" 0 "off" ;
VAL_ 2566838561 AuxIo05_AVGInLow 3 "not available" 2 "error" 1 "on" 0 "off" ;
VAL_ 2566838561 AuxIo04_FahrprogUmsch2 3 "not available" 2 "error" 1 "on" 0 "off" ;
VAL_ 2566838561 AuxIo03_FahrprogUmsch1 3 "not available" 2 "error" 1 "on" 0 "off" ;
VAL_ 2566838561 AuxIo02_JetKupplungSchliessen 3 "not available" 2 "error" 1 "on" 0 "off" ;
VAL_ 2566838561 AuxIo01_HydroFahren 3 "not available" 2 "error" 1 "on" 0 "off" ;
VAL_ 2432593918 ACCDistanceAlertSignal 3 "TakeNoAction" 2 "Reserved" 1 "ACCDASActive" 0 "ACCDASNotActive" ;
VAL_ 2432593918 ACCSystemShutoffWarning 3 "TakeNoAction" 2 "Reserved" 1 "ACCSSOWActive" 0 "ACCSSOWNotActive" ;
VAL_ 2432593918 ACCTargetDetected 3 "TakeNoAction" 2 "Reserved" 1 "TargetDetected" 0 "NoTargetsDetected" ;
VAL_ 2432593918 AdptveCruiseCtrlSetDistanceMode 7 "NotAvailable_NotValid" 6 "ErrorCondition" 5 "ConventionalCruiseCtrlMode" 4 "ACCDistanceMode5" 3 "ACCDistanceMode4" 2 "ACCDistanceMode3" 1 "ACCDistanceMode2" 0 "ACCDistanceMode1" ;
VAL_ 2432593918 AdaptiveCruiseCtrlMode 7 "NotAvailable_NotValid" 6 "DsbldErrrCndtnUsdTIndctThtACCIs" 5 "FinishMode" 4 "HldMdUsdTIndctThtACCHsLstThPrvs" 3 "OvertakeMode" 2 "DstncCtrlActvUsdTIndctThtACCIsO" 1 "SpeedCtrlActive" 0 "OffUsdTIndctACCIsEnbldInClbCnfg" ;
VAL_ 2565406462 AckNack 3 "CannotRespond" 2 "AccessDenied" 1 "NACK" 0 "ACK" ;
VAL_ 2566846467 TransOilLevelMeasurementStatus 15 "NotAvailable" 14 "Error" 13 "ConditionsNotValidOther" 12 "NotDefined" 8 "CndtionsNotValidEngSpeedTooHigh" 7 "CnditionsNotValidEngSpeedTooLow" 6 "CndtionsNotValidVehicleNotLevel" 5 "CndtnsNtVldVhclMvngOtptShftSpdT" 4 "CndtnsNtVldTrnsFluidTempTooHigh" 3 "CndtnsNtVldTransFluidTempTooLow" 2 "ConditionsNotValidTransInGear" 1 "CndtnsNtVldSttlngTmrStllCntngDw" 0 "CndtnsVldFrTrnsOlLvlMeasurement" ;
VAL_ 2566846467 TransOilLevelCountdownTimer 15 "NotAvailable" 14 "Error" 13 "ThirteenMinutes" 12 "TwelveMinutes" 11 "ElevenMinutes" 10 "TenMinutes" 9 "NineMinutes" 8 "EightMinutes" 7 "SevenMinutes" 6 "SixMinutes" 5 "FiveMinutes" 4 "FourMinutes" 3 "ThreeMinutes" 2 "TwoMinutes" 1 "OneMinute" 0 "lessThan1Minute" ;
